VERSION "HNNBNNNYNNNNNNNNNNNNNNNNNNNNNNNNNNNNNNNNNN/4/%%%/4/'%**4NNN///"

NS_ :

BS_:

BU_: Aero_LB AFS_MLB Airbag_B8 BCM1_B8 Gateway_B8 Getriebe_AL551_651_B8 Getriebe_AL551_Q5_Hybrid Getriebe_SL_LB Lift_MLB_LB LWR_MLB Magnetic_Ride_LB Motor_MLB_AU48_AU416_Diesel Motor_MLB_B8_Q5_Otto Motor_MLB_Q5_Hybrid Niveau_LB Airbag_D4 BMS_Hybrid Daempfer_MLB EPB_MLB ESP Gateway Getriebe_AL551_951_D4_C7 Getriebe_AL551_Hybrid_D4_C7 Getriebe_DL382_MLB Getriebe_DL501_MLB Getriebe_VL381_MLB LEH_Hybrid LWS_D4 Motor2_MLB_D4_C7 Motor_MLB_AU64_AU57_Diesel Motor_MLB_BY_Otto Motor_MLB_C7_PHEV Motor_MLB_D4_C7_Hybrid Motor_MLB_D4_C7_Otto QSP SAK SAK2 SCR_MLB SCU

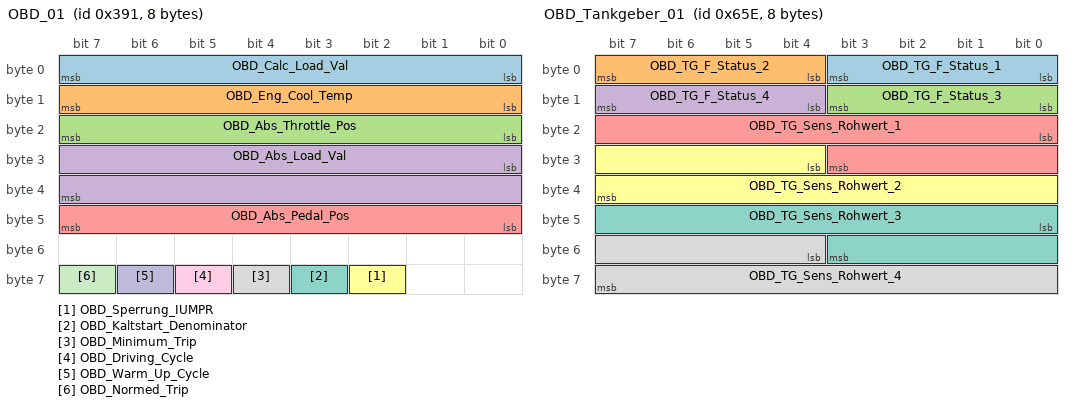
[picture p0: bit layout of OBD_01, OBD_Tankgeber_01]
BO_ 913 OBD_01: 8 Motor_MLB_AU64_AU57_Diesel
 SG_ OBD_Calc_Load_Val : 0|8@1+ (0.392156862745098,0) [0|100] "Unit_PerCent"  BMS_Hybrid,Gateway,Getriebe_AL551_951_D4_C7,Getriebe_AL551_Hybrid_D4_C7,Getriebe_DL382_MLB,Getriebe_DL501_MLB,Getriebe_VL381_MLB,LEH_Hybrid
 SG_ OBD_Eng_Cool_Temp : 8|8@1+ (1,-40) [-40|215] "Unit_DegreCelsi"  BMS_Hybrid,Gateway,Getriebe_AL551_951_D4_C7,Getriebe_AL551_Hybrid_D4_C7,Getriebe_DL382_MLB,Getriebe_DL501_MLB,Getriebe_VL381_MLB,LEH_Hybrid
 SG_ OBD_Abs_Throttle_Pos : 16|8@1+ (0.392156862745098,0) [0|100] "Unit_PerCent"  BMS_Hybrid,Gateway,Getriebe_AL551_951_D4_C7,Getriebe_AL551_Hybrid_D4_C7,Getriebe_DL382_MLB,Getriebe_DL501_MLB,Getriebe_VL381_MLB,LEH_Hybrid
 SG_ OBD_Abs_Load_Val : 24|16@1+ (0.392156862745098,0) [0|25700] "Unit_PerCent"  BMS_Hybrid,Gateway,Getriebe_AL551_951_D4_C7,Getriebe_AL551_Hybrid_D4_C7,Getriebe_DL382_MLB,Getriebe_DL501_MLB,Getriebe_VL381_MLB,LEH_Hybrid
 SG_ OBD_Abs_Pedal_Pos : 40|8@1+ (0.392156862745098,0) [0|100] "Unit_PerCent"  BMS_Hybrid,Gateway,Getriebe_AL551_951_D4_C7,Getriebe_AL551_Hybrid_D4_C7,Getriebe_DL382_MLB,Getriebe_DL501_MLB,Getriebe_VL381_MLB,LEH_Hybrid
 SG_ OBD_Sperrung_IUMPR : 58|1@1+ (1,0) [0|1] ""  BMS_Hybrid,Gateway,Getriebe_AL551_951_D4_C7,Getriebe_AL551_Hybrid_D4_C7,Getriebe_DL382_MLB,Getriebe_DL501_MLB,Getriebe_VL381_MLB,LEH_Hybrid
 SG_ OBD_Kaltstart_Denominator : 59|1@1+ (1,0) [0|1] ""  BMS_Hybrid,Gateway,LEH_Hybrid
 SG_ OBD_Minimum_Trip : 60|1@1+ (1,0) [0|1] ""  BMS_Hybrid,Gateway,Getriebe_AL551_951_D4_C7,Getriebe_AL551_Hybrid_D4_C7,Getriebe_DL382_MLB,Getriebe_DL501_MLB,Getriebe_VL381_MLB,LEH_Hybrid
 SG_ OBD_Driving_Cycle : 61|1@1+ (1,0) [0|1] ""  BMS_Hybrid,Gateway,Getriebe_AL551_951_D4_C7,Getriebe_AL551_Hybrid_D4_C7,Getriebe_DL382_MLB,Getriebe_DL501_MLB,Getriebe_VL381_MLB,LEH_Hybrid
 SG_ OBD_Warm_Up_Cycle : 62|1@1+ (1,0) [0|1] ""  BMS_Hybrid,Gateway,Getriebe_AL551_951_D4_C7,Getriebe_AL551_Hybrid_D4_C7,Getriebe_DL382_MLB,Getriebe_DL501_MLB,Getriebe_VL381_MLB,LEH_Hybrid
 SG_ OBD_Normed_Trip : 63|1@1+ (1,0) [0|1] ""  Gateway,Getriebe_AL551_951_D4_C7,Getriebe_AL551_Hybrid_D4_C7,Getriebe_DL382_MLB,Getriebe_DL501_MLB,Getriebe_VL381_MLB,LEH_Hybrid

BO_ 1630 OBD_Tankgeber_01: 8 Gateway
 SG_ OBD_TG_F_Status_1 : 0|4@1+ (1,0) [0|15] ""  Motor_MLB_AU64_AU57_Diesel,Motor_MLB_BY_Otto,Motor_MLB_C7_PHEV,Motor_MLB_D4_C7_Hybrid,Motor_MLB_D4_C7_Otto
 SG_ OBD_TG_F_Status_2 : 4|4@1+ (1,0) [0|15] ""  Motor_MLB_AU64_AU57_Diesel,Motor_MLB_BY_Otto,Motor_MLB_C7_PHEV,Motor_MLB_D4_C7_Hybrid,Motor_MLB_D4_C7_Otto
 SG_ OBD_TG_F_Status_3 : 8|4@1+ (1,0) [0|15] ""  Motor_MLB_AU64_AU57_Diesel,Motor_MLB_BY_Otto,Motor_MLB_C7_PHEV,Motor_MLB_D4_C7_Hybrid,Motor_MLB_D4_C7_Otto
 SG_ OBD_TG_F_Status_4 : 12|4@1+ (1,0) [0|15] ""  Motor_MLB_AU64_AU57_Diesel,Motor_MLB_BY_Otto,Motor_MLB_C7_PHEV,Motor_MLB_D4_C7_Hybrid,Motor_MLB_D4_C7_Otto
 SG_ OBD_TG_Sens_Rohwert_1 : 16|12@1+ (0.5,0) [0|2047.5] "Unit_Ohm"  Motor_MLB_AU64_AU57_Diesel,Motor_MLB_BY_Otto,Motor_MLB_C7_PHEV,Motor_MLB_D4_C7_Hybrid,Motor_MLB_D4_C7_Otto
 SG_ OBD_TG_Sens_Rohwert_2 : 28|12@1+ (0.5,0) [0|2047.5] "Unit_Ohm"  Motor_MLB_AU64_AU57_Diesel,Motor_MLB_BY_Otto,Motor_MLB_C7_PHEV,Motor_MLB_D4_C7_Hybrid,Motor_MLB_D4_C7_Otto
 SG_ OBD_TG_Sens_Rohwert_3 : 40|12@1+ (0.5,0) [0|2047.5] "Unit_Ohm"  Motor_MLB_AU64_AU57_Diesel,Motor_MLB_BY_Otto,Motor_MLB_C7_PHEV,Motor_MLB_D4_C7_Hybrid,Motor_MLB_D4_C7_Otto
 SG_ OBD_TG_Sens_Rohwert_4 : 52|12@1+ (0.5,0) [0|2047.5] "Unit_Ohm"  Motor_MLB_AU64_AU57_Diesel,Motor_MLB_BY_Otto,Motor_MLB_C7_PHEV,Motor_MLB_D4_C7_Hybrid,Motor_MLB_D4_C7_Otto

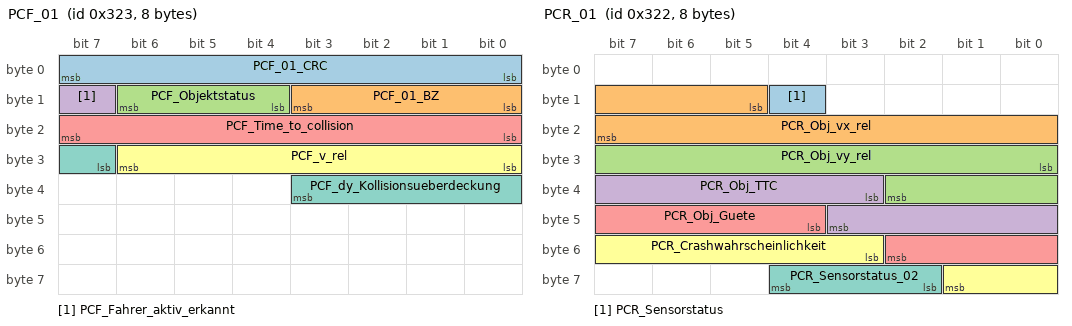
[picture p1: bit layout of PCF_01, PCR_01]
BO_ 803 PCF_01: 8 Gateway
 SG_ PCF_01_CRC : 0|8@1+ (1,0) [0|255] ""  Airbag_D4
 SG_ PCF_01_BZ : 8|4@1+ (1,0) [0|15] ""  Airbag_D4
 SG_ PCF_Objektstatus : 12|3@1+ (1,0) [0|7] ""  Airbag_D4
 SG_ PCF_Fahrer_aktiv_erkannt : 15|1@1+ (1,0) [0|1] "" Vector__XXX
 SG_ PCF_Time_to_collision : 16|8@1+ (0.01,0) [0|2.5] "Unit_Secon"  Airbag_D4
 SG_ PCF_v_rel : 24|7@1+ (0.5,0) [0.5|63.5] "Unit_MeterPerSecon"  Airbag_D4
 SG_ PCF_dy_Kollisionsueberdeckung : 31|5@1+ (0.1,0) [0.1|2.9] "Unit_Meter" Vector__XXX

BO_ 802 PCR_01: 8 Gateway
 SG_ PCR_Sensorstatus : 12|1@1+ (1,0) [0|1] ""  Airbag_D4
 SG_ PCR_Obj_vx_rel : 13|11@1+ (0.1,-102.3) [-102.3|102.3] "Unit_MeterPerSecon"  Airbag_D4
 SG_ PCR_Obj_vy_rel : 24|11@1+ (0.1,-102.3) [-102.3|102.3] "Unit_MeterPerSecon"  Airbag_D4
 SG_ PCR_Obj_TTC : 35|9@1+ (0.01,0) [0|5.1] "Unit_Secon"  Airbag_D4
 SG_ PCR_Obj_Guete : 44|7@1+ (1,0) [0|100] "Unit_PerCent"  Airbag_D4
 SG_ PCR_Crashwahrscheinlichkeit : 51|7@1+ (1,0) [0|100] "Unit_PerCent"  Airbag_D4
 SG_ PCR_Sensorstatus_02 : 58|3@1+ (1,0) [0|7] "" Vector__XXX

BO_ 929 PSD_01: 8 Gateway
 SG_ PSD_Pos_Segment_ID : 0|6@1+ (1,0) [2|63] ""  Getriebe_AL551_951_D4_C7,Getriebe_AL551_Hybrid_D4_C7,Getriebe_DL382_MLB,Getriebe_DL501_MLB,Getriebe_VL381_MLB,Motor_MLB_C7_PHEV,Motor_MLB_D4_C7_Hybrid,Motor_MLB_D4_C7_Otto
 SG_ PSD_Pos_Segmentlaenge : 6|7@1+ (2,0) [0|254] "Unit_Meter"  Getriebe_AL551_951_D4_C7,Getriebe_AL551_Hybrid_D4_C7,Getriebe_DL382_MLB,Getriebe_DL501_MLB,Getriebe_VL381_MLB,Motor_MLB_C7_PHEV,Motor_MLB_D4_C7_Hybrid,Motor_MLB_D4_C7_Otto
 SG_ PSD_Pos_Inhibitzeit : 13|5@1+ (10,0) [0|310] "Unit_MilliSecon"  Getriebe_AL551_951_D4_C7,Getriebe_AL551_Hybrid_D4_C7,Getriebe_DL382_MLB,Getriebe_DL501_MLB,Getriebe_VL381_MLB,Motor_MLB_C7_PHEV,Motor_MLB_D4_C7_Hybrid,Motor_MLB_D4_C7_Otto
 SG_ PSD_Pos_Standort : 18|1@1+ (1,0) [0|1] ""  Getriebe_AL551_951_D4_C7,Getriebe_AL551_Hybrid_D4_C7,Getriebe_DL382_MLB,Getriebe_DL501_MLB,Getriebe_VL381_MLB,Motor_MLB_C7_PHEV,Motor_MLB_D4_C7_Hybrid,Motor_MLB_D4_C7_Otto
 SG_ PSD_Pos_Laengsfehler : 19|3@1+ (1,0) [0|7] ""  Getriebe_AL551_951_D4_C7,Getriebe_AL551_Hybrid_D4_C7,Getriebe_DL382_MLB,Getriebe_DL501_MLB,Getriebe_VL381_MLB,Motor_MLB_C7_PHEV,Motor_MLB_D4_C7_Hybrid,Motor_MLB_D4_C7_Otto
 SG_ PSD_Segment_ID : 22|6@1+ (1,0) [2|63] ""  Getriebe_AL551_951_D4_C7,Getriebe_AL551_Hybrid_D4_C7,Getriebe_DL382_MLB,Getriebe_DL501_MLB,Getriebe_VL381_MLB,Motor_MLB_C7_PHEV,Motor_MLB_D4_C7_Hybrid,Motor_MLB_D4_C7_Otto
 SG_ PSD_Vorgaenger_Segment_ID : 28|6@1+ (1,0) [2|63] ""  Getriebe_AL551_951_D4_C7,Getriebe_AL551_Hybrid_D4_C7,Getriebe_DL382_MLB,Getriebe_DL501_MLB,Getriebe_VL381_MLB,Motor_MLB_C7_PHEV,Motor_MLB_D4_C7_Hybrid,Motor_MLB_D4_C7_Otto
 SG_ PSD_Strassenklasse : 34|2@1+ (1,0) [0|3] ""  Getriebe_AL551_951_D4_C7,Getriebe_AL551_Hybrid_D4_C7,Getriebe_DL382_MLB,Getriebe_DL501_MLB,Getriebe_VL381_MLB,Motor_MLB_C7_PHEV,Motor_MLB_D4_C7_Hybrid,Motor_MLB_D4_C7_Otto
 SG_ PSD_Segmentlaenge : 36|7@1+ (2,0) [0|254] "Unit_Meter"  Getriebe_AL551_951_D4_C7,Getriebe_AL551_Hybrid_D4_C7,Getriebe_DL382_MLB,Getriebe_DL501_MLB,Getriebe_VL381_MLB,Motor_MLB_C7_PHEV,Motor_MLB_D4_C7_Hybrid,Motor_MLB_D4_C7_Otto
 SG_ PSD_Rampe : 43|2@1+ (1,0) [0|3] ""  Getriebe_AL551_951_D4_C7,Getriebe_AL551_Hybrid_D4_C7,Getriebe_DL382_MLB,Getriebe_DL501_MLB,Getriebe_VL381_MLB,Motor_MLB_C7_PHEV,Motor_MLB_D4_C7_Hybrid,Motor_MLB_D4_C7_Otto
 SG_ PSD_Endkruemmung : 45|8@1+ (1,0) [0|254] "Unit_None"  Getriebe_AL551_951_D4_C7,Getriebe_AL551_Hybrid_D4_C7,Getriebe_DL382_MLB,Getriebe_DL501_MLB,Getriebe_VL381_MLB,Motor_MLB_C7_PHEV,Motor_MLB_D4_C7_Hybrid,Motor_MLB_D4_C7_Otto
 SG_ PSD_Endkruemmung_Vorz : 53|1@1+ (1,0) [0|1] ""  Getriebe_AL551_951_D4_C7,Getriebe_AL551_Hybrid_D4_C7,Getriebe_DL382_MLB,Getriebe_DL501_MLB,Getriebe_VL381_MLB,Motor_MLB_C7_PHEV,Motor_MLB_D4_C7_Hybrid,Motor_MLB_D4_C7_Otto
 SG_ PSD_Endsteigung : 54|5@1+ (0.5,0) [0|14.5] "Unit_PerCent"  Getriebe_AL551_951_D4_C7,Getriebe_AL551_Hybrid_D4_C7,Getriebe_DL382_MLB,Getriebe_DL501_MLB,Getriebe_VL381_MLB,Motor_MLB_C7_PHEV,Motor_MLB_D4_C7_Hybrid,Motor_MLB_D4_C7_Otto
 SG_ PSD_Endsteigung_Vorz : 59|1@1+ (1,0) [0|1] ""  Getriebe_AL551_951_D4_C7,Getriebe_AL551_Hybrid_D4_C7,Getriebe_DL382_MLB,Getriebe_DL501_MLB,Getriebe_VL381_MLB,Motor_MLB_C7_PHEV,Motor_MLB_D4_C7_Hybrid,Motor_MLB_D4_C7_Otto
 SG_ PSD_ADAS_Qualitaet : 60|1@1+ (1,0) [0|1] ""  Getriebe_AL551_951_D4_C7,Getriebe_AL551_Hybrid_D4_C7,Getriebe_DL382_MLB,Getriebe_DL501_MLB,Getriebe_VL381_MLB,Motor_MLB_C7_PHEV,Motor_MLB_D4_C7_Hybrid,Motor_MLB_D4_C7_Otto
 SG_ PSD_Fahrspuren : 61|2@1+ (1,0) [0|3] ""  Getriebe_AL551_951_D4_C7,Getriebe_AL551_Hybrid_D4_C7,Getriebe_DL382_MLB,Getriebe_DL501_MLB,Getriebe_VL381_MLB,Motor_MLB_C7_PHEV,Motor_MLB_D4_C7_Hybrid,Motor_MLB_D4_C7_Otto
 SG_ PSD_wahrscheinlichster_Pfad : 63|1@1+ (1,0) [0|1] ""  Getriebe_AL551_951_D4_C7,Getriebe_AL551_Hybrid_D4_C7,Getriebe_DL382_MLB,Getriebe_DL501_MLB,Getriebe_VL381_MLB,Motor_MLB_C7_PHEV,Motor_MLB_D4_C7_Hybrid,Motor_MLB_D4_C7_Otto

BO_ 930 PSD_02: 8 Gateway
 SG_ PSD_Multiplex M : 0|2@1+ (1,0) [0|3] ""  Getriebe_AL551_951_D4_C7,Getriebe_AL551_Hybrid_D4_C7,Getriebe_DL382_MLB,Getriebe_DL501_MLB,Getriebe_VL381_MLB,Motor_MLB_C7_PHEV,Motor_MLB_D4_C7_Hybrid,Motor_MLB_D4_C7_Otto
 SG_ PSD_Sys_Segment_ID m0 : 2|6@1+ (1,0) [2|63] ""  Getriebe_AL551_951_D4_C7,Getriebe_AL551_Hybrid_D4_C7,Getriebe_DL382_MLB,Getriebe_DL501_MLB,Getriebe_VL381_MLB,Motor_MLB_C7_PHEV,Motor_MLB_D4_C7_Hybrid,Motor_MLB_D4_C7_Otto
 SG_ PSD_Abz_Segment_ID m1 : 2|6@1+ (1,0) [2|63] ""  Getriebe_AL551_951_D4_C7,Getriebe_AL551_Hybrid_D4_C7,Getriebe_DL382_MLB,Getriebe_DL501_MLB,Getriebe_VL381_MLB,Motor_MLB_C7_PHEV,Motor_MLB_D4_C7_Hybrid,Motor_MLB_D4_C7_Otto
 SG_ PSD_Ges_Segment_ID m2 : 2|6@1+ (1,0) [2|63] ""  Getriebe_AL551_951_D4_C7,Getriebe_AL551_Hybrid_D4_C7,Getriebe_DL382_MLB,Getriebe_DL501_MLB,Getriebe_VL381_MLB,Motor_MLB_C7_PHEV,Motor_MLB_D4_C7_Hybrid,Motor_MLB_D4_C7_Otto
 SG_ PSD_Ort_Laenge_VZ m3 : 2|1@1+ (1,0) [0|1] ""  Getriebe_AL551_951_D4_C7,Getriebe_AL551_Hybrid_D4_C7,Getriebe_DL382_MLB,Getriebe_DL501_MLB,Getriebe_VL381_MLB,Motor_MLB_C7_PHEV,Motor_MLB_D4_C7_Hybrid,Motor_MLB_D4_C7_Otto
 SG_ PSD_Ort_Laenge m3 : 3|25@1+ (1E-005,0) [0|180] "Unit_DegreOfArc"  Getriebe_AL551_951_D4_C7,Getriebe_AL551_Hybrid_D4_C7,Getriebe_DL382_MLB,Getriebe_DL501_MLB,Getriebe_VL381_MLB,Motor_MLB_C7_PHEV,Motor_MLB_D4_C7_Hybrid,Motor_MLB_D4_C7_Otto
 SG_ PSD_Sys_Laendercode m0 : 8|8@1+ (1,0) [0|255] ""  Getriebe_AL551_951_D4_C7,Getriebe_AL551_Hybrid_D4_C7,Getriebe_DL382_MLB,Getriebe_DL501_MLB,Getriebe_VL381_MLB,Motor_MLB_C7_PHEV,Motor_MLB_D4_C7_Hybrid,Motor_MLB_D4_C7_Otto
 SG_ PSD_Abz_Segmentlaenge m1 : 8|7@1+ (2,0) [0|254] "Unit_Meter"  Getriebe_AL551_951_D4_C7,Getriebe_AL551_Hybrid_D4_C7,Getriebe_DL382_MLB,Getriebe_DL501_MLB,Getriebe_VL381_MLB,Motor_MLB_C7_PHEV,Motor_MLB_D4_C7_Hybrid,Motor_MLB_D4_C7_Otto
 SG_ PSD_Ges_Geschwindigkeit m2 : 8|5@1+ (1,0) [0|31] ""  Getriebe_AL551_951_D4_C7,Getriebe_AL551_Hybrid_D4_C7,Getriebe_DL382_MLB,Getriebe_DL501_MLB,Getriebe_VL381_MLB,Motor_MLB_C7_PHEV,Motor_MLB_D4_C7_Hybrid,Motor_MLB_D4_C7_Otto
 SG_ PSD_Ges_Geschwindigkeit_Typ m2 : 13|1@1+ (1,0) [0|1] ""  Getriebe_AL551_951_D4_C7,Getriebe_AL551_Hybrid_D4_C7,Getriebe_DL382_MLB,Getriebe_DL501_MLB,Getriebe_VL381_MLB,Motor_MLB_C7_PHEV,Motor_MLB_D4_C7_Hybrid,Motor_MLB_D4_C7_Otto
 SG_ PSD_Ges_Geschwindigkeit_Gespann m2 : 14|2@1+ (1,0) [0|3] ""  Getriebe_AL551_951_D4_C7,Getriebe_AL551_Hybrid_D4_C7,Getriebe_DL382_MLB,Getriebe_DL501_MLB,Getriebe_VL381_MLB,Motor_MLB_C7_PHEV,Motor_MLB_D4_C7_Hybrid,Motor_MLB_D4_C7_Otto
 SG_ PSD_Abz_Vorgaenger_Segment_ID m1 : 15|6@1+ (1,0) [2|63] ""  Getriebe_AL551_951_D4_C7,Getriebe_AL551_Hybrid_D4_C7,Getriebe_DL382_MLB,Getriebe_DL501_MLB,Getriebe_VL381_MLB,Motor_MLB_C7_PHEV,Motor_MLB_D4_C7_Hybrid,Motor_MLB_D4_C7_Otto
 SG_ PSD_Sys_Geschwindigkeit_Einheit m0 : 16|1@1+ (1,0) [0|1] ""  Getriebe_AL551_951_D4_C7,Getriebe_AL551_Hybrid_D4_C7,Getriebe_DL382_MLB,Getriebe_DL501_MLB,Getriebe_VL381_MLB,Motor_MLB_C7_PHEV,Motor_MLB_D4_C7_Hybrid,Motor_MLB_D4_C7_Otto
 SG_ PSD_Ges_Geschwindigkeit_Witter m2 : 16|2@1+ (1,0) [0|3] ""  Getriebe_AL551_951_D4_C7,Getriebe_AL551_Hybrid_D4_C7,Getriebe_DL382_MLB,Getriebe_DL501_MLB,Getriebe_VL381_MLB,Motor_MLB_C7_PHEV,Motor_MLB_D4_C7_Hybrid,Motor_MLB_D4_C7_Otto
 SG_ PSD_Sys_Verkehrsrichtung m0 : 17|1@1+ (1,0) [0|1] ""  Getriebe_AL551_951_D4_C7,Getriebe_AL551_Hybrid_D4_C7,Getriebe_DL382_MLB,Getriebe_DL501_MLB,Getriebe_VL381_MLB,Motor_MLB_C7_PHEV,Motor_MLB_D4_C7_Hybrid,Motor_MLB_D4_C7_Otto
 SG_ PSD_Sys_Release_Monat m0 : 18|4@1+ (1,0) [1|12] "Unit_Month"  Getriebe_AL551_951_D4_C7,Getriebe_AL551_Hybrid_D4_C7,Getriebe_DL382_MLB,Getriebe_DL501_MLB,Getriebe_VL381_MLB,Motor_MLB_C7_PHEV,Motor_MLB_D4_C7_Hybrid,Motor_MLB_D4_C7_Otto
 SG_ PSD_Ges_Geschwindigkeit_Tag_Anf m2 : 18|3@1+ (1,0) [0|7] ""  Getriebe_AL551_951_D4_C7,Getriebe_AL551_Hybrid_D4_C7,Getriebe_DL382_MLB,Getriebe_DL501_MLB,Getriebe_VL381_MLB,Motor_MLB_C7_PHEV,Motor_MLB_D4_C7_Hybrid,Motor_MLB_D4_C7_Otto
 SG_ PSD_Abz_Geschwindigkeit m1 : 21|5@1+ (1,0) [0|31] ""  Getriebe_AL551_951_D4_C7,Getriebe_AL551_Hybrid_D4_C7,Getriebe_DL382_MLB,Getriebe_DL501_MLB,Getriebe_VL381_MLB,Motor_MLB_C7_PHEV,Motor_MLB_D4_C7_Hybrid,Motor_MLB_D4_C7_Otto
 SG_ PSD_Ges_Geschwindigkeit_Tag_Ende m2 : 21|3@1+ (1,0) [0|7] ""  Getriebe_AL551_951_D4_C7,Getriebe_AL551_Hybrid_D4_C7,Getriebe_DL382_MLB,Getriebe_DL501_MLB,Getriebe_VL381_MLB,Motor_MLB_C7_PHEV,Motor_MLB_D4_C7_Hybrid,Motor_MLB_D4_C7_Otto
 SG_ PSD_Sys_Release_Jahr m0 : 22|5@1+ (1,2000) [2000|2031] "Unit_Year"  Getriebe_AL551_951_D4_C7,Getriebe_AL551_Hybrid_D4_C7,Getriebe_DL382_MLB,Getriebe_DL501_MLB,Getriebe_VL381_MLB,Motor_MLB_C7_PHEV,Motor_MLB_D4_C7_Hybrid,Motor_MLB_D4_C7_Otto
 SG_ PSD_Ges_Geschwindigkeit_Std_Anf m2 : 24|5@1+ (1,0) [0|24] "Unit_Hours"  Getriebe_AL551_951_D4_C7,Getriebe_AL551_Hybrid_D4_C7,Getriebe_DL382_MLB,Getriebe_DL501_MLB,Getriebe_VL381_MLB,Motor_MLB_C7_PHEV,Motor_MLB_D4_C7_Hybrid,Motor_MLB_D4_C7_Otto
 SG_ PSD_Abz_Geschwindigkeit_Typ m1 : 26|1@1+ (1,0) [0|1] ""  Getriebe_AL551_951_D4_C7,Getriebe_AL551_Hybrid_D4_C7,Getriebe_DL382_MLB,Getriebe_DL501_MLB,Getriebe_VL381_MLB,Motor_MLB_C7_PHEV,Motor_MLB_D4_C7_Hybrid,Motor_MLB_D4_C7_Otto
 SG_ PSD_Sys_Tunnel m0 : 27|1@1+ (1,0) [0|1] ""  Getriebe_AL551_951_D4_C7,Getriebe_AL551_Hybrid_D4_C7,Getriebe_DL382_MLB,Getriebe_DL501_MLB,Getriebe_VL381_MLB,Motor_MLB_C7_PHEV,Motor_MLB_D4_C7_Hybrid,Motor_MLB_D4_C7_Otto
 SG_ PSD_Abz_Strassenklasse m1 : 27|2@1+ (1,0) [0|3] ""  Getriebe_AL551_951_D4_C7,Getriebe_AL551_Hybrid_D4_C7,Getriebe_DL382_MLB,Getriebe_DL501_MLB,Getriebe_VL381_MLB,Motor_MLB_C7_PHEV,Motor_MLB_D4_C7_Hybrid,Motor_MLB_D4_C7_Otto
 SG_ PSD_Sys_Bruecke m0 : 28|1@1+ (1,0) [0|1] ""  Getriebe_AL551_951_D4_C7,Getriebe_AL551_Hybrid_D4_C7,Getriebe_DL382_MLB,Getriebe_DL501_MLB,Getriebe_VL381_MLB,Motor_MLB_C7_PHEV,Motor_MLB_D4_C7_Hybrid,Motor_MLB_D4_C7_Otto
 SG_ PSD_Ort_Breite_VZ m3 : 28|1@1+ (1,0) [0|1] ""  Getriebe_AL551_951_D4_C7,Getriebe_AL551_Hybrid_D4_C7,Getriebe_DL382_MLB,Getriebe_DL501_MLB,Getriebe_VL381_MLB,Motor_MLB_C7_PHEV,Motor_MLB_D4_C7_Hybrid,Motor_MLB_D4_C7_Otto
 SG_ PSD_Sys_Fahrsp_Gegenr m0 : 29|2@1+ (1,0) [0|3] ""  Getriebe_AL551_951_D4_C7,Getriebe_AL551_Hybrid_D4_C7,Getriebe_DL382_MLB,Getriebe_DL501_MLB,Getriebe_VL381_MLB,Motor_MLB_C7_PHEV,Motor_MLB_D4_C7_Hybrid,Motor_MLB_D4_C7_Otto
 SG_ PSD_Abz_ADAS_Qualitaet m1 : 29|1@1+ (1,0) [0|1] ""  Getriebe_AL551_951_D4_C7,Getriebe_AL551_Hybrid_D4_C7,Getriebe_DL382_MLB,Getriebe_DL501_MLB,Getriebe_VL381_MLB,Motor_MLB_C7_PHEV,Motor_MLB_D4_C7_Hybrid,Motor_MLB_D4_C7_Otto
 SG_ PSD_Ges_Geschwindigkeit_Std_Ende m2 : 29|5@1+ (1,0) [0|24] "Unit_Hours"  Getriebe_AL551_951_D4_C7,Getriebe_AL551_Hybrid_D4_C7,Getriebe_DL382_MLB,Getriebe_DL501_MLB,Getriebe_VL381_MLB,Motor_MLB_C7_PHEV,Motor_MLB_D4_C7_Hybrid,Motor_MLB_D4_C7_Otto
 SG_ PSD_Ort_Breite m3 : 29|24@1+ (1E-005,0) [0|90] "Unit_DegreOfArc"  Getriebe_AL551_951_D4_C7,Getriebe_AL551_Hybrid_D4_C7,Getriebe_DL382_MLB,Getriebe_DL501_MLB,Getriebe_VL381_MLB,Motor_MLB_C7_PHEV,Motor_MLB_D4_C7_Hybrid,Motor_MLB_D4_C7_Otto
 SG_ PSD_Abz_Abzweigerichtung m1 : 30|1@1+ (1,0) [0|1] ""  Getriebe_AL551_951_D4_C7,Getriebe_AL551_Hybrid_D4_C7,Getriebe_DL382_MLB,Getriebe_DL501_MLB,Getriebe_VL381_MLB,Motor_MLB_C7_PHEV,Motor_MLB_D4_C7_Hybrid,Motor_MLB_D4_C7_Otto
 SG_ PSD_Sys_TMC_Baustelle m0 : 31|1@1+ (1,0) [0|1] ""  Getriebe_AL551_951_D4_C7,Getriebe_AL551_Hybrid_D4_C7,Getriebe_DL382_MLB,Getriebe_DL501_MLB,Getriebe_VL381_MLB,Motor_MLB_C7_PHEV,Motor_MLB_D4_C7_Hybrid,Motor_MLB_D4_C7_Otto
 SG_ PSD_Abz_Abzweigewinkel m1 : 31|4@1+ (1,0) [0|15] ""  Getriebe_AL551_951_D4_C7,Getriebe_AL551_Hybrid_D4_C7,Getriebe_DL382_MLB,Getriebe_DL501_MLB,Getriebe_VL381_MLB,Motor_MLB_C7_PHEV,Motor_MLB_D4_C7_Hybrid,Motor_MLB_D4_C7_Otto
 SG_ PSD_Sys_TMC_Stau m0 : 32|1@1+ (1,0) [0|1] ""  Getriebe_AL551_951_D4_C7,Getriebe_AL551_Hybrid_D4_C7,Getriebe_DL382_MLB,Getriebe_DL501_MLB,Getriebe_VL381_MLB,Motor_MLB_C7_PHEV,Motor_MLB_D4_C7_Hybrid,Motor_MLB_D4_C7_Otto
 SG_ PSD_Sys_Bauliche_Trennung m0 : 33|2@1+ (1,0) [0|3] "" Vector__XXX
 SG_ PSD_Ges_alter_Geschw m2 : 34|5@1+ (1,0) [0|31] ""  Getriebe_AL551_951_D4_C7,Getriebe_AL551_Hybrid_D4_C7,Getriebe_DL382_MLB,Getriebe_DL501_MLB,Getriebe_VL381_MLB,Motor_MLB_C7_PHEV,Motor_MLB_D4_C7_Hybrid,Motor_MLB_D4_C7_Otto
 SG_ PSD_Sys_Geometrieguete m0 : 35|2@1+ (1,0) [0|3] ""  Getriebe_AL551_951_D4_C7,Getriebe_AL551_Hybrid_D4_C7,Getriebe_DL382_MLB,Getriebe_DL501_MLB,Getriebe_VL381_MLB,Motor_MLB_C7_PHEV,Motor_MLB_D4_C7_Hybrid,Motor_MLB_D4_C7_Otto
 SG_ PSD_Abz_Rampe m1 : 35|2@1+ (1,0) [0|3] ""  Getriebe_AL551_951_D4_C7,Getriebe_AL551_Hybrid_D4_C7,Getriebe_DL382_MLB,Getriebe_DL501_MLB,Getriebe_VL381_MLB,Motor_MLB_C7_PHEV,Motor_MLB_D4_C7_Hybrid,Motor_MLB_D4_C7_Otto
 SG_ PSD_Sys_Maut m0 : 37|1@1+ (1,0) [0|1] "" Vector__XXX
 SG_ PSD_Abz_Anfangskruemmung m1 : 37|8@1+ (1,0) [0|254] "Unit_None"  Getriebe_AL551_951_D4_C7,Getriebe_AL551_Hybrid_D4_C7,Getriebe_DL382_MLB,Getriebe_DL501_MLB,Getriebe_VL381_MLB,Motor_MLB_C7_PHEV,Motor_MLB_D4_C7_Hybrid,Motor_MLB_D4_C7_Otto
 SG_ PSD_Sys_Strassensituation m0 : 38|2@1+ (1,0) [0|3] "" Vector__XXX
 SG_ PSD_Ges_alter_Geschw_Gespann m2 : 39|2@1+ (1,0) [0|3] ""  Getriebe_AL551_951_D4_C7,Getriebe_AL551_Hybrid_D4_C7,Getriebe_DL382_MLB,Getriebe_DL501_MLB,Getriebe_VL381_MLB,Motor_MLB_C7_PHEV,Motor_MLB_D4_C7_Hybrid,Motor_MLB_D4_C7_Otto
 SG_ PSD_Sys_StrKlassen_erweitert m0 : 40|3@1+ (1,0) [0|7] "" Vector__XXX
 SG_ PSD_Ges_alter_Geschw_Witter m2 : 41|2@1+ (1,0) [0|3] ""  Getriebe_AL551_951_D4_C7,Getriebe_AL551_Hybrid_D4_C7,Getriebe_DL382_MLB,Getriebe_DL501_MLB,Getriebe_VL381_MLB,Motor_MLB_C7_PHEV,Motor_MLB_D4_C7_Hybrid,Motor_MLB_D4_C7_Otto
 SG_ PSD_Sys_Ortsschild m0 : 43|1@1+ (1,0) [0|1] ""  Getriebe_AL551_951_D4_C7,Getriebe_AL551_Hybrid_D4_C7,Getriebe_DL382_MLB,Getriebe_DL501_MLB,Getriebe_VL381_MLB,Motor_MLB_C7_PHEV,Motor_MLB_D4_C7_Hybrid,Motor_MLB_D4_C7_Otto
 SG_ PSD_Ges_alter_Geschw_Tag_Anf m2 : 43|3@1+ (1,0) [0|7] ""  Getriebe_AL551_951_D4_C7,Getriebe_AL551_Hybrid_D4_C7,Getriebe_DL382_MLB,Getriebe_DL501_MLB,Getriebe_VL381_MLB,Motor_MLB_C7_PHEV,Motor_MLB_D4_C7_Hybrid,Motor_MLB_D4_C7_Otto
 SG_ PSD_Abz_Anfangskruemmung_Vorz m1 : 45|1@1+ (1,0) [0|1] ""  Getriebe_AL551_951_D4_C7,Getriebe_AL551_Hybrid_D4_C7,Getriebe_DL382_MLB,Getriebe_DL501_MLB,Getriebe_VL381_MLB,Motor_MLB_C7_PHEV,Motor_MLB_D4_C7_Hybrid,Motor_MLB_D4_C7_Otto
 SG_ PSD_Sys_Anfangskruemmung m0 : 46|8@1+ (1,0) [0|254] "Unit_None"  Getriebe_AL551_951_D4_C7,Getriebe_AL551_Hybrid_D4_C7,Getriebe_DL382_MLB,Getriebe_DL501_MLB,Getriebe_VL381_MLB,Motor_MLB_C7_PHEV,Motor_MLB_D4_C7_Hybrid,Motor_MLB_D4_C7_Otto
 SG_ PSD_Abz_Endkruemmung m1 : 46|8@1+ (1,0) [0|254] "Unit_None"  Getriebe_AL551_951_D4_C7,Getriebe_AL551_Hybrid_D4_C7,Getriebe_DL382_MLB,Getriebe_DL501_MLB,Getriebe_VL381_MLB,Motor_MLB_C7_PHEV,Motor_MLB_D4_C7_Hybrid,Motor_MLB_D4_C7_Otto
 SG_ PSD_Ges_alter_Geschw_Tag_Ende m2 : 46|3@1+ (1,0) [0|7] ""  Getriebe_AL551_951_D4_C7,Getriebe_AL551_Hybrid_D4_C7,Getriebe_DL382_MLB,Getriebe_DL501_MLB,Getriebe_VL381_MLB,Motor_MLB_C7_PHEV,Motor_MLB_D4_C7_Hybrid,Motor_MLB_D4_C7_Otto
 SG_ PSD_Ges_alter_Geschw_Std_Anf m2 : 49|5@1+ (1,0) [0|24] "Unit_Hours"  Getriebe_AL551_951_D4_C7,Getriebe_AL551_Hybrid_D4_C7,Getriebe_DL382_MLB,Getriebe_DL501_MLB,Getriebe_VL381_MLB,Motor_MLB_C7_PHEV,Motor_MLB_D4_C7_Hybrid,Motor_MLB_D4_C7_Otto
 SG_ PSD_Ort_Hoehe m3 : 53|11@1+ (5,-1000) [-1000|8000] "Unit_Meter"  Getriebe_AL551_951_D4_C7,Getriebe_AL551_Hybrid_D4_C7,Getriebe_DL382_MLB,Getriebe_DL501_MLB,Getriebe_VL381_MLB,Motor_MLB_C7_PHEV,Motor_MLB_D4_C7_Hybrid,Motor_MLB_D4_C7_Otto
 SG_ PSD_Sys_Anfangskruemmung_Vorz m0 : 54|1@1+ (1,0) [0|1] ""  Getriebe_AL551_951_D4_C7,Getriebe_AL551_Hybrid_D4_C7,Getriebe_DL382_MLB,Getriebe_DL501_MLB,Getriebe_VL381_MLB,Motor_MLB_C7_PHEV,Motor_MLB_D4_C7_Hybrid,Motor_MLB_D4_C7_Otto
 SG_ PSD_Abz_Endkruemmung_Vorz m1 : 54|1@1+ (1,0) [0|1] ""  Getriebe_AL551_951_D4_C7,Getriebe_AL551_Hybrid_D4_C7,Getriebe_DL382_MLB,Getriebe_DL501_MLB,Getriebe_VL381_MLB,Motor_MLB_C7_PHEV,Motor_MLB_D4_C7_Hybrid,Motor_MLB_D4_C7_Otto
 SG_ PSD_Ges_alter_Geschw_Std_Ende m2 : 54|5@1+ (1,0) [0|24] "Unit_Hours"  Getriebe_AL551_951_D4_C7,Getriebe_AL551_Hybrid_D4_C7,Getriebe_DL382_MLB,Getriebe_DL501_MLB,Getriebe_VL381_MLB,Motor_MLB_C7_PHEV,Motor_MLB_D4_C7_Hybrid,Motor_MLB_D4_C7_Otto
 SG_ PSD_Sys_Anfangssteigung m0 : 55|5@1+ (0.5,0) [0|14.5] "Unit_PerCent"  Getriebe_AL551_951_D4_C7,Getriebe_AL551_Hybrid_D4_C7,Getriebe_DL382_MLB,Getriebe_DL501_MLB,Getriebe_VL381_MLB,Motor_MLB_C7_PHEV,Motor_MLB_D4_C7_Hybrid,Motor_MLB_D4_C7_Otto
 SG_ PSD_Abz_Endsteigung m1 : 55|5@1+ (0.5,0) [0|14.5] "Unit_PerCent"  Getriebe_AL551_951_D4_C7,Getriebe_AL551_Hybrid_D4_C7,Getriebe_DL382_MLB,Getriebe_DL501_MLB,Getriebe_VL381_MLB,Motor_MLB_C7_PHEV,Motor_MLB_D4_C7_Hybrid,Motor_MLB_D4_C7_Otto
 SG_ PSD_Ges_Ueberholverbot m2 : 59|2@1+ (1,0) [0|3] ""  Getriebe_AL551_951_D4_C7,Getriebe_AL551_Hybrid_D4_C7,Getriebe_DL382_MLB,Getriebe_DL501_MLB,Getriebe_VL381_MLB,Motor_MLB_C7_PHEV,Motor_MLB_D4_C7_Hybrid,Motor_MLB_D4_C7_Otto
 SG_ PSD_Sys_Anfangssteigung_Vorz m0 : 60|1@1+ (1,0) [0|1] ""  Getriebe_AL551_951_D4_C7,Getriebe_AL551_Hybrid_D4_C7,Getriebe_DL382_MLB,Getriebe_DL501_MLB,Getriebe_VL381_MLB,Motor_MLB_C7_PHEV,Motor_MLB_D4_C7_Hybrid,Motor_MLB_D4_C7_Otto
 SG_ PSD_Abz_Endsteigung_Vorz m1 : 60|1@1+ (1,0) [0|1] ""  Getriebe_AL551_951_D4_C7,Getriebe_AL551_Hybrid_D4_C7,Getriebe_DL382_MLB,Getriebe_DL501_MLB,Getriebe_VL381_MLB,Motor_MLB_C7_PHEV,Motor_MLB_D4_C7_Hybrid,Motor_MLB_D4_C7_Otto
 SG_ PSD_Sys_Ortschaft m0 : 61|1@1+ (1,0) [0|1] ""  Getriebe_AL551_951_D4_C7,Getriebe_AL551_Hybrid_D4_C7,Getriebe_DL382_MLB,Getriebe_DL501_MLB,Getriebe_VL381_MLB,Motor_MLB_C7_PHEV,Motor_MLB_D4_C7_Hybrid,Motor_MLB_D4_C7_Otto
 SG_ PSD_Abz_Fahrspuren m1 : 61|2@1+ (1,0) [0|3] ""  Getriebe_AL551_951_D4_C7,Getriebe_AL551_Hybrid_D4_C7,Getriebe_DL382_MLB,Getriebe_DL501_MLB,Getriebe_VL381_MLB,Motor_MLB_C7_PHEV,Motor_MLB_D4_C7_Hybrid,Motor_MLB_D4_C7_Otto
 SG_ PSD_Ges_Wechselverkehrszeichen m2 : 61|3@1+ (1,0) [0|7] ""  Getriebe_AL551_951_D4_C7,Getriebe_AL551_Hybrid_D4_C7,Getriebe_DL382_MLB,Getriebe_DL501_MLB,Getriebe_VL381_MLB,Motor_MLB_C7_PHEV,Motor_MLB_D4_C7_Hybrid,Motor_MLB_D4_C7_Otto
 SG_ PSD_Sys_Digitalisierung m0 : 62|1@1+ (1,0) [0|1] ""  Getriebe_AL551_951_D4_C7,Getriebe_AL551_Hybrid_D4_C7,Getriebe_DL382_MLB,Getriebe_DL501_MLB,Getriebe_VL381_MLB,Motor_MLB_C7_PHEV,Motor_MLB_D4_C7_Hybrid,Motor_MLB_D4_C7_Otto
 SG_ PSD_Sys_Zielfuehrung m0 : 63|1@1+ (1,0) [0|1] ""  Getriebe_AL551_951_D4_C7,Getriebe_AL551_Hybrid_D4_C7,Getriebe_DL382_MLB,Getriebe_DL501_MLB,Getriebe_VL381_MLB,Motor_MLB_C7_PHEV,Motor_MLB_D4_C7_Hybrid,Motor_MLB_D4_C7_Otto
 SG_ PSD_Abz_wahrscheinlichster_Pfad m1 : 63|1@1+ (1,0) [0|1] ""  Getriebe_AL551_951_D4_C7,Getriebe_AL551_Hybrid_D4_C7,Getriebe_DL382_MLB,Getriebe_DL501_MLB,Getriebe_VL381_MLB,Motor_MLB_C7_PHEV,Motor_MLB_D4_C7_Hybrid,Motor_MLB_D4_C7_Otto

BO_ 2033 Request_Airbag_Deployment: 8 Gateway
 SG_ Request_Airbag_Deployment : 0|64@1+ (1,0) [0|1.84467440737096E+019] ""  Airbag_D4

BO_ 2041 Response_Airbag_Deployment: 8 Airbag_D4
 SG_ Response_Airbag_Deployment : 0|64@1+ (1,0) [0|1.84467440737096E+019] ""  Gateway

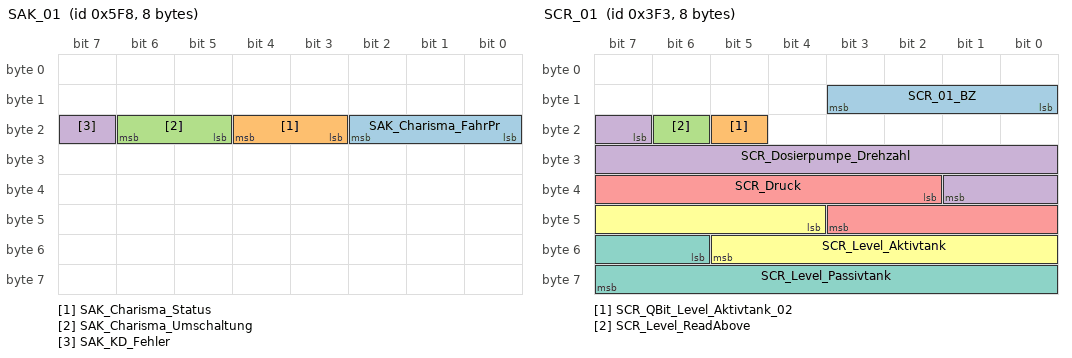
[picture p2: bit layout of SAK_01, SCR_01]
BO_ 1528 SAK_01: 8 SAK
 SG_ SAK_Charisma_FahrPr : 16|3@1+ (1,0) [0|7] ""  Gateway
 SG_ SAK_Charisma_Status : 19|2@1+ (1,0) [0|3] ""  Gateway
 SG_ SAK_Charisma_Umschaltung : 21|2@1+ (1,0) [0|3] ""  Gateway
 SG_ SAK_KD_Fehler : 23|1@1+ (1,0) [0|1] ""  Gateway

BO_ 1011 SCR_01: 8 SCR_MLB
 SG_ SCR_01_BZ : 8|4@1+ (1,0) [0|15] ""  Motor_MLB_AU64_AU57_Diesel
 SG_ SCR_QBit_Level_Aktivtank_02 : 21|1@1+ (1,0) [0|1] "" Vector__XXX
 SG_ SCR_Level_ReadAbove : 22|1@1+ (1,0) [0|1] "" Vector__XXX
 SG_ SCR_Dosierpumpe_Drehzahl : 23|11@1+ (4,-4080) [-4080|4100] "Unit_MinutInver"  Motor_MLB_AU64_AU57_Diesel
 SG_ SCR_Druck : 34|10@1+ (5,0) [0|5000] "Unit_MilliVolt"  Motor_MLB_AU64_AU57_Diesel
 SG_ SCR_Level_Aktivtank : 44|10@1+ (5,0) [0|5000] "Unit_MilliVolt"  Motor_MLB_AU64_AU57_Diesel
 SG_ SCR_Level_Passivtank : 54|10@1+ (5,0) [0|5000] "Unit_MilliVolt"  Motor_MLB_AU64_AU57_Diesel

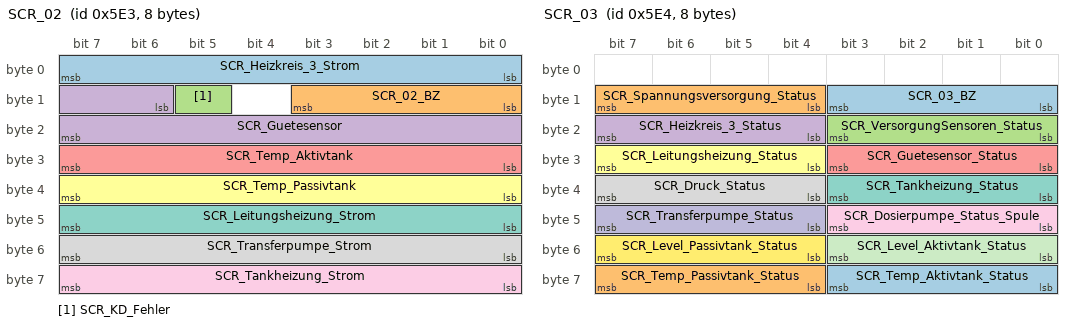
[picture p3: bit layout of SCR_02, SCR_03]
BO_ 1507 SCR_02: 8 SCR_MLB
 SG_ SCR_Heizkreis_3_Strom : 0|8@1+ (0.1,0) [0|14] "Unit_Amper"  Motor_MLB_AU64_AU57_Diesel
 SG_ SCR_02_BZ : 8|4@1+ (1,0) [0|15] ""  Motor_MLB_AU64_AU57_Diesel
 SG_ SCR_KD_Fehler : 13|1@1+ (1,0) [0|1] ""  Gateway
 SG_ SCR_Guetesensor : 14|10@1+ (5,0) [0|5000] "Unit_MilliVolt"  Motor_MLB_AU64_AU57_Diesel
 SG_ SCR_Temp_Aktivtank : 24|8@1+ (20,0) [0|5000] "Unit_MilliVolt"  Motor_MLB_AU64_AU57_Diesel
 SG_ SCR_Temp_Passivtank : 32|8@1+ (20,0) [0|5000] "Unit_MilliVolt"  Motor_MLB_AU64_AU57_Diesel
 SG_ SCR_Leitungsheizung_Strom : 40|8@1+ (0.1,0) [0|14] "Unit_Amper"  Motor_MLB_AU64_AU57_Diesel
 SG_ SCR_Transferpumpe_Strom : 48|8@1+ (0.1,0) [0|14] "Unit_Amper"  Motor_MLB_AU64_AU57_Diesel
 SG_ SCR_Tankheizung_Strom : 56|8@1+ (0.1,0) [0|14] "Unit_Amper"  Motor_MLB_AU64_AU57_Diesel

BO_ 1508 SCR_03: 8 SCR_MLB
 SG_ SCR_03_BZ : 8|4@1+ (1,0) [0|15] ""  Motor_MLB_AU64_AU57_Diesel
 SG_ SCR_Spannungsversorgung_Status : 12|4@1+ (1,0) [0|15] ""  Motor_MLB_AU64_AU57_Diesel
 SG_ SCR_VersorgungSensoren_Status : 16|4@1+ (1,0) [0|15] ""  Motor_MLB_AU64_AU57_Diesel
 SG_ SCR_Heizkreis_3_Status : 20|4@1+ (1,0) [0|15] ""  Motor_MLB_AU64_AU57_Diesel
 SG_ SCR_Guetesensor_Status : 24|4@1+ (1,0) [0|15] ""  Motor_MLB_AU64_AU57_Diesel
 SG_ SCR_Leitungsheizung_Status : 28|4@1+ (1,0) [0|15] ""  Motor_MLB_AU64_AU57_Diesel
 SG_ SCR_Tankheizung_Status : 32|4@1+ (1,0) [0|15] ""  Motor_MLB_AU64_AU57_Diesel
 SG_ SCR_Druck_Status : 36|4@1+ (1,0) [0|15] ""  Motor_MLB_AU64_AU57_Diesel
 SG_ SCR_Dosierpumpe_Status_Spule : 40|4@1+ (1,0) [0|15] ""  Motor_MLB_AU64_AU57_Diesel
 SG_ SCR_Transferpumpe_Status : 44|4@1+ (1,0) [0|15] ""  Motor_MLB_AU64_AU57_Diesel
 SG_ SCR_Level_Aktivtank_Status : 48|4@1+ (1,0) [0|15] ""  Motor_MLB_AU64_AU57_Diesel
 SG_ SCR_Level_Passivtank_Status : 52|4@1+ (1,0) [0|15] ""  Motor_MLB_AU64_AU57_Diesel
 SG_ SCR_Temp_Aktivtank_Status : 56|4@1+ (1,0) [0|15] ""  Motor_MLB_AU64_AU57_Diesel
 SG_ SCR_Temp_Passivtank_Status : 60|4@1+ (1,0) [0|15] ""  Motor_MLB_AU64_AU57_Diesel

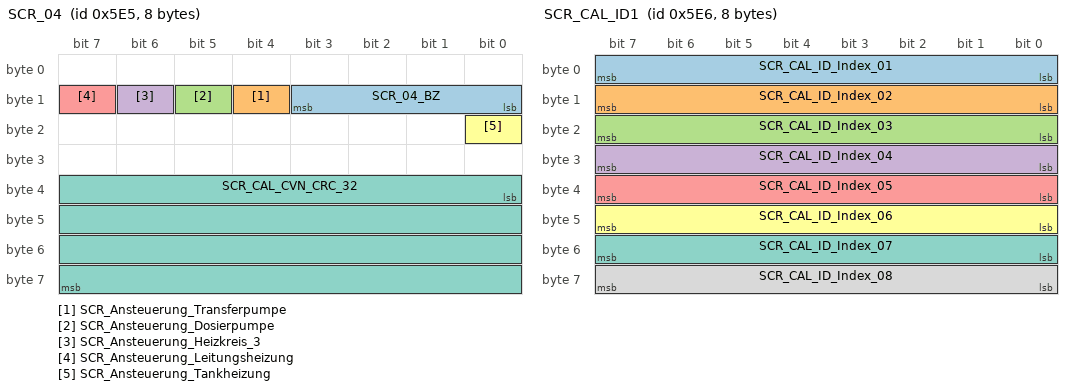
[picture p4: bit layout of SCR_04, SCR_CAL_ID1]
BO_ 1509 SCR_04: 8 SCR_MLB
 SG_ SCR_04_BZ : 8|4@1+ (1,0) [0|15] ""  Motor_MLB_AU64_AU57_Diesel
 SG_ SCR_Ansteuerung_Transferpumpe : 12|1@1+ (1,0) [0|1] ""  Motor_MLB_AU64_AU57_Diesel
 SG_ SCR_Ansteuerung_Dosierpumpe : 13|1@1+ (1,0) [0|1] ""  Motor_MLB_AU64_AU57_Diesel
 SG_ SCR_Ansteuerung_Heizkreis_3 : 14|1@1+ (1,0) [0|1] ""  Motor_MLB_AU64_AU57_Diesel
 SG_ SCR_Ansteuerung_Leitungsheizung : 15|1@1+ (1,0) [0|1] ""  Motor_MLB_AU64_AU57_Diesel
 SG_ SCR_Ansteuerung_Tankheizung : 16|1@1+ (1,0) [0|1] ""  Motor_MLB_AU64_AU57_Diesel
 SG_ SCR_CAL_CVN_CRC_32 : 32|32@1+ (1,0) [0|4294967295] ""  Motor_MLB_AU64_AU57_Diesel

BO_ 1526 SCR_05: 8 SCR_MLB
 SG_ SCR_05_BZ : 8|4@1+ (1,0) [0|15] ""  Motor_MLB_AU64_AU57_Diesel
 SG_ SCR_Level_Aktivtank_OOR4Quality : 12|1@1+ (1,0) [0|1] "" Vector__XXX
 SG_ SCR_Level_Aktivtank_OOR_minus : 13|1@1+ (1,0) [0|1] "" Vector__XXX
 SG_ SCR_Sent_1_Signalstatus : 14|2@1+ (1,0) [0|3] "" Vector__XXX
 SG_ SCR_Sent_1_elektrischer_Status : 16|4@1+ (1,0) [0|15] "" Vector__XXX
 SG_ SCR_Sent_Levelsensor : 20|3@1+ (1,0) [0|7] "" Vector__XXX
 SG_ SCR_Sent_Qualitaetssensor : 23|3@1+ (1,0) [0|7] "" Vector__XXX
 SG_ SCR_Sent_Temperatursensor : 26|3@1+ (1,0) [0|7] "" Vector__XXX
 SG_ SCR_DEF_Qualitaet_Medium : 29|1@1+ (1,0) [0|1] "" Vector__XXX
 SG_ SCR_QBit_Qualitaet : 30|1@1+ (1,0) [0|1] "" Vector__XXX
 SG_ SCR_Qualitaet : 40|8@1+ (0.5,-20) [-20|100] "Unit_PerCent" Vector__XXX
 SG_ SCR_Steuergeraet_Heizung_Status : 48|2@1+ (1,0) [0|3] ""  Motor_MLB_AU64_AU57_Diesel
 SG_ SCR_Steuergeraet_Pumpe_Status : 50|2@1+ (1,0) [0|3] ""  Motor_MLB_AU64_AU57_Diesel
 SG_ SCR_Steuergeraet_Relais_Status : 52|2@1+ (1,0) [0|3] ""  Motor_MLB_AU64_AU57_Diesel
 SG_ SCR_Steuergeraet_Bus_Status : 56|2@1+ (1,0) [0|3] ""  Motor_MLB_AU64_AU57_Diesel
 SG_ SCR_Steuergeraet_Datensatz_St002 : 60|2@1+ (1,0) [0|3] ""  Motor_MLB_AU64_AU57_Diesel
 SG_ SCR_Steuergeraet_Defekt_Status : 62|2@1+ (1,0) [0|3] ""  Motor_MLB_AU64_AU57_Diesel

BO_ 1510 SCR_CAL_ID1: 8 SCR_MLB
 SG_ SCR_CAL_ID_Index_01 : 0|8@1+ (1,0) [0|255] ""  Motor_MLB_AU64_AU57_Diesel
 SG_ SCR_CAL_ID_Index_02 : 8|8@1+ (1,0) [0|255] ""  Motor_MLB_AU64_AU57_Diesel
 SG_ SCR_CAL_ID_Index_03 : 16|8@1+ (1,0) [0|255] ""  Motor_MLB_AU64_AU57_Diesel
 SG_ SCR_CAL_ID_Index_04 : 24|8@1+ (1,0) [0|255] ""  Motor_MLB_AU64_AU57_Diesel
 SG_ SCR_CAL_ID_Index_05 : 32|8@1+ (1,0) [0|255] ""  Motor_MLB_AU64_AU57_Diesel
 SG_ SCR_CAL_ID_Index_06 : 40|8@1+ (1,0) [0|255] ""  Motor_MLB_AU64_AU57_Diesel
 SG_ SCR_CAL_ID_Index_07 : 48|8@1+ (1,0) [0|255] ""  Motor_MLB_AU64_AU57_Diesel
 SG_ SCR_CAL_ID_Index_08 : 56|8@1+ (1,0) [0|255] ""  Motor_MLB_AU64_AU57_Diesel

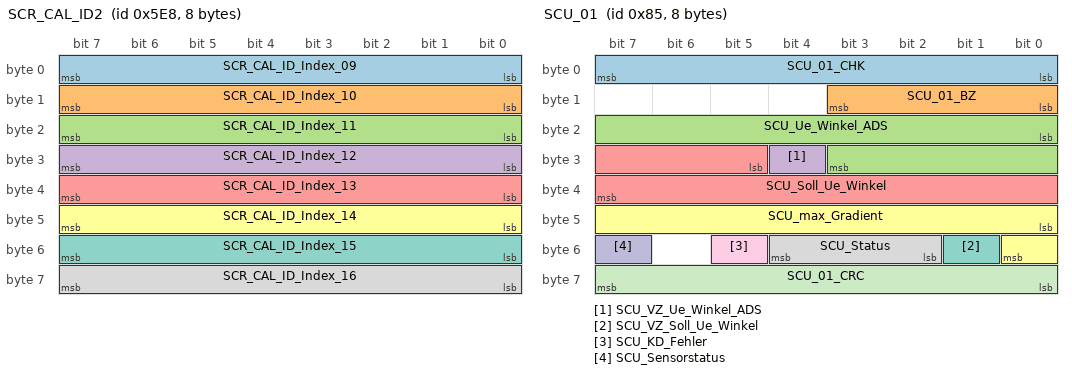
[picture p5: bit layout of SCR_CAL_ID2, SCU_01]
BO_ 1512 SCR_CAL_ID2: 8 SCR_MLB
 SG_ SCR_CAL_ID_Index_09 : 0|8@1+ (1,0) [0|255] ""  Motor_MLB_AU64_AU57_Diesel
 SG_ SCR_CAL_ID_Index_10 : 8|8@1+ (1,0) [0|255] ""  Motor_MLB_AU64_AU57_Diesel
 SG_ SCR_CAL_ID_Index_11 : 16|8@1+ (1,0) [0|255] ""  Motor_MLB_AU64_AU57_Diesel
 SG_ SCR_CAL_ID_Index_12 : 24|8@1+ (1,0) [0|255] ""  Motor_MLB_AU64_AU57_Diesel
 SG_ SCR_CAL_ID_Index_13 : 32|8@1+ (1,0) [0|255] ""  Motor_MLB_AU64_AU57_Diesel
 SG_ SCR_CAL_ID_Index_14 : 40|8@1+ (1,0) [0|255] ""  Motor_MLB_AU64_AU57_Diesel
 SG_ SCR_CAL_ID_Index_15 : 48|8@1+ (1,0) [0|255] ""  Motor_MLB_AU64_AU57_Diesel
 SG_ SCR_CAL_ID_Index_16 : 56|8@1+ (1,0) [0|255] ""  Motor_MLB_AU64_AU57_Diesel

BO_ 133 SCU_01: 8 SCU
 SG_ SCU_01_CHK : 0|8@1+ (1,0) [0|255] ""  Airbag_D4,ESP,Gateway,Motor_MLB_AU64_AU57_Diesel,Motor_MLB_BY_Otto,Motor_MLB_C7_PHEV,Motor_MLB_D4_C7_Hybrid,Motor_MLB_D4_C7_Otto,QSP
 SG_ SCU_01_BZ : 8|4@1+ (1,0) [0|15] ""  Airbag_D4,ESP,Gateway,Motor_MLB_AU64_AU57_Diesel,Motor_MLB_BY_Otto,Motor_MLB_C7_PHEV,Motor_MLB_D4_C7_Hybrid,Motor_MLB_D4_C7_Otto,QSP
 SG_ SCU_Ue_Winkel_ADS : 16|12@1+ (0.1,0) [0|409.3] "Unit_DegreOfArc"  Airbag_D4,ESP,Gateway,Motor_MLB_AU64_AU57_Diesel,Motor_MLB_BY_Otto,Motor_MLB_C7_PHEV,Motor_MLB_D4_C7_Hybrid,Motor_MLB_D4_C7_Otto,QSP
 SG_ SCU_VZ_Ue_Winkel_ADS : 28|1@1+ (1,0) [0|1] ""  Airbag_D4,ESP,Gateway,Motor_MLB_AU64_AU57_Diesel,Motor_MLB_BY_Otto,Motor_MLB_C7_PHEV,Motor_MLB_D4_C7_Hybrid,Motor_MLB_D4_C7_Otto,QSP
 SG_ SCU_Soll_Ue_Winkel : 29|11@1+ (0.1,0) [0|204.5] "Unit_DegreOfArc"  ESP,Gateway,QSP
 SG_ SCU_max_Gradient : 40|9@1+ (1,0) [0|510] ""  ESP,Gateway
 SG_ SCU_VZ_Soll_Ue_Winkel : 49|1@1+ (1,0) [0|1] ""  ESP,Gateway,QSP
 SG_ SCU_Status : 50|3@1+ (1,0) [0|7] ""  ESP,Gateway
 SG_ SCU_KD_Fehler : 53|1@1+ (1,0) [0|1] ""  ESP,Gateway
 SG_ SCU_Sensorstatus : 55|1@1+ (1,0) [0|1] ""  Gateway
 SG_ SCU_01_CRC : 56|8@1+ (1,0) [0|255] ""  ESP,Gateway,QSP

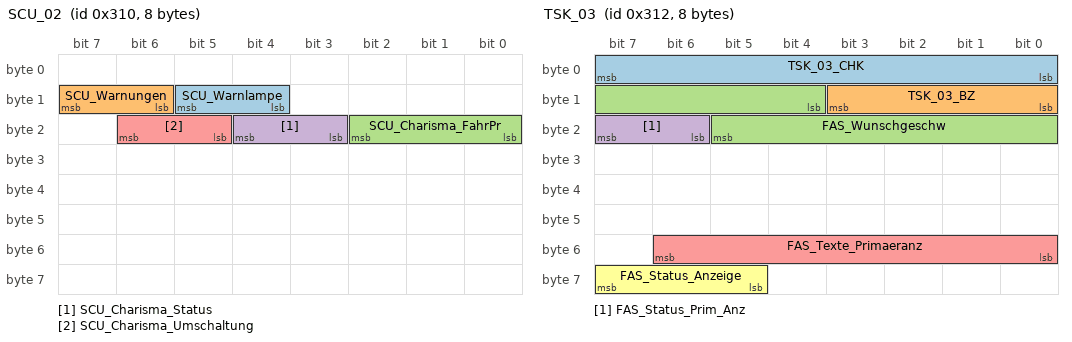
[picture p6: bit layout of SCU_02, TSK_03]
BO_ 784 SCU_02: 8 SCU
 SG_ SCU_Warnlampe : 12|2@1+ (1,0) [0|3] ""  Gateway
 SG_ SCU_Warnungen : 14|2@1+ (1,0) [0|3] ""  Gateway
 SG_ SCU_Charisma_FahrPr : 16|3@1+ (1,0) [0|7] ""  Gateway
 SG_ SCU_Charisma_Status : 19|2@1+ (1,0) [0|3] ""  Gateway
 SG_ SCU_Charisma_Umschaltung : 21|2@1+ (1,0) [0|3] ""  Gateway

BO_ 2549875324 SKey_EMotor_01_Req: 8 Gateway
 SG_ SK2_Key_Req_Data : 0|64@1+ (1,0) [0|1.84467440737096E+019] ""  LEH_Hybrid

BO_ 2550006396 SKey_EMotor_01_Resp: 8 LEH_Hybrid
 SG_ SK2_Key_Resp_Data : 0|64@1+ (1,0) [0|1.84467440737096E+019] ""  Gateway

BO_ 2549875319 SKey_Getriebe_01_Req: 8 Gateway
 SG_ SK2_Key_Req_Data : 0|64@1+ (1,0) [0|1.84467440737096E+019] ""  Getriebe_AL551_951_D4_C7,Getriebe_AL551_Hybrid_D4_C7,Getriebe_DL382_MLB,Getriebe_DL501_MLB,Getriebe_VL381_MLB

BO_ 2550006391 SKey_Getriebe_01_Resp: 8 Getriebe_AL551_951_D4_C7
 SG_ SK2_Key_Resp_Data : 0|64@1+ (1,0) [0|1.84467440737096E+019] ""  Gateway

BO_ 2549875323 SKey_Hybrid_01_Req: 8 Gateway
 SG_ SK2_Key_Req_Data : 0|64@1+ (1,0) [0|1.84467440737096E+019] ""  BMS_Hybrid

BO_ 2550006395 SKey_Hybrid_01_Resp: 8 BMS_Hybrid
 SG_ SK2_Key_Resp_Data : 0|64@1+ (1,0) [0|1.84467440737096E+019] ""  Gateway

BO_ 2549875318 SKey_MO_01_Req: 8 Gateway
 SG_ SK2_Key_Req_Data : 0|64@1+ (1,0) [0|1.84467440737096E+019] ""  Motor_MLB_AU64_AU57_Diesel,Motor_MLB_C7_PHEV,Motor_MLB_D4_C7_Hybrid,Motor_MLB_D4_C7_Otto

BO_ 2550006390 SKey_MO_01_Resp: 8 Motor_MLB_AU64_AU57_Diesel
 SG_ SK2_Key_Resp_Data : 0|64@1+ (1,0) [0|1.84467440737096E+019] ""  Gateway

BO_ 2549875320 SKey_MOS_01_Req: 8 Gateway
 SG_ SK2_Key_Req_Data : 0|64@1+ (1,0) [0|1.84467440737096E+019] ""  Motor2_MLB_D4_C7

BO_ 2550006392 SKey_MOS_01_Resp: 8 Motor2_MLB_D4_C7
 SG_ SK2_Key_Resp_Data : 0|64@1+ (1,0) [0|1.84467440737096E+019] ""  Gateway

BO_ 1313 STH_01: 8 Gateway
 SG_ STH_Funk_ein : 0|1@1+ (1,0) [0|1] "" Vector__XXX
 SG_ STH_Funk_aus : 1|1@1+ (1,0) [0|1] "" Vector__XXX
 SG_ STH_Zusatzheizung : 2|1@1+ (1,0) [0|1] "" Vector__XXX
 SG_ STH_LED : 3|1@1+ (1,0) [0|1] ""  Motor_MLB_AU64_AU57_Diesel,Motor_MLB_BY_Otto,Motor_MLB_C7_PHEV,Motor_MLB_D4_C7_Hybrid,Motor_MLB_D4_C7_Otto
 SG_ STH_Pumpe_ein : 4|1@1+ (1,0) [0|1] "" Vector__XXX
 SG_ STH_Geblaese : 5|1@1+ (1,0) [0|1] "" Vector__XXX
 SG_ STH_EKP_Anst : 6|1@1+ (1,0) [0|1] ""  Motor_MLB_AU64_AU57_Diesel,Motor_MLB_BY_Otto,Motor_MLB_C7_PHEV,Motor_MLB_D4_C7_Hybrid,Motor_MLB_D4_C7_Otto
 SG_ STH_Start_folgt : 7|1@1+ (1,0) [0|1] "" Vector__XXX
 SG_ STH_Ventiloeffnungszeit : 8|6@1+ (1,0) [0|63] "Unit_Minut" Vector__XXX
 SG_ STH_Ventil_Status : 14|1@1+ (1,0) [0|1] "" Vector__XXX
 SG_ STH_Fehler_ElWaPu : 15|1@1+ (1,0) [0|1] ""  Motor_MLB_AU64_AU57_Diesel,Motor_MLB_BY_Otto,Motor_MLB_C7_PHEV,Motor_MLB_D4_C7_Hybrid,Motor_MLB_D4_C7_Otto
 SG_ STH_Waermeeintrag : 16|6@1+ (1,0) [0|63] "" Vector__XXX
 SG_ STH_Pumpen_Anf_extern : 22|1@1+ (1,0) [0|1] "" Vector__XXX
 SG_ STH_KVS : 24|13@1+ (1,0) [0|8191] "Unit_MilliLiter" Vector__XXX
 SG_ STH_Fehlerstatus : 37|3@1+ (1,0) [0|7] "" Vector__XXX
 SG_ STH_Heizleistung : 40|8@1+ (1,0) [0|255] "" Vector__XXX
 SG_ STH_Wassertemp : 48|8@1+ (0.75,-40) [-40|142.25] "Unit_DegreCelsi" Vector__XXX
 SG_ STH_Texte : 56|3@1+ (1,0) [0|7] "" Vector__XXX
 SG_ STH_Motorvorwaermung : 59|1@1+ (1,0) [0|1] ""  Motor_MLB_AU64_AU57_Diesel,Motor_MLB_BY_Otto,Motor_MLB_C7_PHEV,Motor_MLB_D4_C7_Hybrid,Motor_MLB_D4_C7_Otto
 SG_ STH_Servicemode : 60|1@1+ (1,0) [0|1] "" Vector__XXX
 SG_ STH_war_aktiv : 61|1@1+ (1,0) [0|1] ""  Motor_MLB_AU64_AU57_Diesel,Motor_MLB_BY_Otto,Motor_MLB_C7_PHEV,Motor_MLB_D4_C7_Hybrid,Motor_MLB_D4_C7_Otto
 SG_ STH_KVS_Ueberlauf : 62|1@1+ (1,0) [0|1] "" Vector__XXX
 SG_ STH_KD_Fehler : 63|1@1+ (1,0) [0|1] "" Vector__XXX

BO_ 1172 STS_01: 8 Gateway
 SG_ STS_01_CHK : 0|8@1+ (1,0) [0|255] ""  Motor_MLB_AU64_AU57_Diesel,Motor_MLB_BY_Otto,Motor_MLB_C7_PHEV,Motor_MLB_D4_C7_Hybrid,Motor_MLB_D4_C7_Otto
 SG_ STS_01_BZ : 8|4@1+ (1,0) [0|15] ""  Motor_MLB_AU64_AU57_Diesel,Motor_MLB_BY_Otto,Motor_MLB_C7_PHEV,Motor_MLB_D4_C7_Hybrid,Motor_MLB_D4_C7_Otto
 SG_ STS_Car_not_under_theft : 12|1@1+ (1,0) [0|1] "" Vector__XXX
 SG_ STS_Car_under_theft : 13|1@1+ (1,0) [0|1] "" Vector__XXX
 SG_ STS_Anlassersperre : 15|1@1+ (1,0) [0|1] "" Vector__XXX
 SG_ STS_Typencodierung : 16|5@1+ (1,0) [0|31] "" Vector__XXX
 SG_ STS_KD_Fehler : 22|1@1+ (1,0) [0|1] "" Vector__XXX
 SG_ STS_LIN_aktiv : 23|1@1+ (1,0) [0|1] "" Vector__XXX
 SG_ STS_Standlicht : 24|1@1+ (1,0) [0|1] "" Vector__XXX
 SG_ STS_Fahrlicht : 25|1@1+ (1,0) [0|1] "" Vector__XXX
 SG_ STS_Alarm_still : 26|1@1+ (1,0) [0|1] "" Vector__XXX
 SG_ STS_Texte : 27|4@1+ (1,0) [0|15] "" Vector__XXX
 SG_ STS_Laderelais : 38|1@1+ (1,0) [0|1] "" Vector__XXX
 SG_ STS_Summer : 48|1@1+ (1,0) [0|1] "" Vector__XXX
 SG_ STS_Alarm_Blinker : 50|1@1+ (1,0) [0|1] "" Vector__XXX
 SG_ STS_Notstart : 51|1@1+ (1,0) [0|1] "" Vector__XXX
 SG_ STS_Signalhorn : 55|1@1+ (1,0) [0|1] "" Vector__XXX
 SG_ STS_Leerlaufschaltung : 56|1@1+ (1,0) [0|1] ""  Motor_MLB_AU64_AU57_Diesel,Motor_MLB_BY_Otto,Motor_MLB_C7_PHEV,Motor_MLB_D4_C7_Hybrid,Motor_MLB_D4_C7_Otto

BO_ 1413 Systeminfo_01: 8 Gateway
 SG_ SI_Int_CAN_gespiegelt : 0|1@1+ (1,0) [0|1] "" Vector__XXX
 SG_ SI_CAN_Komfort_Sleep : 1|1@1+ (1,0) [0|1] "" Vector__XXX
 SG_ SI_CAN_Dashboard_Sleep : 2|1@1+ (1,0) [0|1] "" Vector__XXX
 SG_ SI_CAN_Antrieb_Sleep : 3|1@1+ (1,0) [0|1] "" Vector__XXX
 SG_ SI_Infotainment_Sleep : 4|1@1+ (1,0) [0|1] "" Vector__XXX
 SG_ SI_CAN_Extended_Sleep : 5|1@1+ (1,0) [0|1] "" Vector__XXX
 SG_ SI_Fahrwerk_Sleep : 6|1@1+ (1,0) [0|1] "" Vector__XXX
 SG_ SI_Diagnose_Aktiv : 7|1@1+ (1,0) [0|1] "" Vector__XXX
 SG_ SI_QRS_Mode : 8|1@1+ (1,0) [0|1] ""  Getriebe_AL551_951_D4_C7,Getriebe_AL551_Hybrid_D4_C7
 SG_ SI_T_Mode : 9|1@1+ (1,0) [0|1] ""  EPB_MLB,Getriebe_AL551_951_D4_C7,Getriebe_AL551_Hybrid_D4_C7,Motor_MLB_AU64_AU57_Diesel,Motor_MLB_BY_Otto,Motor_MLB_C7_PHEV,Motor_MLB_D4_C7_Hybrid,Motor_MLB_D4_C7_Otto
 SG_ SI_NWDF : 10|1@1+ (1,0) [0|1] ""  SAK,SAK2
 SG_ SI_NWDF_gueltig : 11|1@1+ (1,0) [0|1] ""  SAK,SAK2
 SG_ SI_Sammelfehler : 12|1@1+ (1,0) [0|1] "" Vector__XXX
 SG_ GW_KD_Fehler : 13|1@1+ (1,0) [0|1] "" Vector__XXX
 SG_ SI_T_Schutz : 14|1@1+ (1,0) [0|1] "" Vector__XXX
 SG_ SI_MOST_Status : 15|1@1+ (1,0) [0|1] "" Vector__XXX
 SG_ SI_Sammel_SG_Fehler : 56|6@1+ (1,0) [0|60] "" Vector__XXX
 SG_ SI_CAN_Hybrid_Sleep : 62|1@1+ (1,0) [0|1] "" Vector__XXX
 SG_ SI_MO_WU : 63|1@1+ (1,0) [0|1] "" Vector__XXX

BO_ 1196 TPD_Daempfer_01: 8 Gateway
 SG_ TPD_Daempfer_Data_1 : 0|64@1+ (1,0) [0|1.84467440737096E+019] ""  Daempfer_MLB

BO_ 1214 TPD_SCU_01: 8 Gateway
 SG_ TPD_SCU_Data_1 : 0|64@1+ (1,0) [0|1.84467440737096E+019] ""  SCU

BO_ 768 TPD_Tester_01: 8 Daempfer_MLB
 SG_ TPD_Tester_Data_1 : 0|64@1+ (1,0) [0|1.84467440737096E+019] ""  Gateway

BO_ 769 TPD_Tester_02: 8 Daempfer_MLB
 SG_ TPD_Tester_Data_2 : 0|64@1+ (1,0) [0|1.84467440737096E+019] ""  Gateway

BO_ 770 TPD_Tester_03: 8 Daempfer_MLB
 SG_ TPD_Tester_Data_3 : 0|64@1+ (1,0) [0|1.84467440737096E+019] ""  Gateway

BO_ 771 TPD_Tester_04: 8 Daempfer_MLB
 SG_ TPD_Tester_Data_4 : 0|64@1+ (1,0) [0|1.84467440737096E+019] ""  Gateway

BO_ 772 TPD_Tester_05: 8 Daempfer_MLB
 SG_ TPD_Tester_Data_5 : 0|64@1+ (1,0) [0|1.84467440737096E+019] ""  Gateway

BO_ 773 TPD_Tester_06: 8 Daempfer_MLB
 SG_ TPD_Tester_Data_6 : 0|64@1+ (1,0) [0|1.84467440737096E+019] ""  Gateway

BO_ 774 TPD_Tester_07: 8 Daempfer_MLB
 SG_ TPD_Tester_Data_7 : 0|64@1+ (1,0) [0|1.84467440737096E+019] ""  Gateway

BO_ 775 TPD_Tester_08: 8 Daempfer_MLB
 SG_ TPD_Tester_Data_8 : 0|64@1+ (1,0) [0|1.84467440737096E+019] ""  Gateway

BO_ 524 TPS_Daempfer: 7 Daempfer_MLB
 SG_ TPS_Daempfer_Data : 0|56@1+ (1,0) [0|7.20575940379279E+016] ""  Gateway

BO_ 542 TPS_SCU: 7 SCU
 SG_ TPS_SCU_Data : 0|56@1+ (1,0) [0|7.20575940379279E+016] ""  Gateway

BO_ 512 TPS_Tester: 7 Gateway
 SG_ TPS_Tester_Data : 0|56@1+ (1,0) [0|7.20575940379279E+016] ""  Daempfer_MLB,SCU

BO_ 786 TSK_03: 8 Motor_MLB_AU64_AU57_Diesel
 SG_ TSK_03_CHK : 0|8@1+ (1,0) [0|255] ""  Gateway
 SG_ TSK_03_BZ : 8|4@1+ (1,0) [0|15] ""  Gateway
 SG_ FAS_Wunschgeschw : 12|10@1+ (0.32,0) [0|326.72] "Unit_KiloMeterPerHour"  Gateway
 SG_ FAS_Status_Prim_Anz : 22|2@1+ (1,0) [0|3] ""  Gateway
 SG_ FAS_Texte_Primaeranz : 48|7@1+ (1,0) [0|127] ""  Gateway
 SG_ FAS_Status_Anzeige : 61|3@1+ (1,0) [0|7] ""  Gateway

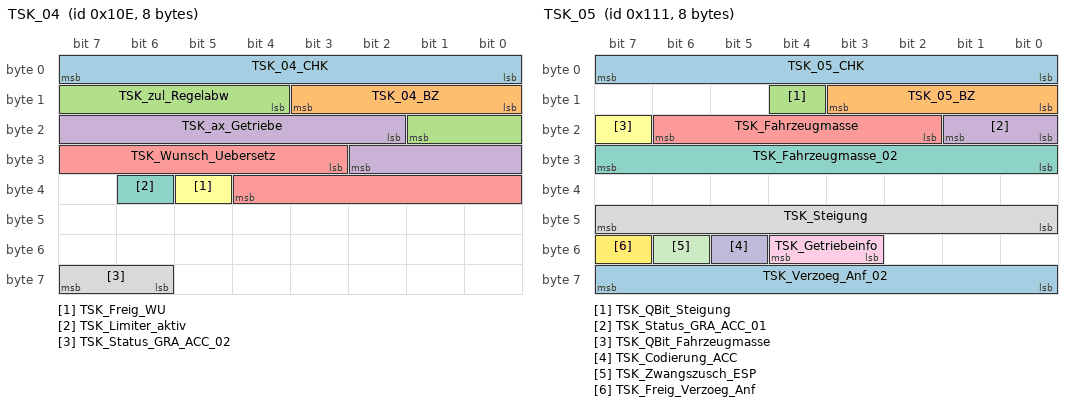
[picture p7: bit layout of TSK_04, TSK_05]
BO_ 270 TSK_04: 8 Motor_MLB_AU64_AU57_Diesel
 SG_ TSK_04_CHK : 0|8@1+ (1,0) [0|255] ""  Getriebe_AL551_951_D4_C7,Getriebe_AL551_Hybrid_D4_C7
 SG_ TSK_04_BZ : 8|4@1+ (1,0) [0|15] ""  Getriebe_AL551_951_D4_C7,Getriebe_AL551_Hybrid_D4_C7
 SG_ TSK_zul_Regelabw : 12|6@1+ (0.024,0) [0|1.512] "Unit_MeterPerSeconSquar"  Getriebe_AL551_951_D4_C7,Getriebe_AL551_Hybrid_D4_C7,Getriebe_DL382_MLB,Getriebe_DL501_MLB,Getriebe_VL381_MLB
 SG_ TSK_ax_Getriebe : 18|9@1+ (0.024,-2.016) [-2.016|10.224] "Unit_MeterPerSeconSquar"  Getriebe_AL551_951_D4_C7,Getriebe_AL551_Hybrid_D4_C7,Getriebe_DL382_MLB,Getriebe_DL501_MLB,Getriebe_VL381_MLB
 SG_ TSK_Wunsch_Uebersetz : 27|10@1+ (0.0245,0) [0.0245|25.0635] ""  Getriebe_AL551_951_D4_C7,Getriebe_AL551_Hybrid_D4_C7,Getriebe_DL382_MLB,Getriebe_DL501_MLB,Getriebe_VL381_MLB
 SG_ TSK_Freig_WU : 37|1@1+ (1,0) [0|1] ""  Getriebe_AL551_951_D4_C7,Getriebe_AL551_Hybrid_D4_C7,Getriebe_DL382_MLB,Getriebe_DL501_MLB,Getriebe_VL381_MLB
 SG_ TSK_Limiter_aktiv : 38|1@1+ (1,0) [0|1] ""  Getriebe_AL551_951_D4_C7,Getriebe_AL551_Hybrid_D4_C7,Getriebe_DL382_MLB,Getriebe_DL501_MLB,Getriebe_VL381_MLB
 SG_ TSK_Status_GRA_ACC_02 : 62|2@1+ (1,0) [0|3] ""  Getriebe_AL551_951_D4_C7,Getriebe_AL551_Hybrid_D4_C7,Getriebe_DL382_MLB,Getriebe_DL501_MLB,Getriebe_VL381_MLB

BO_ 273 TSK_05: 8 Motor_MLB_AU64_AU57_Diesel
 SG_ TSK_05_CHK : 0|8@1+ (1,0) [0|255] ""  EPB_MLB,Gateway,Getriebe_AL551_951_D4_C7,Getriebe_AL551_Hybrid_D4_C7
 SG_ TSK_05_BZ : 8|4@1+ (1,0) [0|15] ""  EPB_MLB,Gateway,Getriebe_AL551_951_D4_C7,Getriebe_AL551_Hybrid_D4_C7
 SG_ TSK_QBit_Steigung : 12|1@1+ (1,0) [0|1] ""  Gateway,Getriebe_AL551_951_D4_C7,Getriebe_AL551_Hybrid_D4_C7,Getriebe_DL382_MLB,Getriebe_DL501_MLB,Getriebe_VL381_MLB
 SG_ TSK_Status_GRA_ACC_01 : 16|2@1+ (1,0) [0|3] ""  Gateway
 SG_ TSK_Fahrzeugmasse : 18|5@1+ (200,500) [500|6500] "Unit_KiloGram"  Gateway
 SG_ TSK_QBit_Fahrzeugmasse : 23|1@1+ (1,0) [0|1] ""  Gateway,Getriebe_AL551_951_D4_C7,Getriebe_AL551_Hybrid_D4_C7,Getriebe_DL382_MLB,Getriebe_DL501_MLB,Getriebe_VL381_MLB
 SG_ TSK_Fahrzeugmasse_02 : 24|8@1+ (32,0) [0|8128] "Unit_KiloGram"  Gateway,Getriebe_AL551_951_D4_C7,Getriebe_AL551_Hybrid_D4_C7,Getriebe_DL382_MLB,Getriebe_DL501_MLB,Getriebe_VL381_MLB
 SG_ TSK_Steigung : 40|8@1+ (0.8,-101.6) [-101.6|101.6] "Unit_PerCent"  Gateway,Getriebe_AL551_951_D4_C7,Getriebe_AL551_Hybrid_D4_C7,Getriebe_DL382_MLB,Getriebe_DL501_MLB,Getriebe_VL381_MLB
 SG_ TSK_Getriebeinfo : 51|2@1+ (1,0) [0|3] ""  Gateway
 SG_ TSK_Codierung_ACC : 53|1@1+ (1,0) [0|1] ""  EPB_MLB,Gateway,Getriebe_AL551_951_D4_C7,Getriebe_AL551_Hybrid_D4_C7,Getriebe_DL382_MLB,Getriebe_DL501_MLB,Getriebe_VL381_MLB
 SG_ TSK_Zwangszusch_ESP : 54|1@1+ (1,0) [0|1] ""  Gateway
 SG_ TSK_Freig_Verzoeg_Anf : 55|1@1+ (1,0) [0|1] ""  Gateway,Getriebe_AL551_951_D4_C7,Getriebe_AL551_Hybrid_D4_C7,Getriebe_DL382_MLB,Getriebe_DL501_MLB,Getriebe_VL381_MLB
 SG_ TSK_Verzoeg_Anf_02 : 56|8@1+ (0.024,-3.984) [-3.984|2.136] "Unit_MeterPerSeconSquar"  Gateway

BO_ 1716 VIN_01: 8 Gateway
 SG_ VIN_01_MUX M : 0|2@1+ (1,0) [0|3] ""  Airbag_D4,EPB_MLB,LWS_D4,SAK,SAK2,SCR_MLB,SCU
 SG_ KS_Geheimnis_1 m0 : 8|8@1+ (1,0) [0|255] ""  Airbag_D4
 SG_ VIN_4 m1 : 8|8@1+ (1,0) [0|255] ""  Airbag_D4,EPB_MLB
 SG_ VIN_11 m2 : 8|8@1+ (1,0) [0|255] ""  Airbag_D4,EPB_MLB
 SG_ KS_Geheimnis_2 m0 : 16|8@1+ (1,0) [0|255] ""  Airbag_D4
 SG_ VIN_5 m1 : 16|8@1+ (1,0) [0|255] ""  Airbag_D4,EPB_MLB
 SG_ VIN_12 m2 : 16|8@1+ (1,0) [0|255] ""  Airbag_D4,EPB_MLB
 SG_ KS_Geheimnis_3 m0 : 24|8@1+ (1,0) [0|255] ""  Airbag_D4
 SG_ VIN_6 m1 : 24|8@1+ (1,0) [0|255] ""  Airbag_D4,EPB_MLB
 SG_ VIN_13 m2 : 24|8@1+ (1,0) [0|255] ""  Airbag_D4,EPB_MLB
 SG_ KS_Geheimnis_4 m0 : 32|8@1+ (1,0) [0|255] ""  Airbag_D4
 SG_ VIN_7 m1 : 32|8@1+ (1,0) [0|255] ""  Airbag_D4,EPB_MLB,SAK,SAK2,SCR_MLB
 SG_ VIN_14 m2 : 32|8@1+ (1,0) [0|255] ""  Airbag_D4,EPB_MLB,LWS_D4,SCU
 SG_ VIN_1 m0 : 40|8@1+ (1,0) [0|255] ""  Airbag_D4,EPB_MLB
 SG_ VIN_8 m1 : 40|8@1+ (1,0) [0|255] ""  Airbag_D4,EPB_MLB,SAK,SAK2,SCR_MLB
 SG_ VIN_15 m2 : 40|8@1+ (1,0) [0|255] ""  Airbag_D4,EPB_MLB,LWS_D4,SCU
 SG_ VIN_2 m0 : 48|8@1+ (1,0) [0|255] ""  Airbag_D4,EPB_MLB
 SG_ VIN_9 m1 : 48|8@1+ (1,0) [0|255] ""  Airbag_D4,EPB_MLB
 SG_ VIN_16 m2 : 48|8@1+ (1,0) [0|255] ""  Airbag_D4,EPB_MLB,LWS_D4,SCU
 SG_ VIN_3 m0 : 56|8@1+ (1,0) [0|255] ""  Airbag_D4,EPB_MLB
 SG_ VIN_10 m1 : 56|8@1+ (1,0) [0|255] ""  Airbag_D4,EPB_MLB
 SG_ VIN_17 m2 : 56|8@1+ (1,0) [0|255] ""  Airbag_D4,EPB_MLB,LWS_D4,SCR_MLB,SCU

BO_ 1414 Waehlhebel_02: 8 Getriebe_AL551_951_D4_C7
 SG_ WH_KD_Fehler : 63|1@1+ (1,0) [0|1] ""  Gateway

BO_ 915 WBA_02: 8 Getriebe_AL551_951_D4_C7
 SG_ WBA_02_CHK : 0|8@1+ (1,0) [0|255] ""  Gateway
 SG_ WBA_02_BZ : 8|4@1+ (1,0) [0|15] ""  Gateway
 SG_ WBA_Senderkennung M : 12|1@1+ (1,0) [0|1] ""  Gateway
 SG_ WBA_Lampe_Shift_Lock m0 : 13|1@1+ (1,0) [0|1] ""  Gateway
 SG_ WBA_Schaltempf_verfbar m1 : 13|1@1+ (1,0) [0|1] ""  Gateway
 SG_ WBA_Effizienzmodus : 14|1@1+ (1,0) [0|1] ""  Gateway
 SG_ WBA_Kurzzeittipp m0 : 15|1@1+ (1,0) [0|1] ""  Gateway
 SG_ WBA_Blinken m0 : 16|1@1+ (1,0) [0|1] ""  Gateway
 SG_ WBA_Getriebevariante m0 : 17|4@1+ (1,0) [0|15] ""  Gateway
 SG_ WBA_GE_Warnung : 21|3@1+ (1,0) [0|7] ""  Gateway
 SG_ WBA_Fahrstufe m0 : 24|4@1+ (1,0) [0|15] ""  Gateway
 SG_ WBA_Istgang m1 : 24|4@1+ (1,0) [0|15] ""  Gateway
 SG_ WBA_eing_Gang m0 : 28|4@1+ (1,0) [0|15] ""  Gateway
 SG_ WBA_Sollgang m1 : 28|4@1+ (1,0) [0|15] ""  Gateway
 SG_ WBA_GE_Texte m0 : 32|3@1+ (1,0) [0|7] ""  Gateway
 SG_ WBA_Schaltschema_Aktiv m0 : 35|1@1+ (1,0) [0|1] ""  Gateway
 SG_ WH_Warnung m0 : 36|3@1+ (1,0) [0|7] ""  Gateway
 SG_ WBA_GE_Zusatzwarnungen m0 : 39|3@1+ (1,0) [0|7] ""  Gateway
 SG_ WBA_Segeln_aktiv m0 : 42|1@1+ (1,0) [0|1] ""  Gateway
 SG_ GE_Tipschaltempf_verfuegbar m0 : 43|1@1+ (1,0) [0|1] ""  Gateway
 SG_ GE_Sollgang m0 : 44|4@1+ (1,0) [0|15] ""  Gateway

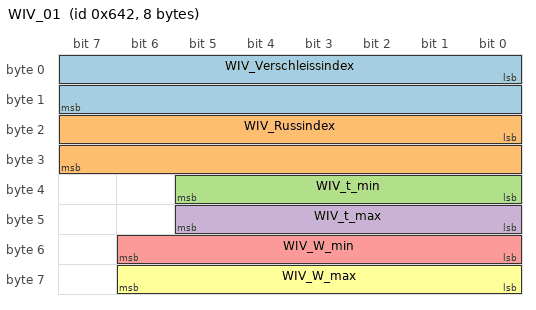
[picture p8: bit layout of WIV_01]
BO_ 1602 WIV_01: 8 Motor_MLB_AU64_AU57_Diesel
 SG_ WIV_Verschleissindex : 0|16@1+ (2E-008,0) [0|0.00131068] ""  Gateway
 SG_ WIV_Russindex : 16|16@1+ (2E-008,0) [0|0.00131068] ""  Gateway
 SG_ WIV_t_min : 32|6@1+ (1,0) [0|63] "Unit_Month"  Gateway
 SG_ WIV_t_max : 40|6@1+ (1,0) [0|63] "Unit_Month"  Gateway
 SG_ WIV_W_min : 48|7@1+ (1000,0) [0|127000] "Unit_KiloMeter"  Gateway
 SG_ WIV_W_max : 56|7@1+ (1000,0) [0|127000] "Unit_KiloMeter"  Gateway

BO_ 2616990720 XCP_ESP_CRO_01: 8 Gateway
 SG_ XCP_ESP_CRO_01_Data : 0|64@1+ (1,0) [0|1.84467440737096E+019] ""  ESP

BO_ 2616990724 XCP_ESP_DTO_01: 8 ESP
 SG_ XCP_ESP_DTO_01_Data : 0|64@1+ (1,0) [0|1.84467440737096E+019] ""  Gateway

BO_TX_BU_ 913 : Motor_MLB_AU64_AU57_Diesel,Motor_MLB_BY_Otto,Motor_MLB_C7_PHEV,Motor_MLB_D4_C7_Hybrid,Motor_MLB_D4_C7_Otto;
BO_TX_BU_ 2550006391 : Getriebe_AL551_951_D4_C7,Getriebe_AL551_Hybrid_D4_C7,Getriebe_DL382_MLB,Getriebe_DL501_MLB,Getriebe_VL381_MLB;
BO_TX_BU_ 2550006390 : Motor_MLB_AU64_AU57_Diesel,Motor_MLB_C7_PHEV,Motor_MLB_D4_C7_Hybrid,Motor_MLB_D4_C7_Otto;
BO_TX_BU_ 768 : Daempfer_MLB,SCU;
BO_TX_BU_ 769 : Daempfer_MLB,SCU;
BO_TX_BU_ 770 : Daempfer_MLB,SCU;
BO_TX_BU_ 771 : Daempfer_MLB,SCU;
BO_TX_BU_ 772 : Daempfer_MLB,SCU;
BO_TX_BU_ 773 : Daempfer_MLB,SCU;
BO_TX_BU_ 774 : Daempfer_MLB,SCU;
BO_TX_BU_ 775 : Daempfer_MLB,SCU;
BO_TX_BU_ 786 : Motor_MLB_AU64_AU57_Diesel,Motor_MLB_BY_Otto,Motor_MLB_C7_PHEV,Motor_MLB_D4_C7_Hybrid,Motor_MLB_D4_C7_Otto;
BO_TX_BU_ 270 : Motor_MLB_AU64_AU57_Diesel,Motor_MLB_BY_Otto,Motor_MLB_C7_PHEV,Motor_MLB_D4_C7_Hybrid,Motor_MLB_D4_C7_Otto;
BO_TX_BU_ 273 : Motor_MLB_AU64_AU57_Diesel,Motor_MLB_BY_Otto,Motor_MLB_C7_PHEV,Motor_MLB_D4_C7_Hybrid,Motor_MLB_D4_C7_Otto;
BO_TX_BU_ 1414 : Getriebe_AL551_951_D4_C7,Getriebe_AL551_Hybrid_D4_C7;
BO_TX_BU_ 915 : Getriebe_AL551_951_D4_C7,Getriebe_AL551_Hybrid_D4_C7,Getriebe_DL382_MLB,Getriebe_DL501_MLB,Getriebe_VL381_MLB,Motor_MLB_AU64_AU57_Diesel,Motor_MLB_BY_Otto,Motor_MLB_C7_PHEV,Motor_MLB_D4_C7_Hybrid,Motor_MLB_D4_C7_Otto;
BO_TX_BU_ 1602 : Motor_MLB_AU64_AU57_Diesel,Motor_MLB_BY_Otto,Motor_MLB_C7_PHEV,Motor_MLB_D4_C7_Hybrid,Motor_MLB_D4_C7_Otto;
CM_ SG_ 913 OBD_Calc_Load_Val "Calculated Load Value

Übertragung von Meßgrößen an das Getriebesteuergerät für Freeze Frame Abspeicherung bei Getriebefehlern

PID $04 Calculated Load Value; 0 .. 100% mit 100/255 % per bit
";
CM_ SG_ 913 OBD_Eng_Cool_Temp "Engine Coolant Temperature

Übertragung von Meßgrößen an das Getriebesteuergerät für Freeze Frame Abspeicherung bei Getriebefehlern

PID $05 Engine Coolant Temperature; -40 .. +215°C mit 1°C/bit und 40°C Offset";
CM_ SG_ 913 OBD_Abs_Throttle_Pos "Absolute Throttle Position

Übertragung von Meßgrößen an das Getriebesteuergerät für Freeze Frame Abspeicherung bei Getriebefehlern

PID $11 Absolute Throttle Position; 0 .. 100% mit 100/255 %/bit";
CM_ SG_ 913 OBD_Abs_Load_Val "Absolute Load Value

Übertragung von Meßgrößen an das Getriebesteuergerät für Freeze Frame Abspeicherung bei Getriebefehlern

PID $43 Absolute Load Value; 0 .. 25700%  mit 100/255 %/bit";
CM_ SG_ 913 OBD_Abs_Pedal_Pos "Absolute Pedal Position

Übertragung von Meßgrößen an das Getriebesteuergerät für Freeze Frame Abspeicherung bei Getriebefehlern

PID $49 Accelerator Pedal Position D; 0 .. 100% mit 100/255 %/bit";
CM_ SG_ 913 OBD_Sperrung_IUMPR "Wenn der General Denominator auf Grund eines Fehlers in den Eingangsgrößen gesperrt wird, wird diese Information über Bussystem als OBD-Statusinformation OBD_Sperrung_IUMPR für andere OBD-Steuergeräte bereitgestellt. 

Das MSG (MIL-Master) setzt dieses ";
CM_ SG_ 913 OBD_Kaltstart_Denominator "Bestimmte Diagnosen werden nur unter Kaltstartbedingungen durchgeführt, der entsprechende Denominator bei IUMPR-pflichtigen Systemen wird anhand dieses vom MSG gebildeten Signals inkrementiert. (Entspricht EVAP-Denominator)";
CM_ SG_ 913 OBD_Minimum_Trip "Grundlage OBD-Gesetz CCR 1968.2 (d)(4.3) Denominator Specifications
Bildung des General Denominator 'Normed Trip':
 600 sec. (kumulativ) Zeit nach Motorstart
 300 sec. (kumulativ) mit Fahrzeuggeschwindigkeit > 25 mph (40 km/h)
 30 sec. (kontinuierlich";
CM_ SG_ 913 OBD_Warm_Up_Cycle "Mit dem Warm-Up-Cycle wird der zentrale Verlernzähler vom Gateway inkrementiert";
CM_ SG_ 913 OBD_Normed_Trip "Gesetzlich definierte 'Normed Condition' erfüllt, 'General Denominator' darf erhöht werden";
CM_ BO_ 1630 "Tankgeberwerte für OBD-relevante Plausibilisierung im Motor-SG";
CM_ SG_ 1630 OBD_TG_F_Status_1 "Fehlerstatus Tankfüllstandsgeber (OBD relevanter Sensor für Tankleckdiagnose)";
CM_ SG_ 1630 OBD_TG_F_Status_2 "Fehlerstatus Tankfüllstandsgeber (OBD relevanter Sensor für Tankleckdiagnose)

0x00 = kein Fehler / Init / nicht verbaut
0x01 = KS-
0x02 = KS+ (B8: nicht bedient)
0x03 = OC (Leitungsunterbrechung) (B8: nicht bedient)
0x04 = OOR+ (out of range high) ";
CM_ SG_ 1630 OBD_TG_F_Status_3 "Fehlerstatus Tankfüllstandsgeber (OBD relevanter Sensor für Tankleckdiagnose)

0x00 = kein Fehler / Init / nicht verbaut
0x01 = KS-
0x02 = KS+ (B8: nicht bedient)
0x03 = OC (Leitungsunterbrechung) (B8: nicht bedient)
0x04 = OOR+ (out of range high) ";
CM_ SG_ 1630 OBD_TG_F_Status_4 "Fehlerstatus Tankfüllstandsgeber (OBD relevanter Sensor für Tankleckdiagnose)

0x00 = kein Fehler / Init / nicht verbaut
0x01 = KS-
0x02 = KS+ (B8: nicht bedient)
0x03 = OC (Leitungsunterbrechung) (B8: nicht bedient)
0x04 = OOR+ (out of range high) ";
CM_ SG_ 1630 OBD_TG_Sens_Rohwert_1 "Rohwert des Tankgebers, nur gefiltert (gleitender Mittelwert), Ausgabe im 500ms-Raster";
CM_ SG_ 1630 OBD_TG_Sens_Rohwert_2 "Rohwert des Tankgebers, nur gefiltert (gleitender Mittelwert), Ausgabe im 500ms-Raster";
CM_ SG_ 1630 OBD_TG_Sens_Rohwert_3 "Rohwert des Tankgebers, nur gefiltert (gleitender Mittelwert), Ausgabe im 500ms-Raster";
CM_ SG_ 1630 OBD_TG_Sens_Rohwert_4 "Rohwert des Tankgebers, nur gefiltert (gleitender Mittelwert), Ausgabe im 500ms-Raster";
CM_ BO_ 803 "PreCrashFront";
CM_ SG_ 803 PCF_01_CRC "Für MLB:
'Berechnung siehe Lastenheft 'Kommunikationsabsicherung für Flexray und CAN''

Ab MQB und MLBevo:
'Berechnung siehe Lastenheft 'End-to-End Kommunikationsabsicherung'

Endwerte siehe Begleitdokument 'S-PDU Kennungsfolge'";
CM_ SG_ 803 PCF_01_BZ "Botschaftszähler pro PDU

";
CM_ SG_ 803 PCF_Objektstatus "Statuszustände des Objektes";
CM_ SG_ 803 PCF_Fahrer_aktiv_erkannt "Ergebnis der Fahrerbeobachtung im AWV Algorithmus";
CM_ SG_ 803 PCF_Time_to_collision "Prädizierter Aufprallzeipunkt des relevanten Objektes";
CM_ SG_ 803 PCF_v_rel "Prädizierte Aufprallgeschwindigkeit";
CM_ SG_ 803 PCF_dy_Kollisionsueberdeckung "Prognostizierte Kollisionsüberdeckung in y";
CM_ SG_ 802 PCR_Sensorstatus "Status des Heckumfeldsensors";
CM_ SG_ 802 PCR_Obj_vx_rel "Relative Geschwindigkeit in x-Richtung des wahrscheinlichsten Objektes ";
CM_ SG_ 802 PCR_Obj_vy_rel "Relative Geschwindigkeit in y-Richtung des wahrscheinlichsten Objektes ";
CM_ SG_ 802 PCR_Obj_TTC "TimeToCollision des wahrscheinlichsten Objektes";
CM_ SG_ 802 PCR_Obj_Guete "Detektionsgüte des wahrscheinlichsten Objektes";
CM_ SG_ 802 PCR_Sensorstatus_02 "Status des Heckumfeldsensors";
CM_ BO_ 929 "Auf diese Botschaft darf bis auf Weiteres keine Botschaftsüberwachung durchgeführt werden (unsicherer Quellbus).";
CM_ SG_ 929 PSD_Pos_Segment_ID "Identifier des Streckensegments, auf dem sich das Fahrzeug aktuell befindet
";
CM_ SG_ 929 PSD_Pos_Segmentlaenge "Verbleibende Länge des Streckensegments, auf dem sich das Fahrzeug aktuell befindet
";
CM_ SG_ 929 PSD_Pos_Inhibitzeit "Zeitspanne zwischen Generierung der PSD Daten im Navigationssystem und Versand der Daten auf den Most
";
CM_ SG_ 929 PSD_Segment_ID "Identifier des prädiktiven Streckensegments
";
CM_ SG_ 929 PSD_Vorgaenger_Segment_ID "An dem Streckensegment mit diesem Identifier schließt sich das neue Segment mit der ID 'PSD_01_Segment_ID' an.
";
CM_ SG_ 929 PSD_Strassenklasse "Die Klassifizierung der Straße";
CM_ SG_ 929 PSD_Segmentlaenge "Gesamtlänge des prädiktiven Streckensegments";
CM_ SG_ 929 PSD_Endkruemmung "'Endkrümmung der Klotoide des übermittelten Streckensegments. Die Anfangskrümmung des folgenden Streckensegments entspricht der Endkrümmung dieses Segments. Krümmung = 1/(1+0.155 * x²) [1/m]

";
CM_ SG_ 929 PSD_Endsteigung "Endsteigung des Streckensegments. ";
CM_ SG_ 929 PSD_ADAS_Qualitaet "ADAS Qualtität des Streckensegments.";
CM_ SG_ 929 PSD_Fahrspuren "Fahrspuren in Fahrtrichtung
";
CM_ SG_ 929 PSD_wahrscheinlichster_Pfad "Identifiziert den vom Navigationssystem berechneten wahrscheinlichsten Pfad des Fahrzeuges. ";
CM_ BO_ 930 "Auf diese Botschaft darf bis auf Weiteres keine Botschaftsüberwachung durchgeführt werden (unsicherer Quellbus).";
CM_ SG_ 930 PSD_Multiplex "Identifieziert den Multiplex der Botschaft.";
CM_ SG_ 930 PSD_Sys_Segment_ID "Identifier des prädiktiven Streckensegments ab dem die Systeminformationen gültig sind.
";
CM_ SG_ 930 PSD_Abz_Segment_ID "Identifier des prädiktiven abzweigenden Streckensegments.
";
CM_ SG_ 930 PSD_Ges_Segment_ID "Identifier des prädiktiven Streckensegments ab dem die Geschwindigkeitsbegrenzungen und mögliche Einschränkungen gelten.
";
CM_ SG_ 930 PSD_Ort_Laenge_VZ "Vorzeichen Laengengrad";
CM_ SG_ 930 PSD_Ort_Laenge "Laengengrad in WGS84 aus Koppelnavigation";
CM_ SG_ 930 PSD_Sys_Laendercode "Ländercode
";
CM_ SG_ 930 PSD_Abz_Segmentlaenge "Länge des aktuell übermittelten Streckensegments der Abzweigung.

";
CM_ SG_ 930 PSD_Ges_Geschwindigkeit_Typ "Typ der Geschwindigkeitsbegrenzung";
CM_ SG_ 930 PSD_Ges_Geschwindigkeit_Gespann "Gilt diese Einschränkung der Geschwindigkeit für alle Fahrzeuge oder ausschließlich für PKW mit Gespann oder für LKW, Buss, etc.";
CM_ SG_ 930 PSD_Abz_Vorgaenger_Segment_ID "Identifier des prädiktiven Streckensegments an dessen Ende die Abzweigung angeheftet ist.
";
CM_ SG_ 930 PSD_Sys_Geschwindigkeit_Einheit "Unterscheidung zwischen km/h und miles/h";
CM_ SG_ 930 PSD_Ges_Geschwindigkeit_Witter "Witterungsabhängigkeit der Geschwindigkeitsbegrenzung";
CM_ SG_ 930 PSD_Sys_Verkehrsrichtung "Unterscheidung zwischen Linksverkehr und Rechtsverkehr";
CM_ SG_ 930 PSD_Sys_Release_Monat "Release Datum der Daten DVD: Monat 01¿12";
CM_ SG_ 930 PSD_Ges_Geschwindigkeit_Tag_Anf "Wochentag, an dem die tägliche Geschwindigkeitsbegrenzung beginnt";
CM_ SG_ 930 PSD_Ges_Geschwindigkeit_Tag_Ende "Wochentag, an dem die tägliche Geschwindigkeitsbegrenzung endet";
CM_ SG_ 930 PSD_Sys_Release_Jahr "Release Datum der Daten DVD Jahr 2000 - 2031
";
CM_ SG_ 930 PSD_Ges_Geschwindigkeit_Std_Anf "Stunde, zu der die stündliche Geschwindigkeitsbegrenzung beginnt
0h.. 24h";
CM_ SG_ 930 PSD_Abz_Geschwindigkeit_Typ "Typ der Geschwindigkeitsbegrenzung";
CM_ SG_ 930 PSD_Sys_Tunnel "Tunnel";
CM_ SG_ 930 PSD_Abz_Strassenklasse "Die Klassifizierung des abzweigenden Streckensegments.";
CM_ SG_ 930 PSD_Sys_Bruecke "Bruecke";
CM_ SG_ 930 PSD_Sys_Fahrsp_Gegenr "Fahrspuren in Gegenrichtung";
CM_ SG_ 930 PSD_Abz_ADAS_Qualitaet "ADAS Qualtität des abzweigenden Streckensegments.";
CM_ SG_ 930 PSD_Ges_Geschwindigkeit_Std_Ende "Stunde, an der die stündliche Geschwindigkeitsbegrenzung endet
0h.. 24h";
CM_ SG_ 930 PSD_Ort_Breite "Breitengrad in WGS84 aus Koppelnavigation";
CM_ SG_ 930 PSD_Abz_Abzweigerichtung "Richtung, in die die Abzweigung von der Hauptroute abzweigt.";
CM_ SG_ 930 PSD_Sys_TMC_Baustelle "TMC Signal fuer Baustellenbereich";
CM_ SG_ 930 PSD_Abz_Abzweigewinkel "Winkel, unter dem die Abzweigung von der Hauptroute abzweigt.";
CM_ SG_ 930 PSD_Sys_TMC_Stau "TMC Signal fuer Stauinformation";
CM_ SG_ 930 PSD_Sys_Bauliche_Trennung "Trennung der Spuren in Fahrtrichtung zu den Spuren in Gegenrichtung.";
CM_ SG_ 930 PSD_Sys_Geometrieguete "Maß für die Güte der Klothoidengeometrie.";
CM_ SG_ 930 PSD_Sys_Maut "Erkennen von Mautstellen.";
CM_ SG_ 930 PSD_Abz_Anfangskruemmung "Anfangskrümmung des abzweigenden Streckensegments.
Krümmung = 1/(1+0,155*x²)  [1/m]";
CM_ SG_ 930 PSD_Sys_Strassensituation "Besondere Straßensituationen, wie z.B. Kreisverkehr, Parkbuchten, etc.";
CM_ SG_ 930 PSD_Ges_alter_Geschw_Gespann "Gilt diese alternative Einschränkung der Geschwindigkeit für alle Fahrzeuge oder ausschließlich für PKW mit Gespann oder LKW, Busse, etc. 
0x0 = alle Fahrzeuge
0x1 = PKW mit Gespann
0x2 = LKW, Busse, etc.";
CM_ SG_ 930 PSD_Sys_StrKlassen_erweitert "Differenzierte Strassenklassen Aufteilung";
CM_ SG_ 930 PSD_Ges_alter_Geschw_Witter "Witterungsabhängigkeit der alternativen Geschwindigkeitsbegrenzung.";
CM_ SG_ 930 PSD_Sys_Ortsschild "Ortsschild als Begrenzung von Ortschaften.";
CM_ SG_ 930 PSD_Ges_alter_Geschw_Tag_Anf "Wochentag, an dem die tägliche alternative Geschwindigkeitsbegrenzung beginnt";
CM_ SG_ 930 PSD_Sys_Anfangskruemmung "Anfangskrümmung des entsprechenden Streckensegments.
Krümmung = 1/(1+0,155*x²)  [1/m]

";
CM_ SG_ 930 PSD_Abz_Endkruemmung "Endkrümmung des abzweigenden Streckensegments.
Krümmung = 1/(1+0,155*x²)  [1/m]";
CM_ SG_ 930 PSD_Ges_alter_Geschw_Tag_Ende "Wochentag, an dem die tägliche alternative Geschwindigkeitsbegrenzung endet.";
CM_ SG_ 930 PSD_Ges_alter_Geschw_Std_Anf "Stunde, zu der die stündliche alternative Geschwindigkeitsbegrenzung beginnt
0h.. 24h.";
CM_ SG_ 930 PSD_Ort_Hoehe "Hoehe ueber NN an der";
CM_ SG_ 930 PSD_Ges_alter_Geschw_Std_Ende "Stunde an der die stündliche alternative Geschwindigkeitsbegrenzung endet
0h.. 24h";
CM_ SG_ 930 PSD_Sys_Anfangssteigung "Anfangssteigung des Streckensegments. ";
CM_ SG_ 930 PSD_Abz_Endsteigung "Endsteigung des Streckensegments. ";
CM_ SG_ 930 PSD_Sys_Ortschaft "Die Grenze wird nicht durch das Ortsschild, sondern durch den Beginn der Bebauung markiert.";
CM_ SG_ 930 PSD_Abz_Fahrspuren "Fahrspuren der abzweigenden Strecke in Fahrtrichtung.";
CM_ SG_ 930 PSD_Ges_Wechselverkehrszeichen "Am Beginn des Segments ist ein Wechselverkehrszeichen angebracht.";
CM_ SG_ 930 PSD_Sys_Digitalisierung "Qualität des Kartenmaterials.
In digitalisierten Karten sind sämtliche Straßen erfasst. 
In teildigitalisierten Karten können einzelne Straßen nicht erfasst sein. Dies kann zu Fehlinterpretationen beim MapMatching innerhalb des Navigationssystems führen";
CM_ SG_ 930 PSD_Sys_Zielfuehrung "Zielfuehrung im Navigationssystem. Damit lässt sich der wahrscheinlichste Pfad des Fahrzeuges zuverlässig angeben.";
CM_ SG_ 930 PSD_Abz_wahrscheinlichster_Pfad "Identifiziert den vom Navigationssystem berechneten wahrscheinlichsten Pfad des Fahrzeuges für die abzweigende Strecke.";
CM_ BO_ 1528 "MLB";
CM_ SG_ 1528 SAK_Charisma_FahrPr "Rückmeldung des aktuellen Charisma-Status des Soundaktors";
CM_ SG_ 1528 SAK_Charisma_Status "Rückmeldung an den Charisma-Master

Wert 0x3 ist nur für Fahrzeuge ab MQB relevant";
CM_ SG_ 1528 SAK_Charisma_Umschaltung "Erkennung  Umschaltaufforderung des Charisma-Teilnehmers";
CM_ SG_ 1528 SAK_KD_Fehler "Bei gesetztem Bit ist mindestens ein Kundendienstfehler eingetragen";
CM_ SG_ 1011 SCR_01_BZ "Zähler der von der Applikation inkrementiert wird";
CM_ SG_ 1011 SCR_QBit_Level_Aktivtank_02 "gibt an ob das Signal gültig ist.";
CM_ SG_ 1011 SCR_Level_ReadAbove "Zeigt an in welchem Messmodus der Levelsensor ist.
Dieses Signal ist für die Füllstandberechnung notwendig und für die OBD-Diagnose mit notwendig.
Ist der Sensor im Readabove Ein Modus, ist die Toleranz des gemessenen Signals größer.";
CM_ SG_ 1011 SCR_Dosierpumpe_Drehzahl "Drehzahl der Dosierpumpe

negative 1/min für Rückwärtsbetrieb
0 für Stop
positive 1/min für Vorwärtsbetrieb";
CM_ SG_ 1011 SCR_Druck "Druck der wässrigen Harnstofflösung";
CM_ SG_ 1011 SCR_Level_Aktivtank "Füllstand des Aktivtanks";
CM_ SG_ 1011 SCR_Level_Passivtank "Füllstand des Passivtanks";
CM_ SG_ 1507 SCR_Heizkreis_3_Strom "gemessener Strom vom Heizkreis 3 (ist optional verbaut)";
CM_ SG_ 1507 SCR_02_BZ "Zähler der von der Applikation inkrementiert wird";
CM_ SG_ 1507 SCR_Guetesensor "Güte der Flüssigkeit";
CM_ SG_ 1507 SCR_Temp_Aktivtank "Temperatur des Medium im Aktivtank";
CM_ SG_ 1507 SCR_Temp_Passivtank "Temperatur des Medium im Aktivtank";
CM_ SG_ 1507 SCR_Leitungsheizung_Strom "gemessener Strom für die Leitungsheizung";
CM_ SG_ 1507 SCR_Transferpumpe_Strom "gemessener Strom für dieTransferpumpe";
CM_ SG_ 1507 SCR_Tankheizung_Strom "gemessener Strom für die Tankheizung Aktivtank";
CM_ SG_ 1508 SCR_03_BZ "Zähler der von der Applikation inkrementiert wird";
CM_ SG_ 1508 SCR_Spannungsversorgung_Status "Statusinformation für OBD-Auswertung";
CM_ SG_ 1508 SCR_VersorgungSensoren_Status "Statusinformation für OBD-Auswertung";
CM_ SG_ 1508 SCR_Heizkreis_3_Status "Statusinformation für OBD-Auswertung";
CM_ SG_ 1508 SCR_Guetesensor_Status "Statusinformation für OBD-Auswertung
KS+ / OC entspricht KS+ nach 5V";
CM_ SG_ 1508 SCR_Leitungsheizung_Status "Statusinformation für OBD-Auswertung";
CM_ SG_ 1508 SCR_Tankheizung_Status "Statusinformation für OBD-Auswertung";
CM_ SG_ 1508 SCR_Druck_Status "Statusinformation für OBD-Auswertung
KS+ / OC entspricht KS+ nach 5V";
CM_ SG_ 1508 SCR_Dosierpumpe_Status_Spule "Statusinformation für OBD-Auswertung";
CM_ SG_ 1508 SCR_Transferpumpe_Status "Statusinformation für OBD-Auswertung";
CM_ SG_ 1508 SCR_Level_Aktivtank_Status "Statusinformation für OBD-Auswertung
KS+ / OC entspricht KS+ nach 5V
RC+ (alle Schalter offen) UND RC- (Wert unplausibel)";
CM_ SG_ 1508 SCR_Level_Passivtank_Status "Statusinformation für OBD-Auswertung
KS+ / OC entspricht KS+ nach 5V
RC+ (alle Schalter offen) UND RC- (Wert unplausibel)";
CM_ SG_ 1508 SCR_Temp_Aktivtank_Status "Statusinformation für OBD-Auswertung
KS+ / OC entspricht KS+ nach 5V";
CM_ SG_ 1508 SCR_Temp_Passivtank_Status "Statusinformation für OBD-Auswertung
KS+ / OC entspricht KS+ nach 5V";
CM_ SG_ 1509 SCR_04_BZ "Zähler der von der Applikation inkrementiert wird";
CM_ SG_ 1509 SCR_Ansteuerung_Transferpumpe "Messwert im Motor-SG zur Treiber-Ansteuerung der Transferpumpe Endstufe. ";
CM_ SG_ 1509 SCR_Ansteuerung_Dosierpumpe "Messwert im Motor-SG zur Treiber-Ansteuerung der Dosierpumpen Endstufe.";
CM_ SG_ 1509 SCR_Ansteuerung_Heizkreis_3 "Messwert im Motor-SG zur Treiber-Ansteuerung der Heizkreis 3 Endstufe. ";
CM_ SG_ 1509 SCR_Ansteuerung_Leitungsheizung "Messwert im Motor-SG zur Treiber-Ansteuerung der Leitungsheizungs Endstufe. ";
CM_ SG_ 1509 SCR_Ansteuerung_Tankheizung "Messwert im Motor-SG zur Treiber-Ansteuerung der Tankheizungs Endstufe. ";
CM_ SG_ 1509 SCR_CAL_CVN_CRC_32 "Gesetzliche Anforderung nach OBD-Gesetz CCR1968.2 (g) (4.7) für 'diagnostic or emission critical powertrain control module'";
CM_ SG_ 1526 SCR_05_BZ "Zähler der von der Applikation inkrementiert wird";
CM_ SG_ 1526 SCR_Level_Aktivtank_OOR4Quality "Der Füllstand im SCR-Tank ist zu niedrig um eine Qualtiätsmessung durchzuführen.";
CM_ SG_ 1526 SCR_Level_Aktivtank_OOR_minus "Minimaler Level vom SCR-Tank erreicht.
Tankstand so niedrig, dass das Signal nicht mehr verlässlich erfasst werden kann.";
CM_ SG_ 1526 SCR_Sent_1_Signalstatus "Signalfehler vom Sent_1 Signal";
CM_ SG_ 1526 SCR_Sent_1_elektrischer_Status "Fehlerstatus der elektrischen Diagnosen";
CM_ SG_ 1526 SCR_Sent_Levelsensor "Funktionaler Fehlerstatus des Levelsensors";
CM_ SG_ 1526 SCR_Sent_Qualitaetssensor "Funktionalen Fehler des Qualitätssensors";
CM_ SG_ 1526 SCR_Sent_Temperatursensor "Funktionaler Fehlerstatus vom internen Temperatursensor in dem Sentsensor";
CM_ SG_ 1526 SCR_DEF_Qualitaet_Medium "Gibt an, dass die Konzentration des Medium nicht ermittelt werden kann.";
CM_ SG_ 1526 SCR_QBit_Qualitaet "gibt an ob das Signal gültig ist";
CM_ SG_ 1526 SCR_Qualitaet "Qualität des Medium im SCR-TAnk";
CM_ SG_ 1526 SCR_Steuergeraet_Heizung_Status "StatusInformation für OBD-Auswertung";
CM_ SG_ 1526 SCR_Steuergeraet_Pumpe_Status "StatusInformation der Dosierpumpe für OBD-Auswertung";
CM_ SG_ 1526 SCR_Steuergeraet_Relais_Status "StatusInformation für OBD-Auswertung";
CM_ SG_ 1526 SCR_Steuergeraet_Bus_Status "StatusInformation für OBD-Auswertung";
CM_ SG_ 1526 SCR_Steuergeraet_Datensatz_St002 "StatusInformation für OBD-Auswertung";
CM_ SG_ 1526 SCR_Steuergeraet_Defekt_Status "StatusInformation für OBD-Auswertung";
CM_ BO_ 1510 "Teilenummer & Checksumme für OBD-Lampe";
CM_ SG_ 1510 SCR_CAL_ID_Index_01 "ASCII-Zeichen erster Buchstabe des SG-Namens";
CM_ SG_ 1510 SCR_CAL_ID_Index_02 "ASCII-Zeichen zweiter Buchstabe des SG-Namens";
CM_ SG_ 1510 SCR_CAL_ID_Index_03 "ASCII-Zeichen dritter Buchstabe des SG-Namens";
CM_ SG_ 1510 SCR_CAL_ID_Index_04 "ASCII-Zeichen erster Buchstabe der letzten 3 Stellen der Software-Teilenummer";
CM_ SG_ 1510 SCR_CAL_ID_Index_05 "ASCII-Zeichen zweiter Buchstabe der letzten 3 Stellen der Software-Teilenummer";
CM_ SG_ 1510 SCR_CAL_ID_Index_06 "ASCII-Zeichen dritter Buchstabe der letzten 3 Stellen der Software-Teilenummer";
CM_ SG_ 1510 SCR_CAL_ID_Index_07 "ASCII-Zeichen Buchstabe für Hardware-Index";
CM_ SG_ 1510 SCR_CAL_ID_Index_08 "ASCII-Zeichen erster Buchstabe der vierstelligen Softwareversion";
CM_ SG_ 1512 SCR_CAL_ID_Index_09 "ASCII-Zeichen zweiter Buchstabe der vierstelligen Softwareversion";
CM_ SG_ 1512 SCR_CAL_ID_Index_10 "ASCII-Zeichen dritter Buchstabe der vierstelligen Softwareversion";
CM_ SG_ 1512 SCR_CAL_ID_Index_11 "ASCII-Zeichen vierter Buchstabe der vierstelligen Softwareversion";
CM_ SG_ 1512 SCR_CAL_ID_Index_12 "ASCII-Zeichen erster Buchstabe der zweistelligen Abgelegten Fahrzeugklasse aus dem Datensatz";
CM_ SG_ 1512 SCR_CAL_ID_Index_13 "ASCII-Zeichen zweiter Buchstabe der zweistelligen Abgelegten Fahrzeugklasse aus dem Datensatz";
CM_ SG_ 1512 SCR_CAL_ID_Index_14 "ASCII-Zeichen Reserve zur Erweiterung der OBD-relevanten Variante";
CM_ SG_ 1512 SCR_CAL_ID_Index_15 "ASCII-Zeichen erster Buchstabe der zweistelligen Datensatzversion";
CM_ SG_ 1512 SCR_CAL_ID_Index_16 "ASCII-Zeichen zweiter Buchstabe der zweistelligen Datensatzversion";
CM_ SG_ 133 SCU_01_CHK "Berechnung siehe Lastenheft 'Kommunikationsabsicherung für FlexRay und CAN'
Endwerte siehe 'Kommunikationsabsicherung für FlexRay und CAN / Anhang C: Tabelle S-PDU Kennungen'";
CM_ SG_ 133 SCU_Ue_Winkel_ADS "Gesamt-Überlagerungs-/ Motorwinkel bezogen auf Ritzelebene";
CM_ SG_ 133 SCU_VZ_Ue_Winkel_ADS "Vorzeichen des Gesamt-Überlagerungswinkels ";
CM_ SG_ 133 SCU_Soll_Ue_Winkel "Teil-Sollwinkel der SCU-Funktionen (variable Lenkübersetzung) bezogen auf das Ritzel";
CM_ SG_ 133 SCU_max_Gradient "Von der Fahrgeschwindigkeit abhängige maximaler Zustellgradient der ESP-Stabilisierungsfunktionen bezogen auf Ritzelebene.
";
CM_ SG_ 133 SCU_VZ_Soll_Ue_Winkel "Vorzeichen des SCU-Teil-Sollwinkels";
CM_ SG_ 133 SCU_Status "Status der SCU

0x5 - 0xF = tbd.
";
CM_ SG_ 133 SCU_Sensorstatus "Signal liefert Sensorstatus bei Winkeloffsetänderung";
CM_ SG_ 133 SCU_01_CRC "Für MLB:
'Berechnung siehe Lastenheft 'Kommunikationsabsicherung für FlexRay und CAN''

Ab MQB und MLBevo:
'Berechnung siehe Lastenheft 'End-to-End Kommunikationsabsicherung''

Endwerte siehe Begleitdokument 'S-PDU Kennungsfolgen'";
CM_ SG_ 784 SCU_Warnlampe "Warnungen der SCU";
CM_ SG_ 784 SCU_Warnungen "Warnungen der SCU";
CM_ SG_ 784 SCU_Charisma_FahrPr "Aktuelles Fahrprogramm des Charismateilnehmers SCU

Achtung neue Modusnamen (wie im MMI):

0x1 = Komfort = Comfort
0x2 = Dynamik = Auto
0x3 = Sport = Dynamic";
CM_ SG_ 784 SCU_Charisma_Status "Systemstatus des Charismateilnehmers SCU

Wert 0x3 ist nur für Fahrzeuge ab MQB relevant
";
CM_ SG_ 784 SCU_Charisma_Umschaltung "Erkennung Umschaltaufforderung des Charismateilnehmers SCU";
CM_ SG_ 2549875324 SK2_Key_Req_Data "Request der Service-Key2 Funktion";
CM_ SG_ 2550006396 SK2_Key_Resp_Data "Response der Service-Key2 Funktion";
CM_ SG_ 2549875319 SK2_Key_Req_Data "Request der Service-Key2 Funktion";
CM_ SG_ 2550006391 SK2_Key_Resp_Data "Response der Service-Key2 Funktion";
CM_ SG_ 2549875323 SK2_Key_Req_Data "Request der Service-Key2 Funktion";
CM_ SG_ 2550006395 SK2_Key_Resp_Data "Response der Service-Key2 Funktion";
CM_ SG_ 2549875318 SK2_Key_Req_Data "Request der Service-Key2 Funktion";
CM_ SG_ 2550006390 SK2_Key_Resp_Data "Response der Service-Key2 Funktion";
CM_ SG_ 2549875320 SK2_Key_Req_Data "Request der Service-Key2 Funktion";
CM_ SG_ 2550006392 SK2_Key_Resp_Data "Response der Service-Key2 Funktion";
CM_ SG_ 1313 STH_LED "Funktionslampe";
CM_ SG_ 1313 STH_EKP_Anst "STH sendet die Anforderung zur Ansteuerung der EKP an den Motor, um Kraftstoffbehälter der STH zu befüllen.";
CM_ SG_ 1313 STH_Start_folgt "Thema Start/Stop: Im Stop-Modus muß das KBT einen Wiederstart anfordern, da ein STH-Start notwendig ist.";
CM_ SG_ 1313 STH_Ventiloeffnungszeit "Die Standheizung sendet an den Motor die Information darüber wie lange das Magnetventil die Wasserkreisläufe von 'klein' aus 'gross' geschaltet hat. ";
CM_ SG_ 1313 STH_Ventil_Status "Statusrückmeldung Ansteuerung 3/2 Wege-Ventil";
CM_ SG_ 1313 STH_Fehler_ElWaPu "Fehler der el. Zusatzwasserpumpe der zur Deaktivierung der Wasserpumpe führt ";
CM_ SG_ 1313 STH_Waermeeintrag "Signal enthält die Brenndauer in 1min-Schritten, über welche die Standheizung gelaufen ist";
CM_ SG_ 1313 STH_Pumpen_Anf_extern "Anforderung der motorseitigen elektr. (externen) Wasserpumpe zur Kreislaufunterstützung im Standheizbetrieb";
CM_ SG_ 1313 STH_KVS "Kraftstoffverbrauch";
CM_ SG_ 1313 STH_Fehlerstatus "Übermittlung der unterschiedlichen Fehlerzustände der Standheizung";
CM_ SG_ 1313 STH_Heizleistung "Heizleistung in %";
CM_ SG_ 1313 STH_Texte "Anforderung der untersch. Anzeigetexte im Mitteldisplay d. Kombi.

0: Keine Anzeige
1: Kein Standheizungs/-llüftungsbetrieb wegen Batteriemanagementeinschränkung
2: Kein Standheizungs-/lüftungsbetrieb wegen Kraftstoffmangels
3: Kein Standheizungs-/lü";
CM_ SG_ 1313 STH_Motorvorwaermung "Info an der Motor, dass der Aufheizvorgang mit Motorvorwärmung erfolgt ist";
CM_ SG_ 1313 STH_war_aktiv "Bit beeinhaltet die Info, dass die Standheizung während der letzten halbe Stunde aktiv war.";
CM_ SG_ 1172 STS_01_CHK "Berechnung siehe Lastenheft 'Kommunikationsabsicherung für FlexRay und CAN'
Endwerte siehe 'Kommunikationsabsicherung für FlexRay und CAN / Anhang C: Tabelle S-PDU Kennungen'";
CM_ SG_ 1172 STS_01_BZ "4bit Botschaftszähler, wird in jeder Sendebotschaft inkrementiert
";
CM_ SG_ 1172 STS_Anlassersperre "Wiederstartverhinderung (Anlassersperre)";
CM_ SG_ 1172 STS_Typencodierung "Typcodierung Schnittstelle für Tracking Systeme
";
CM_ SG_ 1172 STS_KD_Fehler "Status Kundendienstfehlerspeichereinträge
";
CM_ SG_ 1172 STS_LIN_aktiv "Tracking System über LIN";
CM_ SG_ 1172 STS_Standlicht "statisch oder auch mit Blink_modi für Taxialarm";
CM_ SG_ 1172 STS_Fahrlicht "statisch oder auch mit Blink_modi für interm. Fahrlicht";
CM_ SG_ 1172 STS_Alarm_still "VTS hat einen Alarm erkannt. Alarm ist aber noch nicht bestätigt.";
CM_ SG_ 1172 STS_Texte "Nummer des Textes die im Kombi angezeigt werden soll";
CM_ SG_ 1172 STS_Laderelais "Signal für die Auswertung zur Anzeige der Batterie-Schwach-Anzeige im Kombi ";
CM_ SG_ 1172 STS_Summer "Warnsummer für Funkhauptschalter und Fahrschulpedal";
CM_ SG_ 1172 STS_Alarm_Blinker "Taxialarmblinken, wie DWA ohne Fanfare";
CM_ SG_ 1172 STS_Notstart "Signal zeigt an, dass ein Notstart erfolgte.";
CM_ SG_ 1172 STS_Signalhorn "Versehrte, Fahrschule oder Taxi (bei Alarm)";
CM_ SG_ 1172 STS_Leerlaufschaltung "Versetzt das Fahrzeug in einen Zustand in dem es nicht mehr auf EGas-Anforderungen reagiert";
CM_ BO_ 1413 "MLB";
CM_ SG_ 1413 SI_Int_CAN_gespiegelt "Nutzdaten eines internen CAN-Netzwerks (z. B. Antrieb) werden  auf den Diagnose-CAN gespiegelt (Mirror-Mode aktiviert)";
CM_ SG_ 1413 SI_CAN_Komfort_Sleep "CAN-Komfort-Netzwerk (KCAN) schläft (Status des NM)
";
CM_ SG_ 1413 SI_CAN_Dashboard_Sleep "CAN-Dashboard-Netzwerk (DCAN) schläft (Status des NM)
";
CM_ SG_ 1413 SI_CAN_Antrieb_Sleep "CAN-Antrieb-Netzwerk (ACAN) schläft (Status des NM)
";
CM_ SG_ 1413 SI_Infotainment_Sleep "Infotainment-Netzwerk (CAN/MOST) schläft (Status des NM)
";
CM_ SG_ 1413 SI_CAN_Extended_Sleep "CAN-Extended-Netzwerk (ECAN) schläft (Status des NM)
";
CM_ SG_ 1413 SI_Fahrwerk_Sleep "Fahrwerk-Netzwerk (CAN/FR) schläft (Status des NM)
";
CM_ SG_ 1413 SI_Diagnose_Aktiv "Gibt an ob Diagnose-Botschaften empfangen werden und somit eine Diagnose aktiv ist";
CM_ SG_ 1413 SI_T_Mode "0x0: Transportmodus nicht aktiv
0x1: Transportmodus aktiv";
CM_ SG_ 1413 SI_NWDF "Netzwerk-Diagnose Freigebe zur zentralen Aktivierung der Netzwerkdiagnose";
CM_ SG_ 1413 SI_NWDF_gueltig "Gültigkeitsbit zu SI_NWDF gemäß Lastenheft: Zentrale Aktivierung Netzwerkdiagnose";
CM_ SG_ 1413 SI_Sammelfehler "Sammelfehlermeldung zur Anzeige im Kombi - siehe Spez. Sammelfehlermeldung
Hinweis: Einzelne Steuergeräte können zur Anpassung an den Produktionsprozess im Gateway auskodiert werden!";
CM_ SG_ 1413 GW_KD_Fehler "Kundendienstfehlerbit Gateway zur Anzeige eines im Gateway abgelegten Fehlerspeichereintrages.";
CM_ SG_ 1413 SI_T_Schutz "Transportschutz-Signal, das bei Transportmodus und Motorlauf aktiv bleibt
0x0: Transportschutz nicht aktiv
0x1: Transportschutz aktiv";
CM_ SG_ 1413 SI_MOST_Status "Das Signal gibt den Zustand des MOST wieder.";
CM_ SG_ 1413 SI_Sammel_SG_Fehler "Anzahl der gesetzten KD-Fehler direkt angeschlossener Steuergeräte der DK3 und DK4 gemäß 80127.
Hinweis: Ein Subbusmaster stellt nur die gesammelte Information der an ihn angeschlossenen Steuergeräte der DK3 und DK4 zur Verfügung.

Für ServiceKey Auswe";
CM_ SG_ 1413 SI_CAN_Hybrid_Sleep "Hybrid-Netzwerk (CAN) schläft (Status des NM)
";
CM_ SG_ 1413 SI_MO_WU "Bit ans BCM2 zum Wecken des MSG MED9 im AUDI B8";
CM_ SG_ 786 TSK_03_CHK "Berechnung siehe Lastenheft 'Kommunikationsabsicherung für FlexRay und CAN'
Endwerte siehe 'Kommunikationsabsicherung für FlexRay und CAN / Anhang C: Tabelle S-PDU Kennungen'";
CM_ SG_ 786 FAS_Wunschgeschw "Zur Anzeige der Wunschgeschwindigkeit im Kombiinstrument";
CM_ SG_ 786 FAS_Status_Prim_Anz "Ansteuerung einer primären Statusanzeige für ACC/GRA in verschiedenen Farben";
CM_ SG_ 786 FAS_Texte_Primaeranz "Weitere Textdefinitionen im DBC-File!";
CM_ SG_ 786 FAS_Status_Anzeige "Analog zum Status nur zur Defintion von Anzeige im Kombi. Hinweis: Wird für die spez. VW-Anzeige (überlappende Anzeigebereiche) verwendet. Vom AUDI-ACC im Rahmen der Modulstrategie zu bedienen.
";
CM_ SG_ 270 TSK_04_CHK "Berechnung siehe Lastenheft 'Kommunikationsabsicherung für FlexRay und CAN'
Endwerte siehe 'Kommunikationsabsicherung für FlexRay und CAN / Anhang C: Tabelle S-PDU Kennungen'";
CM_ SG_ 270 TSK_zul_Regelabw "Anforderung der zulässigen Regelabweichung vom Triebstrangkoordinator. Zulässiger Betrag der Abweichung zwischen angeforderter 'TSK_Sollbeschleunigung_Getriebe' und umzusetzender Sollbeschleunigung  im Getriebe. Im TSK wird, abhängig vom Arbeitspunkt die ";
CM_ SG_ 270 TSK_ax_Getriebe "Beschleunigungsanforderung des Beschleunigungsreglers (u. a. für ACC, GRA, Speed Limiter). Das Signal wird vom Getriebe benutzt, um die von GRA/ACC geforderte Sollbeschleunigung in dem verbrauchsgünstigsten Gang einzustellen.";
CM_ SG_ 270 TSK_Wunsch_Uebersetz "Bei ACC/GRA Betrieb bergab teilt der TSK dem Getriebe mit, dass eine Drehzahlerhöhung erwünscht ist, um mehr Schleppmoment und damit verbunden die nötige Verzögerung zu erzeugen, um die Geschwindigkeit konstant zu halten. 

Nutzung im VL: das Getriebe v";
CM_ SG_ 270 TSK_Freig_WU "Freigabe des TSK_Übersetzungswunsches bei ACC/GRA Betrieb bergab für die Verstellung nach kurz bzw. Rückschaltung im Getriebe.";
CM_ SG_ 270 TSK_Limiter_aktiv "Information, ob der Höchstgeschwindigkeitsbegrenzer aktiv ist. Beim gesetzten Bit kann das Getriebe hochschalten, unabhängig vom Fahrpedal";
CM_ SG_ 270 TSK_Status_GRA_ACC_02 "Signal redundant zu 'TSK_Status_GRA_ACC_01' in TSK_02, um für das Getriebe die einzulesenden Botschaften zu definieren.  

Die Zustände 0x1 und 0x2 werden vom Motor auch bei ACC gesetzt, wegen Umsetzung des Triebsstrangkoordinators im Motor. ";
CM_ SG_ 273 TSK_05_CHK "Berechnung siehe Lastenheft 'Kommunikationsabsicherung für FlexRay und CAN'
Endwerte siehe 'Kommunikationsabsicherung für FlexRay und CAN / Anhang C: Tabelle S-PDU Kennungen'";
CM_ SG_ 273 TSK_Status_GRA_ACC_01 "Die Zustände 0x1 und 0x2 werden vom Motor auch bei ACC gesetzt, wegen Umsetzung des Triebsstrangkoordinators im Motor. ";
CM_ SG_ 273 TSK_Fahrzeugmasse "Fahrzeugmasse in kg. Das Signal dient der Anpassung der Sollbeschleunigung vom ACC

Init (entspricht phys. 500kg)
";
CM_ SG_ 273 TSK_Fahrzeugmasse_02 "Neue Definition ab D4
Fahrzeugmasse in kg. Das Signal dient der Anpassung der Sollbeschleunigung vom ACC


";
CM_ SG_ 273 TSK_Steigung "Steigung in % Berg. Das Signal dient der Anpassung der Sollbeschleunigung vom ACC

Positive Werte > bergauf; 
Negative Werte < bergab

Fehler: Die Steigung aufgrund eines Fehlers (mit KD-Fehlereintrag) nicht mehr berechnet werden";
CM_ SG_ 273 TSK_Codierung_ACC "Information über den plausibilisierten Codierungszustand des Triebstrangskoordinators auf ACC.";
CM_ SG_ 273 TSK_Zwangszusch_ESP "Mit diesem Bit wird das ESP/ASR zwangsweise aktiviert. Bei gesetztem Bit ist ein ausgetastetes ESP (oder ASR) wieder aktiviert bzw. wird die Austastung verhindert.";
CM_ SG_ 273 TSK_Freig_Verzoeg_Anf "Freigabe der Verzögerungsanforderung der ACC oder ggf. GRA+ Funktion für ECD Regelung im ESP";
CM_ SG_ 273 TSK_Verzoeg_Anf_02 "D4: Verzögerungsanforderung der ACC oder ggf. GRA+ Funktion für ECD Regelung im ESP";
CM_ BO_ 1716 "200ms bei D4 und folgende";
CM_ SG_ 1716 VIN_01_MUX "Achtung:
Die Botschaft ist nicht linear gemultiplext!!!
Sondern 0,1,0,2,0, usw.";
CM_ SG_ 1716 VIN_4 "Initwert:
0x2D bei Fahrzeugen mit Wegfahrsperrengeneration >= 5 
0x58 bei Fahrzeugen mit Wegfahrsperrengeneration < 5 (z.B. WFS-4)";
CM_ SG_ 1716 VIN_11 "Initwert:
0x2D bei Fahrzeugen mit Wegfahrsperrengeneration >= 5 
0x58 bei Fahrzeugen mit Wegfahrsperrengeneration < 5 (z.B. WFS-4)";
CM_ SG_ 1716 VIN_5 "Initwert:
0x2D bei Fahrzeugen mit Wegfahrsperrengeneration >= 5 
0x58 bei Fahrzeugen mit Wegfahrsperrengeneration < 5 (z.B. WFS-4)";
CM_ SG_ 1716 VIN_12 "Initwert:
0x2D bei Fahrzeugen mit Wegfahrsperrengeneration >= 5 
0x58 bei Fahrzeugen mit Wegfahrsperrengeneration < 5 (z.B. WFS-4)";
CM_ SG_ 1716 VIN_6 "Initwert:
0x2D bei Fahrzeugen mit Wegfahrsperrengeneration >= 5 
0x58 bei Fahrzeugen mit Wegfahrsperrengeneration < 5 (z.B. WFS-4)";
CM_ SG_ 1716 VIN_13 "Initwert:
0x2D bei Fahrzeugen mit Wegfahrsperrengeneration >= 5 
0x58 bei Fahrzeugen mit Wegfahrsperrengeneration < 5 (z.B. WFS-4)";
CM_ SG_ 1716 VIN_7 "Initwert:
0x2D bei Fahrzeugen mit Wegfahrsperrengeneration >= 5 
0x58 bei Fahrzeugen mit Wegfahrsperrengeneration < 5 (z.B. WFS-4)";
CM_ SG_ 1716 VIN_14 "Initwert:
0x2D bei Fahrzeugen mit Wegfahrsperrengeneration >= 5 
0x58 bei Fahrzeugen mit Wegfahrsperrengeneration < 5 (z.B. WFS-4)";
CM_ SG_ 1716 VIN_1 "Initwert:
0x2D bei Fahrzeugen mit Wegfahrsperrengeneration >= 5 
0x58 bei Fahrzeugen mit Wegfahrsperrengeneration < 5 (z.B. WFS-4)";
CM_ SG_ 1716 VIN_8 "Initwert:
0x2D bei Fahrzeugen mit Wegfahrsperrengeneration >= 5 
0x58 bei Fahrzeugen mit Wegfahrsperrengeneration < 5 (z.B. WFS-4)";
CM_ SG_ 1716 VIN_15 "Initwert:
0x2D bei Fahrzeugen mit Wegfahrsperrengeneration >= 5 
0x58 bei Fahrzeugen mit Wegfahrsperrengeneration < 5 (z.B. WFS-4)";
CM_ SG_ 1716 VIN_2 "Initwert:
0x2D bei Fahrzeugen mit Wegfahrsperrengeneration >= 5 
0x58 bei Fahrzeugen mit Wegfahrsperrengeneration < 5 (z.B. WFS-4)";
CM_ SG_ 1716 VIN_9 "Initwert:
0x2D bei Fahrzeugen mit Wegfahrsperrengeneration >= 5 
0x58 bei Fahrzeugen mit Wegfahrsperrengeneration < 5 (z.B. WFS-4)";
CM_ SG_ 1716 VIN_16 "Initwert:
0x2D bei Fahrzeugen mit Wegfahrsperrengeneration >= 5 
0x58 bei Fahrzeugen mit Wegfahrsperrengeneration < 5 (z.B. WFS-4)";
CM_ SG_ 1716 VIN_3 "Initwert:
0x2D bei Fahrzeugen mit Wegfahrsperrengeneration >= 5 
0x58 bei Fahrzeugen mit Wegfahrsperrengeneration < 5 (z.B. WFS-4)";
CM_ SG_ 1716 VIN_10 "Initwert:
0x2D bei Fahrzeugen mit Wegfahrsperrengeneration >= 5 
0x58 bei Fahrzeugen mit Wegfahrsperrengeneration < 5 (z.B. WFS-4)";
CM_ SG_ 1716 VIN_17 "Initwert:
0x2D bei Fahrzeugen mit Wegfahrsperrengeneration >= 5 
0x58 bei Fahrzeugen mit Wegfahrsperrengeneration < 5 (z.B. WFS-4)";
CM_ SG_ 1414 WH_KD_Fehler "Wählhebel-SG Status Kundendienstfehlerspeichereinträge
";
CM_ SG_ 915 WBA_02_CHK "Berechnung siehe Lastenheft 'Kommunikationsabsicherung für FlexRay und CAN'
Endwerte siehe 'Kommunikationsabsicherung für FlexRay und CAN / Anhang C: Tabelle S-PDU Kennungen'";
CM_ SG_ 915 WBA_Senderkennung "Die Botschaft WBA_02 wird vom Automatgetriebe gesendet, bei Handschaltern alternativ vom Motor. Das Getriebe stellt damit die Wählbereichsanzeige dar, der Motor beim Handschalter die Hochschaltaufforderung für den Fahrer im Kombi. Zur Unterscheidung des S";
CM_ SG_ 915 WBA_Lampe_Shift_Lock "Im Kombi wird Anzeige im Mitteldisplay geschaltet: 'Zum Einlegen einer Fahrstufe bitte Bremse betätigen' - nur falls WBA_Senderkennung = 00 (GSG)

";
CM_ SG_ 915 WBA_Schaltempf_verfbar "Info, ob Schaltempfehlung im Fzg. verfügbar. Statischer Wert, ändert sich für ein Fzg nicht - nur falls WBA_Senderkennung = 01 (MSG)";
CM_ SG_ 915 WBA_Effizienzmodus "Bei Handschaltern wird  das Fahrprogramm Effizienz signalisiert. 
Bei Automatikgetrieben wird das Fahrprogramm 'D' durch 'E' ersetzt.";
CM_ SG_ 915 WBA_Kurzzeittipp "Signalisiert die Aktivierung des Kurzzeittipp-Mode";
CM_ SG_ 915 WBA_Blinken "Dieses Bit steuert die Fehlerlampe an oder wird zum Blinken der WBA-Anzeige genutzt - nur falls WBA_Senderkennung = 00 (GSG)
";
CM_ SG_ 915 WBA_Getriebevariante "Verwendete Getriebe-Variante im Fahrzeug, Kombi stellt entsprechende WBA dar (bspw. PRNDS). Nur falls WBA_Senderkennung = 00 (GSG).
";
CM_ SG_ 915 WBA_GE_Warnung "Prioritaetswarnungen Getriebe mit Shift by wire
Werte 6 und 7 werden seitens Audi nicht bedient";
CM_ SG_ 915 WBA_Fahrstufe "Bei Automatgetrieben wird in diesem Signal die aktuelle Fahrstufe (=Wählhebelposition) ausgegeben. Nur falls WBA_Senderkennung = 00 (GSG):

Im Automatik-Betrieb:
0x0 = Zwischenstellung, keine Position  (Normaldarstellung aller Fahrstufen)
0x1 = Getrie";
CM_ SG_ 915 WBA_Istgang "Wenn Motor die WBA-Botschaft sendet wird in diesem Signal der aktuelle Gang ausgegeben (= Istgang des Schaltgetriebes). Nur falls WBA_Senderkennung = 01 (MSG).

0x7 - 0xF = tbd.

Anzeige im Kombi:
Sollgang == Istgang         ==> Anzeige Istgang
Soll";
CM_ SG_ 915 WBA_eing_Gang "Das Automatgetriebe gibt den aktuell eingelegten Gang aus. Nur falls WBA_Senderkennung = 00 (GSG)

0xB - 0xF = tbd.";
CM_ SG_ 915 WBA_Sollgang "Motor sendet den Sollgang in den der Fahrer schalten soll. Wird im Kombi als Hochschaltempfehlung hervorgehoben. Nur falls WBA_Senderkennung = 01 (MSG)

0x7 - 0xF = tbd.

Anzeige im Kombi:
Sollgang == Istgang          ==> Anzeige Istgang
Sollgang !=";
CM_ SG_ 915 WBA_GE_Texte "Fahrerhinweise für das Kombi";
CM_ SG_ 915 WBA_Schaltschema_Aktiv "Anforderung Getriebe zur Anzeige des Schaltschemas im Kombi";
CM_ SG_ 915 WH_Warnung "Warntexte vom Waehlhebel";
CM_ SG_ 915 WBA_GE_Zusatzwarnungen "Prioritaetswarnungen Getriebe an Kombi
Audi MLB Wertebereich 0 bis 3
VW MQB Projekte verwenden nur den Wertebereich 0 bis 2
VW MQB Getriebefehler werden über das Signal  GE_Warnungen_02 gesendet.";
CM_ SG_ 915 WBA_Segeln_aktiv "Getriebe geht in den Segelbetrieb";
CM_ SG_ 915 GE_Tipschaltempf_verfuegbar "Signalisierung, ob eine Hochschaltempfehlung im Tipmodus verfügbar ist oder nicht.";
CM_ SG_ 915 GE_Sollgang "Signalisiert den Sollgang, in den getippt werden soll. Abhängig vom Signal 'WBA_eing_Gang_02' und dem Sollgang kann dann das Kombi die Hochschaltempfehlung in Tip darstellen.";
CM_ SG_ 1602 WIV_Verschleissindex "Bei Otto Verbrauch, bei Diesel Verschleiss";
CM_ SG_ 1602 WIV_Russindex "Nur für Diesel, Rußwert, bei Otto Wert = 0";
CM_ SG_ 1602 WIV_t_min "Minimales Wartungsintervall für WIV in Monaten";
CM_ SG_ 1602 WIV_t_max "Maximales Wartungsintervall für WIV in Monaten";
CM_ SG_ 1602 WIV_W_min "Minimales Wartungsintervall für WIV in km";
CM_ SG_ 1602 WIV_W_max "Maximales Wartungsintervall für WIV in km";
BA_DEF_ BO_  "DiagRequest" ENUM  "No","Yes";
BA_DEF_ BO_  "DiagResponse" ENUM  "No","Yes";
BA_DEF_ BO_  "DiagState" ENUM  "No","Yes";
BA_DEF_ BO_  "GenMsgChkConstant" HEX 0 4095;
BA_DEF_ BO_  "GenMsgCycleTime" INT 0 65535;
BA_DEF_ BO_  "GenMsgCycleTimeFast" INT 0 65535;
BA_DEF_ BO_  "GenMsgDelayTime" INT 0 100000;
BA_DEF_ BO_  "GenMsgILSupport" ENUM  "No","Yes";
BA_DEF_ BO_  "GenMsgNrOfRepetition" INT 0 100;
BA_DEF_ BO_  "GenMsgPDUConstants" STRING ;
BA_DEF_ BO_  "GenMsgSendType" ENUM  "Cyclic","not_used","not_used","not_used","not_used","not_used","not_used","IfActive","NoMsgSendType";
BA_DEF_ BO_  "GenMsgStartDelayTime" INT 0 100000;
BA_DEF_ BO_  "NmMessage" ENUM  "No","Yes";
BA_DEF_ BO_  "NmhMessage" ENUM  "No","Yes";
BA_DEF_ BO_  "MsgType" ENUM  "Application","NM ","NMH","TP2.0","ISO-TP ","BAP","EID";
BA_DEF_ BO_  "VAGTP20_API" HEX 0 255;
BA_DEF_ BO_  "VAGTP20_DynConnection" ENUM  "No","Yes";
BA_DEF_ BO_  "VAGTP20_DynSetup" ENUM  "No","Yes";
BA_DEF_ BO_  "VAGTP20_StatConnection" ENUM  "No","Yes";
BA_DEF_ SG_  "GenSigActiveRepetitions" INT -2147483648 2147483647;
BA_DEF_ SG_  "GenSigInactiveValue" INT -2147483648 2147483647;
BA_DEF_ SG_  "GenSigSendType" ENUM  "Cyclic","OnWrite","OnWriteWithRepetition","OnChange","OnChangeWithRepetition","IfActive","IfActiveWithRepetition","NoSigSendType","OnChangeAndIfActive","OnChangeAndIfActiveWithRepetition";
BA_DEF_ SG_  "GenSigStartValue" INT -2147483648 2147483647;
BA_DEF_ SG_  "NWM-WakeupAllowed" ENUM  "No","Yes";
BA_DEF_ SG_  "GenSigFuncType" ENUM  "NoFunction","MsgCounter","CRC-8","XOR","XOR-2","DatedBit","SW-Kl15","CHK","Constant","Protocol","CRC-8-SAE_J1850";
BA_DEF_ SG_  "GenSigSwitchedByIgnition" ENUM  "No","Yes";
BA_DEF_ SG_  "Fehlerwert" HEX 0 2147483647;
BA_DEF_ SG_  "GenSigMissingSourceValue" HEX 0 2147483647;
BA_DEF_REL_ BU_SG_REL_  "GenSigTimeoutTime" INT 0 65535;
BA_DEF_DEF_REL_ "GenSigTimeoutTime" 0;
BA_DEF_DEF_  "DiagRequest" "No";
BA_DEF_DEF_  "DiagResponse" "No";
BA_DEF_DEF_  "DiagState" "No";
BA_DEF_DEF_  "GenMsgChkConstant" 0;
BA_DEF_DEF_  "GenMsgCycleTime" 0;
BA_DEF_DEF_  "GenMsgCycleTimeFast" 0;
BA_DEF_DEF_  "GenMsgDelayTime" 0;
BA_DEF_DEF_  "GenMsgILSupport" "No";
BA_DEF_DEF_  "GenMsgNrOfRepetition" 0;
BA_DEF_DEF_  "GenMsgPDUConstants" "";
BA_DEF_DEF_  "GenMsgSendType" "NoMsgSendType";
BA_DEF_DEF_  "GenMsgStartDelayTime" 0;
BA_DEF_DEF_  "NmMessage" "No";
BA_DEF_DEF_  "NmhMessage" "No";
BA_DEF_DEF_  "MsgType" "Application";
BA_DEF_DEF_  "VAGTP20_API" 0;
BA_DEF_DEF_  "VAGTP20_DynConnection" "No";
BA_DEF_DEF_  "VAGTP20_DynSetup" "No";
BA_DEF_DEF_  "VAGTP20_StatConnection" "No";
BA_DEF_DEF_  "GenSigActiveRepetitions" 0;
BA_DEF_DEF_  "GenSigInactiveValue" 0;
BA_DEF_DEF_  "GenSigSendType" "NoSigSendType";
BA_DEF_DEF_  "GenSigStartValue" 0;
BA_DEF_DEF_  "NWM-WakeupAllowed" "No";
BA_DEF_DEF_  "GenSigFuncType" "NoFunction";
BA_DEF_DEF_  "GenSigSwitchedByIgnition" "Yes";
BA_DEF_DEF_  "Fehlerwert" 0;
BA_DEF_DEF_  "GenSigMissingSourceValue" 0;
BA_ "GenMsgSendType" BO_ 913 0;
BA_ "GenMsgILSupport" BO_ 913 1;
BA_ "GenMsgCycleTime" BO_ 913 100;
BA_ "GenMsgSendType" BO_ 1630 0;
BA_ "GenMsgILSupport" BO_ 1630 1;
BA_ "GenMsgCycleTime" BO_ 1630 500;
BA_ "GenMsgSendType" BO_ 803 0;
BA_ "GenMsgPDUConstants" BO_ 803 "0x20,0x20,0x20,0x20,0x20,0x20,0x20,0x20,0x20,0x20,0x20,0x20,0x20,0x20,0x20,0x20";
BA_ "GenMsgILSupport" BO_ 803 1;
BA_ "GenMsgCycleTime" BO_ 803 40;
BA_ "GenMsgChkConstant" BO_ 803 32;
BA_ "GenMsgSendType" BO_ 802 0;
BA_ "GenMsgILSupport" BO_ 802 1;
BA_ "GenMsgCycleTime" BO_ 802 40;
BA_ "GenMsgSendType" BO_ 929 0;
BA_ "GenMsgILSupport" BO_ 929 1;
BA_ "GenMsgCycleTime" BO_ 929 150;
BA_ "GenMsgSendType" BO_ 930 0;
BA_ "GenMsgILSupport" BO_ 930 1;
BA_ "GenMsgCycleTime" BO_ 930 150;
BA_ "GenMsgSendType" BO_ 1528 0;
BA_ "GenMsgILSupport" BO_ 1528 1;
BA_ "GenMsgCycleTime" BO_ 1528 1000;
BA_ "GenMsgSendType" BO_ 1011 0;
BA_ "GenMsgILSupport" BO_ 1011 1;
BA_ "GenMsgCycleTime" BO_ 1011 100;
BA_ "GenMsgSendType" BO_ 1507 0;
BA_ "GenMsgILSupport" BO_ 1507 1;
BA_ "GenMsgCycleTime" BO_ 1507 500;
BA_ "GenMsgSendType" BO_ 1508 0;
BA_ "GenMsgILSupport" BO_ 1508 1;
BA_ "GenMsgDelayTime" BO_ 1508 50;
BA_ "GenMsgCycleTime" BO_ 1508 500;
BA_ "GenMsgSendType" BO_ 1509 0;
BA_ "GenMsgILSupport" BO_ 1509 1;
BA_ "GenMsgCycleTime" BO_ 1509 1000;
BA_ "GenMsgSendType" BO_ 1526 0;
BA_ "GenMsgILSupport" BO_ 1526 1;
BA_ "GenMsgDelayTime" BO_ 1526 50;
BA_ "GenMsgCycleTime" BO_ 1526 500;
BA_ "GenMsgSendType" BO_ 1510 0;
BA_ "GenMsgILSupport" BO_ 1510 1;
BA_ "GenMsgCycleTime" BO_ 1510 1000;
BA_ "GenMsgSendType" BO_ 1512 0;
BA_ "GenMsgILSupport" BO_ 1512 1;
BA_ "GenMsgCycleTime" BO_ 1512 1000;
BA_ "GenMsgSendType" BO_ 133 0;
BA_ "GenMsgPDUConstants" BO_ 133 "0x85,0x85,0x85,0x85,0x85,0x85,0x85,0x85,0x85,0x85,0x85,0x85,0x85,0x85,0x85,0x85";
BA_ "GenMsgILSupport" BO_ 133 1;
BA_ "GenMsgCycleTime" BO_ 133 10;
BA_ "GenMsgChkConstant" BO_ 133 133;
BA_ "GenMsgSendType" BO_ 784 0;
BA_ "GenMsgILSupport" BO_ 784 1;
BA_ "GenMsgCycleTime" BO_ 784 50;
BA_ "MsgType" BO_ 2549875324 4;
BA_ "DiagRequest" BO_ 2549875324 1;
BA_ "MsgType" BO_ 2550006396 4;
BA_ "DiagResponse" BO_ 2550006396 1;
BA_ "MsgType" BO_ 2549875319 4;
BA_ "DiagRequest" BO_ 2549875319 1;
BA_ "MsgType" BO_ 2550006391 4;
BA_ "DiagResponse" BO_ 2550006391 1;
BA_ "MsgType" BO_ 2549875323 4;
BA_ "DiagRequest" BO_ 2549875323 1;
BA_ "MsgType" BO_ 2550006395 4;
BA_ "DiagResponse" BO_ 2550006395 1;
BA_ "MsgType" BO_ 2549875318 4;
BA_ "DiagRequest" BO_ 2549875318 1;
BA_ "MsgType" BO_ 2550006390 4;
BA_ "DiagResponse" BO_ 2550006390 1;
BA_ "MsgType" BO_ 2549875320 4;
BA_ "DiagRequest" BO_ 2549875320 1;
BA_ "MsgType" BO_ 2550006392 4;
BA_ "DiagResponse" BO_ 2550006392 1;
BA_ "GenMsgSendType" BO_ 1313 0;
BA_ "GenMsgILSupport" BO_ 1313 1;
BA_ "GenMsgCycleTime" BO_ 1313 200;
BA_ "GenMsgSendType" BO_ 1172 0;
BA_ "GenMsgPDUConstants" BO_ 1172 "0x90,0x90,0x90,0x90,0x90,0x90,0x90,0x90,0x90,0x90,0x90,0x90,0x90,0x90,0x90,0x90";
BA_ "GenMsgILSupport" BO_ 1172 1;
BA_ "GenMsgDelayTime" BO_ 1172 20;
BA_ "GenMsgCycleTime" BO_ 1172 200;
BA_ "GenMsgChkConstant" BO_ 1172 144;
BA_ "GenMsgSendType" BO_ 1413 0;
BA_ "GenMsgILSupport" BO_ 1413 1;
BA_ "GenMsgDelayTime" BO_ 1413 10;
BA_ "GenMsgCycleTime" BO_ 1413 1000;
BA_ "VAGTP20_DynConnection" BO_ 1196 1;
BA_ "MsgType" BO_ 1196 3;
BA_ "VAGTP20_DynConnection" BO_ 1214 1;
BA_ "MsgType" BO_ 1214 3;
BA_ "VAGTP20_DynConnection" BO_ 768 1;
BA_ "MsgType" BO_ 768 3;
BA_ "VAGTP20_DynConnection" BO_ 769 1;
BA_ "MsgType" BO_ 769 3;
BA_ "VAGTP20_DynConnection" BO_ 770 1;
BA_ "MsgType" BO_ 770 3;
BA_ "VAGTP20_DynConnection" BO_ 771 1;
BA_ "MsgType" BO_ 771 3;
BA_ "VAGTP20_DynConnection" BO_ 772 1;
BA_ "MsgType" BO_ 772 3;
BA_ "VAGTP20_DynConnection" BO_ 773 1;
BA_ "MsgType" BO_ 773 3;
BA_ "VAGTP20_DynConnection" BO_ 774 1;
BA_ "MsgType" BO_ 774 3;
BA_ "VAGTP20_DynConnection" BO_ 775 1;
BA_ "MsgType" BO_ 775 3;
BA_ "VAGTP20_DynSetup" BO_ 524 1;
BA_ "MsgType" BO_ 524 3;
BA_ "VAGTP20_DynSetup" BO_ 542 1;
BA_ "MsgType" BO_ 542 3;
BA_ "VAGTP20_DynSetup" BO_ 512 1;
BA_ "MsgType" BO_ 512 3;
BA_ "GenMsgSendType" BO_ 786 0;
BA_ "GenMsgPDUConstants" BO_ 786 "0x11,0x11,0x11,0x11,0x11,0x11,0x11,0x11,0x11,0x11,0x11,0x11,0x11,0x11,0x11,0x11";
BA_ "GenMsgILSupport" BO_ 786 1;
BA_ "GenMsgDelayTime" BO_ 786 10;
BA_ "GenMsgCycleTime" BO_ 786 50;
BA_ "GenMsgChkConstant" BO_ 786 17;
BA_ "GenMsgSendType" BO_ 270 0;
BA_ "GenMsgPDUConstants" BO_ 270 "0x0f,0x0f,0x0f,0x0f,0x0f,0x0f,0x0f,0x0f,0x0f,0x0f,0x0f,0x0f,0x0f,0x0f,0x0f,0x0f";
BA_ "GenMsgILSupport" BO_ 270 1;
BA_ "GenMsgCycleTime" BO_ 270 20;
BA_ "GenMsgChkConstant" BO_ 270 15;
BA_ "GenMsgSendType" BO_ 273 0;
BA_ "GenMsgPDUConstants" BO_ 273 "0x10,0x10,0x10,0x10,0x10,0x10,0x10,0x10,0x10,0x10,0x10,0x10,0x10,0x10,0x10,0x10";
BA_ "GenMsgILSupport" BO_ 273 1;
BA_ "GenMsgCycleTime" BO_ 273 20;
BA_ "GenMsgChkConstant" BO_ 273 16;
BA_ "GenMsgSendType" BO_ 1716 0;
BA_ "GenMsgILSupport" BO_ 1716 1;
BA_ "GenMsgCycleTime" BO_ 1716 200;
BA_ "GenMsgSendType" BO_ 1414 0;
BA_ "GenMsgILSupport" BO_ 1414 1;
BA_ "GenMsgDelayTime" BO_ 1414 50;
BA_ "GenMsgCycleTime" BO_ 1414 500;
BA_ "GenMsgSendType" BO_ 915 0;
BA_ "GenMsgPDUConstants" BO_ 915 "0x90,0x90,0x90,0x90,0x90,0x90,0x90,0x90,0x90,0x90,0x90,0x90,0x90,0x90,0x90,0x90";
BA_ "GenMsgILSupport" BO_ 915 1;
BA_ "GenMsgDelayTime" BO_ 915 10;
BA_ "GenMsgCycleTime" BO_ 915 80;
BA_ "GenMsgChkConstant" BO_ 915 144;
BA_ "GenMsgSendType" BO_ 1602 0;
BA_ "GenMsgILSupport" BO_ 1602 1;
BA_ "GenMsgCycleTime" BO_ 1602 2000;
BA_ "MsgType" BO_ 2616990720 6;
BA_ "MsgType" BO_ 2616990724 6;
BA_ "GenSigSwitchedByIgnition" SG_ 913 OBD_Calc_Load_Val 0;
BA_ "GenSigStartValue" SG_ 913 OBD_Calc_Load_Val 255;
BA_ "GenSigSendType" SG_ 913 OBD_Calc_Load_Val 0;
BA_ "GenSigSwitchedByIgnition" SG_ 913 OBD_Eng_Cool_Temp 0;
BA_ "GenSigStartValue" SG_ 913 OBD_Eng_Cool_Temp 255;
BA_ "GenSigSendType" SG_ 913 OBD_Eng_Cool_Temp 0;
BA_ "GenSigSwitchedByIgnition" SG_ 913 OBD_Abs_Throttle_Pos 0;
BA_ "GenSigStartValue" SG_ 913 OBD_Abs_Throttle_Pos 255;
BA_ "GenSigSendType" SG_ 913 OBD_Abs_Throttle_Pos 0;
BA_ "GenSigSwitchedByIgnition" SG_ 913 OBD_Abs_Load_Val 0;
BA_ "GenSigStartValue" SG_ 913 OBD_Abs_Load_Val 65535;
BA_ "GenSigSendType" SG_ 913 OBD_Abs_Load_Val 0;
BA_ "GenSigSwitchedByIgnition" SG_ 913 OBD_Abs_Pedal_Pos 0;
BA_ "GenSigStartValue" SG_ 913 OBD_Abs_Pedal_Pos 255;
BA_ "GenSigSendType" SG_ 913 OBD_Abs_Pedal_Pos 0;
BA_ "GenSigSwitchedByIgnition" SG_ 913 OBD_Sperrung_IUMPR 0;
BA_ "GenSigSendType" SG_ 913 OBD_Sperrung_IUMPR 0;
BA_ "GenSigSwitchedByIgnition" SG_ 913 OBD_Kaltstart_Denominator 0;
BA_ "GenSigSendType" SG_ 913 OBD_Kaltstart_Denominator 0;
BA_ "GenSigSwitchedByIgnition" SG_ 913 OBD_Minimum_Trip 0;
BA_ "GenSigSendType" SG_ 913 OBD_Minimum_Trip 0;
BA_ "GenSigSwitchedByIgnition" SG_ 913 OBD_Driving_Cycle 0;
BA_ "GenSigSendType" SG_ 913 OBD_Driving_Cycle 0;
BA_ "GenSigSwitchedByIgnition" SG_ 913 OBD_Warm_Up_Cycle 0;
BA_ "GenSigSendType" SG_ 913 OBD_Warm_Up_Cycle 0;
BA_ "GenSigSwitchedByIgnition" SG_ 913 OBD_Normed_Trip 0;
BA_ "GenSigSendType" SG_ 913 OBD_Normed_Trip 0;
BA_ "GenSigSwitchedByIgnition" SG_ 1630 OBD_TG_F_Status_1 0;
BA_ "GenSigSendType" SG_ 1630 OBD_TG_F_Status_1 0;
BA_ "GenSigSwitchedByIgnition" SG_ 1630 OBD_TG_F_Status_2 0;
BA_ "GenSigSendType" SG_ 1630 OBD_TG_F_Status_2 0;
BA_ "GenSigSwitchedByIgnition" SG_ 1630 OBD_TG_F_Status_3 0;
BA_ "GenSigSendType" SG_ 1630 OBD_TG_F_Status_3 0;
BA_ "GenSigSwitchedByIgnition" SG_ 1630 OBD_TG_F_Status_4 0;
BA_ "GenSigSendType" SG_ 1630 OBD_TG_F_Status_4 0;
BA_ "GenSigSwitchedByIgnition" SG_ 1630 OBD_TG_Sens_Rohwert_1 0;
BA_ "GenSigSendType" SG_ 1630 OBD_TG_Sens_Rohwert_1 0;
BA_ "GenSigSwitchedByIgnition" SG_ 1630 OBD_TG_Sens_Rohwert_2 0;
BA_ "GenSigSendType" SG_ 1630 OBD_TG_Sens_Rohwert_2 0;
BA_ "GenSigSwitchedByIgnition" SG_ 1630 OBD_TG_Sens_Rohwert_3 0;
BA_ "GenSigSendType" SG_ 1630 OBD_TG_Sens_Rohwert_3 0;
BA_ "GenSigSwitchedByIgnition" SG_ 1630 OBD_TG_Sens_Rohwert_4 0;
BA_ "GenSigSendType" SG_ 1630 OBD_TG_Sens_Rohwert_4 0;
BA_ "GenSigFuncType" SG_ 803 PCF_01_CRC 2;
BA_ "GenSigSendType" SG_ 803 PCF_01_CRC 0;
BA_ "GenSigFuncType" SG_ 803 PCF_01_BZ 1;
BA_ "GenSigSendType" SG_ 803 PCF_01_BZ 0;
BA_ "GenSigSendType" SG_ 803 PCF_Objektstatus 0;
BA_ "GenSigStartValue" SG_ 803 PCF_Fahrer_aktiv_erkannt 1;
BA_ "GenSigSendType" SG_ 803 PCF_Fahrer_aktiv_erkannt 0;
BA_ "GenSigStartValue" SG_ 803 PCF_Time_to_collision 255;
BA_ "GenSigSendType" SG_ 803 PCF_Time_to_collision 0;
BA_ "GenSigSendType" SG_ 803 PCF_v_rel 0;
BA_ "GenSigStartValue" SG_ 803 PCF_dy_Kollisionsueberdeckung 31;
BA_ "GenSigSendType" SG_ 803 PCF_dy_Kollisionsueberdeckung 0;
BA_ "GenSigSendType" SG_ 802 PCR_Sensorstatus 0;
BA_ "Fehlerwert" SG_ 802 PCR_Obj_vx_rel 2047;
BA_ "GenSigSendType" SG_ 802 PCR_Obj_vx_rel 0;
BA_ "Fehlerwert" SG_ 802 PCR_Obj_vy_rel 2047;
BA_ "GenSigSendType" SG_ 802 PCR_Obj_vy_rel 0;
BA_ "Fehlerwert" SG_ 802 PCR_Obj_TTC 511;
BA_ "GenSigStartValue" SG_ 802 PCR_Obj_TTC 510;
BA_ "GenSigSendType" SG_ 802 PCR_Obj_TTC 0;
BA_ "Fehlerwert" SG_ 802 PCR_Obj_Guete 127;
BA_ "GenSigSendType" SG_ 802 PCR_Obj_Guete 0;
BA_ "Fehlerwert" SG_ 802 PCR_Crashwahrscheinlichkeit 127;
BA_ "GenSigSendType" SG_ 802 PCR_Crashwahrscheinlichkeit 0;
BA_ "GenSigSwitchedByIgnition" SG_ 802 PCR_Sensorstatus_02 0;
BA_ "GenSigSendType" SG_ 802 PCR_Sensorstatus_02 0;
BA_ "GenSigSendType" SG_ 929 PSD_Pos_Segment_ID 0;
BA_ "GenSigSendType" SG_ 929 PSD_Pos_Segmentlaenge 0;
BA_ "GenSigSendType" SG_ 929 PSD_Pos_Inhibitzeit 0;
BA_ "GenSigSendType" SG_ 929 PSD_Pos_Standort 0;
BA_ "GenSigSendType" SG_ 929 PSD_Pos_Laengsfehler 0;
BA_ "GenSigSendType" SG_ 929 PSD_Segment_ID 0;
BA_ "GenSigSendType" SG_ 929 PSD_Vorgaenger_Segment_ID 0;
BA_ "GenSigSendType" SG_ 929 PSD_Strassenklasse 0;
BA_ "GenSigSendType" SG_ 929 PSD_Segmentlaenge 0;
BA_ "GenSigSendType" SG_ 929 PSD_Rampe 0;
BA_ "GenSigSendType" SG_ 929 PSD_Endkruemmung 0;
BA_ "GenSigSendType" SG_ 929 PSD_Endkruemmung_Vorz 0;
BA_ "GenSigSendType" SG_ 929 PSD_Endsteigung 0;
BA_ "GenSigSendType" SG_ 929 PSD_Endsteigung_Vorz 0;
BA_ "GenSigSendType" SG_ 929 PSD_ADAS_Qualitaet 0;
BA_ "GenSigStartValue" SG_ 929 PSD_Fahrspuren 1;
BA_ "GenSigSendType" SG_ 929 PSD_Fahrspuren 0;
BA_ "GenSigSendType" SG_ 929 PSD_wahrscheinlichster_Pfad 0;
BA_ "GenSigSendType" SG_ 930 PSD_Multiplex 0;
BA_ "GenSigStartValue" SG_ 930 PSD_Abz_Fahrspuren 1;
BA_ "GenSigSendType" SG_ 1528 SAK_Charisma_FahrPr 0;
BA_ "GenSigSendType" SG_ 1528 SAK_Charisma_Status 0;
BA_ "GenSigSendType" SG_ 1528 SAK_Charisma_Umschaltung 0;
BA_ "GenSigSendType" SG_ 1528 SAK_KD_Fehler 0;
BA_ "GenSigSwitchedByIgnition" SG_ 1011 SCR_01_BZ 0;
BA_ "GenSigFuncType" SG_ 1011 SCR_01_BZ 1;
BA_ "GenSigSendType" SG_ 1011 SCR_01_BZ 0;
BA_ "GenSigSwitchedByIgnition" SG_ 1011 SCR_QBit_Level_Aktivtank_02 0;
BA_ "GenSigStartValue" SG_ 1011 SCR_QBit_Level_Aktivtank_02 1;
BA_ "GenSigSendType" SG_ 1011 SCR_QBit_Level_Aktivtank_02 0;
BA_ "GenSigSwitchedByIgnition" SG_ 1011 SCR_Level_ReadAbove 0;
BA_ "GenSigSendType" SG_ 1011 SCR_Level_ReadAbove 0;
BA_ "Fehlerwert" SG_ 1011 SCR_Dosierpumpe_Drehzahl 2047;
BA_ "GenSigSwitchedByIgnition" SG_ 1011 SCR_Dosierpumpe_Drehzahl 0;
BA_ "GenSigStartValue" SG_ 1011 SCR_Dosierpumpe_Drehzahl 2046;
BA_ "GenSigSendType" SG_ 1011 SCR_Dosierpumpe_Drehzahl 0;
BA_ "Fehlerwert" SG_ 1011 SCR_Druck 1023;
BA_ "GenSigSwitchedByIgnition" SG_ 1011 SCR_Druck 0;
BA_ "GenSigStartValue" SG_ 1011 SCR_Druck 1022;
BA_ "GenSigSendType" SG_ 1011 SCR_Druck 0;
BA_ "Fehlerwert" SG_ 1011 SCR_Level_Aktivtank 1023;
BA_ "GenSigSwitchedByIgnition" SG_ 1011 SCR_Level_Aktivtank 0;
BA_ "GenSigStartValue" SG_ 1011 SCR_Level_Aktivtank 1022;
BA_ "GenSigSendType" SG_ 1011 SCR_Level_Aktivtank 0;
BA_ "Fehlerwert" SG_ 1011 SCR_Level_Passivtank 1023;
BA_ "GenSigSwitchedByIgnition" SG_ 1011 SCR_Level_Passivtank 0;
BA_ "GenSigStartValue" SG_ 1011 SCR_Level_Passivtank 1022;
BA_ "GenSigSendType" SG_ 1011 SCR_Level_Passivtank 0;
BA_ "Fehlerwert" SG_ 1507 SCR_Heizkreis_3_Strom 255;
BA_ "GenSigSwitchedByIgnition" SG_ 1507 SCR_Heizkreis_3_Strom 0;
BA_ "GenSigStartValue" SG_ 1507 SCR_Heizkreis_3_Strom 254;
BA_ "GenSigSendType" SG_ 1507 SCR_Heizkreis_3_Strom 0;
BA_ "GenSigSwitchedByIgnition" SG_ 1507 SCR_02_BZ 0;
BA_ "GenSigFuncType" SG_ 1507 SCR_02_BZ 1;
BA_ "GenSigSendType" SG_ 1507 SCR_02_BZ 0;
BA_ "GenSigSwitchedByIgnition" SG_ 1507 SCR_KD_Fehler 0;
BA_ "GenSigSendType" SG_ 1507 SCR_KD_Fehler 0;
BA_ "Fehlerwert" SG_ 1507 SCR_Guetesensor 1023;
BA_ "GenSigSwitchedByIgnition" SG_ 1507 SCR_Guetesensor 0;
BA_ "GenSigStartValue" SG_ 1507 SCR_Guetesensor 1022;
BA_ "GenSigSendType" SG_ 1507 SCR_Guetesensor 0;
BA_ "Fehlerwert" SG_ 1507 SCR_Temp_Aktivtank 255;
BA_ "GenSigSwitchedByIgnition" SG_ 1507 SCR_Temp_Aktivtank 0;
BA_ "GenSigStartValue" SG_ 1507 SCR_Temp_Aktivtank 254;
BA_ "GenSigSendType" SG_ 1507 SCR_Temp_Aktivtank 0;
BA_ "Fehlerwert" SG_ 1507 SCR_Temp_Passivtank 255;
BA_ "GenSigSwitchedByIgnition" SG_ 1507 SCR_Temp_Passivtank 0;
BA_ "GenSigStartValue" SG_ 1507 SCR_Temp_Passivtank 254;
BA_ "GenSigSendType" SG_ 1507 SCR_Temp_Passivtank 0;
BA_ "Fehlerwert" SG_ 1507 SCR_Leitungsheizung_Strom 255;
BA_ "GenSigSwitchedByIgnition" SG_ 1507 SCR_Leitungsheizung_Strom 0;
BA_ "GenSigStartValue" SG_ 1507 SCR_Leitungsheizung_Strom 254;
BA_ "GenSigSendType" SG_ 1507 SCR_Leitungsheizung_Strom 0;
BA_ "Fehlerwert" SG_ 1507 SCR_Transferpumpe_Strom 255;
BA_ "GenSigSwitchedByIgnition" SG_ 1507 SCR_Transferpumpe_Strom 0;
BA_ "GenSigStartValue" SG_ 1507 SCR_Transferpumpe_Strom 254;
BA_ "GenSigSendType" SG_ 1507 SCR_Transferpumpe_Strom 0;
BA_ "Fehlerwert" SG_ 1507 SCR_Tankheizung_Strom 255;
BA_ "GenSigSwitchedByIgnition" SG_ 1507 SCR_Tankheizung_Strom 0;
BA_ "GenSigStartValue" SG_ 1507 SCR_Tankheizung_Strom 254;
BA_ "GenSigSendType" SG_ 1507 SCR_Tankheizung_Strom 0;
BA_ "GenSigSwitchedByIgnition" SG_ 1508 SCR_03_BZ 0;
BA_ "GenSigFuncType" SG_ 1508 SCR_03_BZ 1;
BA_ "GenSigSendType" SG_ 1508 SCR_03_BZ 0;
BA_ "GenSigSwitchedByIgnition" SG_ 1508 SCR_Spannungsversorgung_Status 0;
BA_ "GenSigStartValue" SG_ 1508 SCR_Spannungsversorgung_Status 15;
BA_ "GenSigSendType" SG_ 1508 SCR_Spannungsversorgung_Status 3;
BA_ "GenSigSwitchedByIgnition" SG_ 1508 SCR_VersorgungSensoren_Status 0;
BA_ "GenSigStartValue" SG_ 1508 SCR_VersorgungSensoren_Status 15;
BA_ "GenSigSendType" SG_ 1508 SCR_VersorgungSensoren_Status 3;
BA_ "GenSigSwitchedByIgnition" SG_ 1508 SCR_Heizkreis_3_Status 0;
BA_ "GenSigStartValue" SG_ 1508 SCR_Heizkreis_3_Status 15;
BA_ "GenSigSendType" SG_ 1508 SCR_Heizkreis_3_Status 3;
BA_ "GenSigSwitchedByIgnition" SG_ 1508 SCR_Guetesensor_Status 0;
BA_ "GenSigStartValue" SG_ 1508 SCR_Guetesensor_Status 15;
BA_ "GenSigSendType" SG_ 1508 SCR_Guetesensor_Status 3;
BA_ "GenSigSwitchedByIgnition" SG_ 1508 SCR_Leitungsheizung_Status 0;
BA_ "GenSigStartValue" SG_ 1508 SCR_Leitungsheizung_Status 15;
BA_ "GenSigSendType" SG_ 1508 SCR_Leitungsheizung_Status 3;
BA_ "GenSigSwitchedByIgnition" SG_ 1508 SCR_Tankheizung_Status 0;
BA_ "GenSigStartValue" SG_ 1508 SCR_Tankheizung_Status 15;
BA_ "GenSigSendType" SG_ 1508 SCR_Tankheizung_Status 3;
BA_ "GenSigSwitchedByIgnition" SG_ 1508 SCR_Druck_Status 0;
BA_ "GenSigStartValue" SG_ 1508 SCR_Druck_Status 15;
BA_ "GenSigSendType" SG_ 1508 SCR_Druck_Status 3;
BA_ "GenSigSwitchedByIgnition" SG_ 1508 SCR_Dosierpumpe_Status_Spule 0;
BA_ "GenSigSendType" SG_ 1508 SCR_Dosierpumpe_Status_Spule 3;
BA_ "GenSigSwitchedByIgnition" SG_ 1508 SCR_Transferpumpe_Status 0;
BA_ "GenSigSendType" SG_ 1508 SCR_Transferpumpe_Status 3;
BA_ "GenSigSwitchedByIgnition" SG_ 1508 SCR_Level_Aktivtank_Status 0;
BA_ "GenSigStartValue" SG_ 1508 SCR_Level_Aktivtank_Status 15;
BA_ "GenSigSendType" SG_ 1508 SCR_Level_Aktivtank_Status 3;
BA_ "GenSigSwitchedByIgnition" SG_ 1508 SCR_Level_Passivtank_Status 0;
BA_ "GenSigStartValue" SG_ 1508 SCR_Level_Passivtank_Status 15;
BA_ "GenSigSendType" SG_ 1508 SCR_Level_Passivtank_Status 3;
BA_ "GenSigSwitchedByIgnition" SG_ 1508 SCR_Temp_Aktivtank_Status 0;
BA_ "GenSigStartValue" SG_ 1508 SCR_Temp_Aktivtank_Status 15;
BA_ "GenSigSendType" SG_ 1508 SCR_Temp_Aktivtank_Status 3;
BA_ "GenSigSwitchedByIgnition" SG_ 1508 SCR_Temp_Passivtank_Status 0;
BA_ "GenSigStartValue" SG_ 1508 SCR_Temp_Passivtank_Status 15;
BA_ "GenSigSendType" SG_ 1508 SCR_Temp_Passivtank_Status 3;
BA_ "GenSigSwitchedByIgnition" SG_ 1509 SCR_04_BZ 0;
BA_ "GenSigFuncType" SG_ 1509 SCR_04_BZ 1;
BA_ "GenSigSendType" SG_ 1509 SCR_04_BZ 0;
BA_ "GenSigSwitchedByIgnition" SG_ 1509 SCR_Ansteuerung_Transferpumpe 0;
BA_ "GenSigSendType" SG_ 1509 SCR_Ansteuerung_Transferpumpe 0;
BA_ "GenSigSwitchedByIgnition" SG_ 1509 SCR_Ansteuerung_Dosierpumpe 0;
BA_ "GenSigSendType" SG_ 1509 SCR_Ansteuerung_Dosierpumpe 0;
BA_ "GenSigSwitchedByIgnition" SG_ 1509 SCR_Ansteuerung_Heizkreis_3 0;
BA_ "GenSigSendType" SG_ 1509 SCR_Ansteuerung_Heizkreis_3 0;
BA_ "GenSigSwitchedByIgnition" SG_ 1509 SCR_Ansteuerung_Leitungsheizung 0;
BA_ "GenSigSendType" SG_ 1509 SCR_Ansteuerung_Leitungsheizung 0;
BA_ "GenSigSwitchedByIgnition" SG_ 1509 SCR_Ansteuerung_Tankheizung 0;
BA_ "GenSigSendType" SG_ 1509 SCR_Ansteuerung_Tankheizung 0;
BA_ "GenSigSwitchedByIgnition" SG_ 1509 SCR_CAL_CVN_CRC_32 0;
BA_ "GenSigSendType" SG_ 1509 SCR_CAL_CVN_CRC_32 0;
BA_ "GenSigSwitchedByIgnition" SG_ 1526 SCR_05_BZ 0;
BA_ "GenSigFuncType" SG_ 1526 SCR_05_BZ 1;
BA_ "GenSigSendType" SG_ 1526 SCR_05_BZ 0;
BA_ "GenSigSwitchedByIgnition" SG_ 1526 SCR_Level_Aktivtank_OOR4Quality 0;
BA_ "GenSigSendType" SG_ 1526 SCR_Level_Aktivtank_OOR4Quality 0;
BA_ "GenSigSwitchedByIgnition" SG_ 1526 SCR_Level_Aktivtank_OOR_minus 0;
BA_ "GenSigSendType" SG_ 1526 SCR_Level_Aktivtank_OOR_minus 0;
BA_ "GenSigSwitchedByIgnition" SG_ 1526 SCR_Sent_1_Signalstatus 0;
BA_ "GenSigStartValue" SG_ 1526 SCR_Sent_1_Signalstatus 3;
BA_ "GenSigSendType" SG_ 1526 SCR_Sent_1_Signalstatus 0;
BA_ "GenSigSwitchedByIgnition" SG_ 1526 SCR_Sent_1_elektrischer_Status 0;
BA_ "GenSigStartValue" SG_ 1526 SCR_Sent_1_elektrischer_Status 15;
BA_ "GenSigSendType" SG_ 1526 SCR_Sent_1_elektrischer_Status 0;
BA_ "GenSigSwitchedByIgnition" SG_ 1526 SCR_Sent_Levelsensor 0;
BA_ "GenSigStartValue" SG_ 1526 SCR_Sent_Levelsensor 7;
BA_ "GenSigSendType" SG_ 1526 SCR_Sent_Levelsensor 0;
BA_ "GenSigSwitchedByIgnition" SG_ 1526 SCR_Sent_Qualitaetssensor 0;
BA_ "GenSigStartValue" SG_ 1526 SCR_Sent_Qualitaetssensor 7;
BA_ "GenSigSendType" SG_ 1526 SCR_Sent_Qualitaetssensor 0;
BA_ "GenSigSwitchedByIgnition" SG_ 1526 SCR_Sent_Temperatursensor 0;
BA_ "GenSigStartValue" SG_ 1526 SCR_Sent_Temperatursensor 7;
BA_ "GenSigSendType" SG_ 1526 SCR_Sent_Temperatursensor 0;
BA_ "GenSigSwitchedByIgnition" SG_ 1526 SCR_DEF_Qualitaet_Medium 0;
BA_ "GenSigSendType" SG_ 1526 SCR_DEF_Qualitaet_Medium 0;
BA_ "GenSigSwitchedByIgnition" SG_ 1526 SCR_QBit_Qualitaet 0;
BA_ "GenSigStartValue" SG_ 1526 SCR_QBit_Qualitaet 1;
BA_ "GenSigSendType" SG_ 1526 SCR_QBit_Qualitaet 0;
BA_ "GenSigSwitchedByIgnition" SG_ 1526 SCR_Qualitaet 0;
BA_ "GenSigStartValue" SG_ 1526 SCR_Qualitaet 254;
BA_ "GenSigSendType" SG_ 1526 SCR_Qualitaet 0;
BA_ "GenSigSwitchedByIgnition" SG_ 1526 SCR_Steuergeraet_Heizung_Status 0;
BA_ "GenSigStartValue" SG_ 1526 SCR_Steuergeraet_Heizung_Status 3;
BA_ "GenSigSendType" SG_ 1526 SCR_Steuergeraet_Heizung_Status 3;
BA_ "GenSigSwitchedByIgnition" SG_ 1526 SCR_Steuergeraet_Pumpe_Status 0;
BA_ "GenSigStartValue" SG_ 1526 SCR_Steuergeraet_Pumpe_Status 3;
BA_ "GenSigSendType" SG_ 1526 SCR_Steuergeraet_Pumpe_Status 3;
BA_ "GenSigSwitchedByIgnition" SG_ 1526 SCR_Steuergeraet_Relais_Status 0;
BA_ "GenSigStartValue" SG_ 1526 SCR_Steuergeraet_Relais_Status 3;
BA_ "GenSigSendType" SG_ 1526 SCR_Steuergeraet_Relais_Status 3;
BA_ "GenSigSwitchedByIgnition" SG_ 1526 SCR_Steuergeraet_Bus_Status 0;
BA_ "GenSigStartValue" SG_ 1526 SCR_Steuergeraet_Bus_Status 3;
BA_ "GenSigSendType" SG_ 1526 SCR_Steuergeraet_Bus_Status 3;
BA_ "GenSigSwitchedByIgnition" SG_ 1526 SCR_Steuergeraet_Datensatz_St002 0;
BA_ "GenSigStartValue" SG_ 1526 SCR_Steuergeraet_Datensatz_St002 3;
BA_ "GenSigSendType" SG_ 1526 SCR_Steuergeraet_Datensatz_St002 3;
BA_ "GenSigSwitchedByIgnition" SG_ 1526 SCR_Steuergeraet_Defekt_Status 0;
BA_ "GenSigStartValue" SG_ 1526 SCR_Steuergeraet_Defekt_Status 3;
BA_ "GenSigSendType" SG_ 1526 SCR_Steuergeraet_Defekt_Status 3;
BA_ "GenSigSwitchedByIgnition" SG_ 1510 SCR_CAL_ID_Index_01 0;
BA_ "GenSigStartValue" SG_ 1510 SCR_CAL_ID_Index_01 83;
BA_ "GenSigSendType" SG_ 1510 SCR_CAL_ID_Index_01 0;
BA_ "GenSigSwitchedByIgnition" SG_ 1510 SCR_CAL_ID_Index_02 0;
BA_ "GenSigStartValue" SG_ 1510 SCR_CAL_ID_Index_02 67;
BA_ "GenSigSendType" SG_ 1510 SCR_CAL_ID_Index_02 0;
BA_ "GenSigSwitchedByIgnition" SG_ 1510 SCR_CAL_ID_Index_03 0;
BA_ "GenSigStartValue" SG_ 1510 SCR_CAL_ID_Index_03 82;
BA_ "GenSigSendType" SG_ 1510 SCR_CAL_ID_Index_03 0;
BA_ "GenSigSwitchedByIgnition" SG_ 1510 SCR_CAL_ID_Index_04 0;
BA_ "GenSigStartValue" SG_ 1510 SCR_CAL_ID_Index_04 48;
BA_ "GenSigSendType" SG_ 1510 SCR_CAL_ID_Index_04 0;
BA_ "GenSigSwitchedByIgnition" SG_ 1510 SCR_CAL_ID_Index_05 0;
BA_ "GenSigStartValue" SG_ 1510 SCR_CAL_ID_Index_05 48;
BA_ "GenSigSendType" SG_ 1510 SCR_CAL_ID_Index_05 0;
BA_ "GenSigSwitchedByIgnition" SG_ 1510 SCR_CAL_ID_Index_06 0;
BA_ "GenSigStartValue" SG_ 1510 SCR_CAL_ID_Index_06 48;
BA_ "GenSigSendType" SG_ 1510 SCR_CAL_ID_Index_06 0;
BA_ "GenSigSwitchedByIgnition" SG_ 1510 SCR_CAL_ID_Index_07 0;
BA_ "GenSigStartValue" SG_ 1510 SCR_CAL_ID_Index_07 48;
BA_ "GenSigSendType" SG_ 1510 SCR_CAL_ID_Index_07 0;
BA_ "GenSigSwitchedByIgnition" SG_ 1510 SCR_CAL_ID_Index_08 0;
BA_ "GenSigStartValue" SG_ 1510 SCR_CAL_ID_Index_08 48;
BA_ "GenSigSendType" SG_ 1510 SCR_CAL_ID_Index_08 0;
BA_ "GenSigSwitchedByIgnition" SG_ 1512 SCR_CAL_ID_Index_09 0;
BA_ "GenSigStartValue" SG_ 1512 SCR_CAL_ID_Index_09 48;
BA_ "GenSigSendType" SG_ 1512 SCR_CAL_ID_Index_09 0;
BA_ "GenSigSwitchedByIgnition" SG_ 1512 SCR_CAL_ID_Index_10 0;
BA_ "GenSigStartValue" SG_ 1512 SCR_CAL_ID_Index_10 48;
BA_ "GenSigSendType" SG_ 1512 SCR_CAL_ID_Index_10 0;
BA_ "GenSigSwitchedByIgnition" SG_ 1512 SCR_CAL_ID_Index_11 0;
BA_ "GenSigStartValue" SG_ 1512 SCR_CAL_ID_Index_11 48;
BA_ "GenSigSendType" SG_ 1512 SCR_CAL_ID_Index_11 0;
BA_ "GenSigSwitchedByIgnition" SG_ 1512 SCR_CAL_ID_Index_12 0;
BA_ "GenSigStartValue" SG_ 1512 SCR_CAL_ID_Index_12 48;
BA_ "GenSigSendType" SG_ 1512 SCR_CAL_ID_Index_12 0;
BA_ "GenSigSwitchedByIgnition" SG_ 1512 SCR_CAL_ID_Index_13 0;
BA_ "GenSigStartValue" SG_ 1512 SCR_CAL_ID_Index_13 48;
BA_ "GenSigSendType" SG_ 1512 SCR_CAL_ID_Index_13 0;
BA_ "GenSigSwitchedByIgnition" SG_ 1512 SCR_CAL_ID_Index_14 0;
BA_ "GenSigStartValue" SG_ 1512 SCR_CAL_ID_Index_14 48;
BA_ "GenSigSendType" SG_ 1512 SCR_CAL_ID_Index_14 0;
BA_ "GenSigSwitchedByIgnition" SG_ 1512 SCR_CAL_ID_Index_15 0;
BA_ "GenSigStartValue" SG_ 1512 SCR_CAL_ID_Index_15 48;
BA_ "GenSigSendType" SG_ 1512 SCR_CAL_ID_Index_15 0;
BA_ "GenSigSwitchedByIgnition" SG_ 1512 SCR_CAL_ID_Index_16 0;
BA_ "GenSigStartValue" SG_ 1512 SCR_CAL_ID_Index_16 48;
BA_ "GenSigSendType" SG_ 1512 SCR_CAL_ID_Index_16 0;
BA_ "GenSigFuncType" SG_ 133 SCU_01_CHK 3;
BA_ "GenSigSendType" SG_ 133 SCU_01_CHK 0;
BA_ "GenSigFuncType" SG_ 133 SCU_01_BZ 1;
BA_ "GenSigSendType" SG_ 133 SCU_01_BZ 0;
BA_ "Fehlerwert" SG_ 133 SCU_Ue_Winkel_ADS 4095;
BA_ "GenSigStartValue" SG_ 133 SCU_Ue_Winkel_ADS 4094;
BA_ "GenSigSendType" SG_ 133 SCU_Ue_Winkel_ADS 0;
BA_ "GenSigSendType" SG_ 133 SCU_VZ_Ue_Winkel_ADS 0;
BA_ "Fehlerwert" SG_ 133 SCU_Soll_Ue_Winkel 2047;
BA_ "GenSigStartValue" SG_ 133 SCU_Soll_Ue_Winkel 2046;
BA_ "GenSigSendType" SG_ 133 SCU_Soll_Ue_Winkel 0;
BA_ "Fehlerwert" SG_ 133 SCU_max_Gradient 511;
BA_ "GenSigSendType" SG_ 133 SCU_max_Gradient 0;
BA_ "GenSigSendType" SG_ 133 SCU_VZ_Soll_Ue_Winkel 0;
BA_ "GenSigStartValue" SG_ 133 SCU_Status 1;
BA_ "GenSigSendType" SG_ 133 SCU_Status 0;
BA_ "GenSigSendType" SG_ 133 SCU_KD_Fehler 0;
BA_ "GenSigSendType" SG_ 133 SCU_Sensorstatus 0;
BA_ "GenSigFuncType" SG_ 133 SCU_01_CRC 2;
BA_ "GenSigSendType" SG_ 133 SCU_01_CRC 0;
BA_ "GenSigSendType" SG_ 784 SCU_Warnlampe 0;
BA_ "GenSigSendType" SG_ 784 SCU_Warnungen 0;
BA_ "GenSigSendType" SG_ 784 SCU_Charisma_FahrPr 0;
BA_ "GenSigSendType" SG_ 784 SCU_Charisma_Status 0;
BA_ "GenSigSendType" SG_ 784 SCU_Charisma_Umschaltung 0;
BA_ "GenSigSwitchedByIgnition" SG_ 2549875324 SK2_Key_Req_Data 0;
BA_ "GenSigSendType" SG_ 2549875324 SK2_Key_Req_Data 3;
BA_ "GenSigSwitchedByIgnition" SG_ 2550006396 SK2_Key_Resp_Data 0;
BA_ "GenSigSendType" SG_ 2550006396 SK2_Key_Resp_Data 3;
BA_ "GenSigSwitchedByIgnition" SG_ 2549875319 SK2_Key_Req_Data 0;
BA_ "GenSigSendType" SG_ 2549875319 SK2_Key_Req_Data 3;
BA_ "GenSigSwitchedByIgnition" SG_ 2550006391 SK2_Key_Resp_Data 0;
BA_ "GenSigSendType" SG_ 2550006391 SK2_Key_Resp_Data 3;
BA_ "GenSigSwitchedByIgnition" SG_ 2549875323 SK2_Key_Req_Data 0;
BA_ "GenSigSendType" SG_ 2549875323 SK2_Key_Req_Data 3;
BA_ "GenSigSwitchedByIgnition" SG_ 2550006395 SK2_Key_Resp_Data 0;
BA_ "GenSigSendType" SG_ 2550006395 SK2_Key_Resp_Data 3;
BA_ "GenSigSwitchedByIgnition" SG_ 2549875318 SK2_Key_Req_Data 0;
BA_ "GenSigSendType" SG_ 2549875318 SK2_Key_Req_Data 3;
BA_ "GenSigSwitchedByIgnition" SG_ 2550006390 SK2_Key_Resp_Data 0;
BA_ "GenSigSendType" SG_ 2550006390 SK2_Key_Resp_Data 3;
BA_ "GenSigSwitchedByIgnition" SG_ 2549875320 SK2_Key_Req_Data 0;
BA_ "GenSigSendType" SG_ 2549875320 SK2_Key_Req_Data 3;
BA_ "GenSigSwitchedByIgnition" SG_ 2550006392 SK2_Key_Resp_Data 0;
BA_ "GenSigSendType" SG_ 2550006392 SK2_Key_Resp_Data 3;
BA_ "GenSigSwitchedByIgnition" SG_ 1313 STH_Funk_ein 0;
BA_ "GenSigSendType" SG_ 1313 STH_Funk_ein 0;
BA_ "GenSigSwitchedByIgnition" SG_ 1313 STH_Funk_aus 0;
BA_ "GenSigSendType" SG_ 1313 STH_Funk_aus 0;
BA_ "GenSigSwitchedByIgnition" SG_ 1313 STH_Zusatzheizung 0;
BA_ "GenSigSendType" SG_ 1313 STH_Zusatzheizung 0;
BA_ "GenSigSwitchedByIgnition" SG_ 1313 STH_LED 0;
BA_ "GenSigSendType" SG_ 1313 STH_LED 0;
BA_ "GenSigSwitchedByIgnition" SG_ 1313 STH_Pumpe_ein 0;
BA_ "GenSigSendType" SG_ 1313 STH_Pumpe_ein 0;
BA_ "GenSigSwitchedByIgnition" SG_ 1313 STH_Geblaese 0;
BA_ "GenSigSendType" SG_ 1313 STH_Geblaese 0;
BA_ "GenSigSwitchedByIgnition" SG_ 1313 STH_EKP_Anst 0;
BA_ "GenSigSendType" SG_ 1313 STH_EKP_Anst 0;
BA_ "GenSigSwitchedByIgnition" SG_ 1313 STH_Start_folgt 0;
BA_ "GenSigSendType" SG_ 1313 STH_Start_folgt 0;
BA_ "GenSigSwitchedByIgnition" SG_ 1313 STH_Ventiloeffnungszeit 0;
BA_ "GenSigSendType" SG_ 1313 STH_Ventiloeffnungszeit 0;
BA_ "GenSigSwitchedByIgnition" SG_ 1313 STH_Ventil_Status 0;
BA_ "GenSigSendType" SG_ 1313 STH_Ventil_Status 0;
BA_ "GenSigSwitchedByIgnition" SG_ 1313 STH_Fehler_ElWaPu 0;
BA_ "GenSigSendType" SG_ 1313 STH_Fehler_ElWaPu 0;
BA_ "GenSigSwitchedByIgnition" SG_ 1313 STH_Waermeeintrag 0;
BA_ "GenSigSendType" SG_ 1313 STH_Waermeeintrag 0;
BA_ "GenSigSwitchedByIgnition" SG_ 1313 STH_Pumpen_Anf_extern 0;
BA_ "GenSigSendType" SG_ 1313 STH_Pumpen_Anf_extern 0;
BA_ "GenSigSwitchedByIgnition" SG_ 1313 STH_KVS 0;
BA_ "GenSigSendType" SG_ 1313 STH_KVS 0;
BA_ "GenSigSwitchedByIgnition" SG_ 1313 STH_Fehlerstatus 0;
BA_ "GenSigSendType" SG_ 1313 STH_Fehlerstatus 0;
BA_ "GenSigSwitchedByIgnition" SG_ 1313 STH_Heizleistung 0;
BA_ "GenSigSendType" SG_ 1313 STH_Heizleistung 0;
BA_ "Fehlerwert" SG_ 1313 STH_Wassertemp 255;
BA_ "GenSigSwitchedByIgnition" SG_ 1313 STH_Wassertemp 0;
BA_ "GenSigStartValue" SG_ 1313 STH_Wassertemp 254;
BA_ "GenSigSendType" SG_ 1313 STH_Wassertemp 0;
BA_ "GenSigSwitchedByIgnition" SG_ 1313 STH_Texte 0;
BA_ "GenSigSendType" SG_ 1313 STH_Texte 0;
BA_ "GenSigSwitchedByIgnition" SG_ 1313 STH_Motorvorwaermung 0;
BA_ "GenSigSendType" SG_ 1313 STH_Motorvorwaermung 0;
BA_ "GenSigSwitchedByIgnition" SG_ 1313 STH_Servicemode 0;
BA_ "GenSigSendType" SG_ 1313 STH_Servicemode 0;
BA_ "GenSigSwitchedByIgnition" SG_ 1313 STH_war_aktiv 0;
BA_ "GenSigSendType" SG_ 1313 STH_war_aktiv 0;
BA_ "GenSigSwitchedByIgnition" SG_ 1313 STH_KVS_Ueberlauf 0;
BA_ "GenSigSendType" SG_ 1313 STH_KVS_Ueberlauf 0;
BA_ "GenSigSwitchedByIgnition" SG_ 1313 STH_KD_Fehler 0;
BA_ "GenSigSendType" SG_ 1313 STH_KD_Fehler 0;
BA_ "GenSigSwitchedByIgnition" SG_ 1172 STS_01_CHK 0;
BA_ "GenSigFuncType" SG_ 1172 STS_01_CHK 3;
BA_ "GenSigSendType" SG_ 1172 STS_01_CHK 0;
BA_ "GenSigSwitchedByIgnition" SG_ 1172 STS_01_BZ 0;
BA_ "GenSigFuncType" SG_ 1172 STS_01_BZ 1;
BA_ "GenSigSendType" SG_ 1172 STS_01_BZ 0;
BA_ "GenSigSwitchedByIgnition" SG_ 1172 STS_Car_not_under_theft 0;
BA_ "GenSigStartValue" SG_ 1172 STS_Car_not_under_theft 1;
BA_ "GenSigSendType" SG_ 1172 STS_Car_not_under_theft 0;
BA_ "GenSigSwitchedByIgnition" SG_ 1172 STS_Car_under_theft 0;
BA_ "GenSigSendType" SG_ 1172 STS_Car_under_theft 0;
BA_ "GenSigSwitchedByIgnition" SG_ 1172 STS_Anlassersperre 0;
BA_ "GenSigSendType" SG_ 1172 STS_Anlassersperre 0;
BA_ "GenSigSwitchedByIgnition" SG_ 1172 STS_Typencodierung 0;
BA_ "GenSigSendType" SG_ 1172 STS_Typencodierung 0;
BA_ "GenSigSwitchedByIgnition" SG_ 1172 STS_KD_Fehler 0;
BA_ "GenSigSendType" SG_ 1172 STS_KD_Fehler 0;
BA_ "GenSigSwitchedByIgnition" SG_ 1172 STS_LIN_aktiv 0;
BA_ "GenSigSendType" SG_ 1172 STS_LIN_aktiv 0;
BA_ "GenSigSwitchedByIgnition" SG_ 1172 STS_Standlicht 0;
BA_ "GenSigSendType" SG_ 1172 STS_Standlicht 3;
BA_ "GenSigSwitchedByIgnition" SG_ 1172 STS_Fahrlicht 0;
BA_ "GenSigSendType" SG_ 1172 STS_Fahrlicht 3;
BA_ "GenSigSwitchedByIgnition" SG_ 1172 STS_Alarm_still 0;
BA_ "GenSigSendType" SG_ 1172 STS_Alarm_still 0;
BA_ "Fehlerwert" SG_ 1172 STS_Texte 15;
BA_ "GenSigSwitchedByIgnition" SG_ 1172 STS_Texte 0;
BA_ "GenSigStartValue" SG_ 1172 STS_Texte 14;
BA_ "GenSigSendType" SG_ 1172 STS_Texte 0;
BA_ "GenSigSwitchedByIgnition" SG_ 1172 STS_Laderelais 0;
BA_ "GenSigSendType" SG_ 1172 STS_Laderelais 3;
BA_ "GenSigSwitchedByIgnition" SG_ 1172 STS_Summer 0;
BA_ "GenSigSendType" SG_ 1172 STS_Summer 3;
BA_ "GenSigSwitchedByIgnition" SG_ 1172 STS_Alarm_Blinker 0;
BA_ "GenSigSendType" SG_ 1172 STS_Alarm_Blinker 3;
BA_ "GenSigSwitchedByIgnition" SG_ 1172 STS_Notstart 0;
BA_ "GenSigSendType" SG_ 1172 STS_Notstart 3;
BA_ "GenSigSwitchedByIgnition" SG_ 1172 STS_Signalhorn 0;
BA_ "GenSigSendType" SG_ 1172 STS_Signalhorn 3;
BA_ "GenSigSwitchedByIgnition" SG_ 1172 STS_Leerlaufschaltung 0;
BA_ "GenSigSendType" SG_ 1172 STS_Leerlaufschaltung 0;
BA_ "GenSigSwitchedByIgnition" SG_ 1413 SI_Int_CAN_gespiegelt 0;
BA_ "GenSigSendType" SG_ 1413 SI_Int_CAN_gespiegelt 3;
BA_ "GenSigSwitchedByIgnition" SG_ 1413 SI_CAN_Komfort_Sleep 0;
BA_ "GenSigStartValue" SG_ 1413 SI_CAN_Komfort_Sleep 1;
BA_ "GenSigSendType" SG_ 1413 SI_CAN_Komfort_Sleep 3;
BA_ "GenSigSwitchedByIgnition" SG_ 1413 SI_CAN_Dashboard_Sleep 0;
BA_ "GenSigStartValue" SG_ 1413 SI_CAN_Dashboard_Sleep 1;
BA_ "GenSigSendType" SG_ 1413 SI_CAN_Dashboard_Sleep 3;
BA_ "GenSigSwitchedByIgnition" SG_ 1413 SI_CAN_Antrieb_Sleep 0;
BA_ "GenSigStartValue" SG_ 1413 SI_CAN_Antrieb_Sleep 1;
BA_ "GenSigSendType" SG_ 1413 SI_CAN_Antrieb_Sleep 3;
BA_ "GenSigSwitchedByIgnition" SG_ 1413 SI_Infotainment_Sleep 0;
BA_ "GenSigStartValue" SG_ 1413 SI_Infotainment_Sleep 1;
BA_ "GenSigSendType" SG_ 1413 SI_Infotainment_Sleep 3;
BA_ "GenSigSwitchedByIgnition" SG_ 1413 SI_CAN_Extended_Sleep 0;
BA_ "GenSigStartValue" SG_ 1413 SI_CAN_Extended_Sleep 1;
BA_ "GenSigSendType" SG_ 1413 SI_CAN_Extended_Sleep 3;
BA_ "GenSigSwitchedByIgnition" SG_ 1413 SI_Fahrwerk_Sleep 0;
BA_ "GenSigStartValue" SG_ 1413 SI_Fahrwerk_Sleep 1;
BA_ "GenSigSendType" SG_ 1413 SI_Fahrwerk_Sleep 3;
BA_ "GenSigSwitchedByIgnition" SG_ 1413 SI_Diagnose_Aktiv 0;
BA_ "GenSigSendType" SG_ 1413 SI_Diagnose_Aktiv 3;
BA_ "GenSigSwitchedByIgnition" SG_ 1413 SI_QRS_Mode 0;
BA_ "GenSigSendType" SG_ 1413 SI_QRS_Mode 3;
BA_ "GenSigSwitchedByIgnition" SG_ 1413 SI_T_Mode 0;
BA_ "GenSigSendType" SG_ 1413 SI_T_Mode 3;
BA_ "GenSigSwitchedByIgnition" SG_ 1413 SI_NWDF 0;
BA_ "GenSigSendType" SG_ 1413 SI_NWDF 3;
BA_ "GenSigSwitchedByIgnition" SG_ 1413 SI_NWDF_gueltig 0;
BA_ "GenSigFuncType" SG_ 1413 SI_NWDF_gueltig 8;
BA_ "GenSigSendType" SG_ 1413 SI_NWDF_gueltig 3;
BA_ "GenSigSwitchedByIgnition" SG_ 1413 SI_Sammelfehler 0;
BA_ "GenSigSendType" SG_ 1413 SI_Sammelfehler 3;
BA_ "GenSigSendType" SG_ 1413 GW_KD_Fehler 3;
BA_ "GenSigSwitchedByIgnition" SG_ 1413 SI_T_Schutz 0;
BA_ "GenSigSendType" SG_ 1413 SI_T_Schutz 3;
BA_ "GenSigSwitchedByIgnition" SG_ 1413 SI_MOST_Status 0;
BA_ "GenSigSendType" SG_ 1413 SI_MOST_Status 3;
BA_ "GenSigSwitchedByIgnition" SG_ 1413 SI_Sammel_SG_Fehler 0;
BA_ "GenSigStartValue" SG_ 1413 SI_Sammel_SG_Fehler 63;
BA_ "GenSigSendType" SG_ 1413 SI_Sammel_SG_Fehler 0;
BA_ "GenSigSwitchedByIgnition" SG_ 1413 SI_CAN_Hybrid_Sleep 0;
BA_ "GenSigStartValue" SG_ 1413 SI_CAN_Hybrid_Sleep 1;
BA_ "GenSigSendType" SG_ 1413 SI_CAN_Hybrid_Sleep 3;
BA_ "GenSigSwitchedByIgnition" SG_ 1413 SI_MO_WU 0;
BA_ "GenSigSendType" SG_ 1413 SI_MO_WU 3;
BA_ "GenSigSwitchedByIgnition" SG_ 1196 TPD_Daempfer_Data_1 0;
BA_ "GenSigSendType" SG_ 1196 TPD_Daempfer_Data_1 3;
BA_ "GenSigSwitchedByIgnition" SG_ 1214 TPD_SCU_Data_1 0;
BA_ "GenSigSendType" SG_ 1214 TPD_SCU_Data_1 3;
BA_ "GenSigSwitchedByIgnition" SG_ 768 TPD_Tester_Data_1 0;
BA_ "GenSigSendType" SG_ 768 TPD_Tester_Data_1 3;
BA_ "GenSigSwitchedByIgnition" SG_ 769 TPD_Tester_Data_2 0;
BA_ "GenSigSendType" SG_ 769 TPD_Tester_Data_2 3;
BA_ "GenSigSwitchedByIgnition" SG_ 770 TPD_Tester_Data_3 0;
BA_ "GenSigSendType" SG_ 770 TPD_Tester_Data_3 3;
BA_ "GenSigSwitchedByIgnition" SG_ 771 TPD_Tester_Data_4 0;
BA_ "GenSigSendType" SG_ 771 TPD_Tester_Data_4 3;
BA_ "GenSigSwitchedByIgnition" SG_ 772 TPD_Tester_Data_5 0;
BA_ "GenSigSendType" SG_ 772 TPD_Tester_Data_5 3;
BA_ "GenSigSwitchedByIgnition" SG_ 773 TPD_Tester_Data_6 0;
BA_ "GenSigSendType" SG_ 773 TPD_Tester_Data_6 3;
BA_ "GenSigSwitchedByIgnition" SG_ 774 TPD_Tester_Data_7 0;
BA_ "GenSigSendType" SG_ 774 TPD_Tester_Data_7 3;
BA_ "GenSigSwitchedByIgnition" SG_ 775 TPD_Tester_Data_8 0;
BA_ "GenSigSendType" SG_ 775 TPD_Tester_Data_8 3;
BA_ "GenSigSwitchedByIgnition" SG_ 524 TPS_Daempfer_Data 0;
BA_ "GenSigSendType" SG_ 524 TPS_Daempfer_Data 3;
BA_ "GenSigSwitchedByIgnition" SG_ 542 TPS_SCU_Data 0;
BA_ "GenSigSendType" SG_ 542 TPS_SCU_Data 3;
BA_ "GenSigSwitchedByIgnition" SG_ 512 TPS_Tester_Data 0;
BA_ "GenSigSendType" SG_ 512 TPS_Tester_Data 3;
BA_ "GenSigSwitchedByIgnition" SG_ 786 TSK_03_CHK 0;
BA_ "GenSigFuncType" SG_ 786 TSK_03_CHK 3;
BA_ "GenSigSendType" SG_ 786 TSK_03_CHK 0;
BA_ "GenSigSwitchedByIgnition" SG_ 786 TSK_03_BZ 0;
BA_ "GenSigFuncType" SG_ 786 TSK_03_BZ 1;
BA_ "GenSigSendType" SG_ 786 TSK_03_BZ 0;
BA_ "GenSigSwitchedByIgnition" SG_ 786 FAS_Wunschgeschw 0;
BA_ "GenSigSendType" SG_ 786 FAS_Wunschgeschw 3;
BA_ "GenSigSwitchedByIgnition" SG_ 786 FAS_Status_Prim_Anz 0;
BA_ "GenSigSendType" SG_ 786 FAS_Status_Prim_Anz 3;
BA_ "GenSigSwitchedByIgnition" SG_ 786 FAS_Texte_Primaeranz 0;
BA_ "GenSigSendType" SG_ 786 FAS_Texte_Primaeranz 3;
BA_ "GenSigSwitchedByIgnition" SG_ 786 FAS_Status_Anzeige 0;
BA_ "GenSigSendType" SG_ 786 FAS_Status_Anzeige 3;
BA_ "GenSigSwitchedByIgnition" SG_ 270 TSK_04_CHK 0;
BA_ "GenSigFuncType" SG_ 270 TSK_04_CHK 3;
BA_ "GenSigSendType" SG_ 270 TSK_04_CHK 0;
BA_ "GenSigSwitchedByIgnition" SG_ 270 TSK_04_BZ 0;
BA_ "GenSigFuncType" SG_ 270 TSK_04_BZ 1;
BA_ "GenSigSendType" SG_ 270 TSK_04_BZ 0;
BA_ "GenSigSwitchedByIgnition" SG_ 270 TSK_zul_Regelabw 0;
BA_ "GenSigSendType" SG_ 270 TSK_zul_Regelabw 0;
BA_ "GenSigSwitchedByIgnition" SG_ 270 TSK_ax_Getriebe 0;
BA_ "GenSigStartValue" SG_ 270 TSK_ax_Getriebe 84;
BA_ "GenSigSendType" SG_ 270 TSK_ax_Getriebe 0;
BA_ "GenSigSwitchedByIgnition" SG_ 270 TSK_Wunsch_Uebersetz 0;
BA_ "GenSigSendType" SG_ 270 TSK_Wunsch_Uebersetz 0;
BA_ "GenSigSwitchedByIgnition" SG_ 270 TSK_Freig_WU 0;
BA_ "GenSigSendType" SG_ 270 TSK_Freig_WU 0;
BA_ "GenSigSwitchedByIgnition" SG_ 270 TSK_Limiter_aktiv 0;
BA_ "GenSigSendType" SG_ 270 TSK_Limiter_aktiv 0;
BA_ "GenSigSwitchedByIgnition" SG_ 270 TSK_Status_GRA_ACC_02 0;
BA_ "GenSigSendType" SG_ 270 TSK_Status_GRA_ACC_02 0;
BA_ "GenSigSwitchedByIgnition" SG_ 273 TSK_05_CHK 0;
BA_ "GenSigFuncType" SG_ 273 TSK_05_CHK 3;
BA_ "GenSigSendType" SG_ 273 TSK_05_CHK 0;
BA_ "GenSigSwitchedByIgnition" SG_ 273 TSK_05_BZ 0;
BA_ "GenSigFuncType" SG_ 273 TSK_05_BZ 1;
BA_ "GenSigSendType" SG_ 273 TSK_05_BZ 0;
BA_ "GenSigSwitchedByIgnition" SG_ 273 TSK_QBit_Steigung 0;
BA_ "GenSigStartValue" SG_ 273 TSK_QBit_Steigung 1;
BA_ "GenSigSendType" SG_ 273 TSK_QBit_Steigung 0;
BA_ "GenSigSwitchedByIgnition" SG_ 273 TSK_Status_GRA_ACC_01 0;
BA_ "GenSigSendType" SG_ 273 TSK_Status_GRA_ACC_01 0;
BA_ "Fehlerwert" SG_ 273 TSK_Fahrzeugmasse 31;
BA_ "GenSigSwitchedByIgnition" SG_ 273 TSK_Fahrzeugmasse 0;
BA_ "GenSigSendType" SG_ 273 TSK_Fahrzeugmasse 0;
BA_ "GenSigSwitchedByIgnition" SG_ 273 TSK_QBit_Fahrzeugmasse 0;
BA_ "GenSigStartValue" SG_ 273 TSK_QBit_Fahrzeugmasse 1;
BA_ "GenSigSendType" SG_ 273 TSK_QBit_Fahrzeugmasse 0;
BA_ "Fehlerwert" SG_ 273 TSK_Fahrzeugmasse_02 255;
BA_ "GenSigSwitchedByIgnition" SG_ 273 TSK_Fahrzeugmasse_02 0;
BA_ "GenSigSendType" SG_ 273 TSK_Fahrzeugmasse_02 0;
BA_ "Fehlerwert" SG_ 273 TSK_Steigung 255;
BA_ "GenSigSwitchedByIgnition" SG_ 273 TSK_Steigung 0;
BA_ "GenSigSendType" SG_ 273 TSK_Steigung 0;
BA_ "GenSigSwitchedByIgnition" SG_ 273 TSK_Getriebeinfo 0;
BA_ "GenSigSendType" SG_ 273 TSK_Getriebeinfo 0;
BA_ "GenSigSwitchedByIgnition" SG_ 273 TSK_Codierung_ACC 0;
BA_ "GenSigSendType" SG_ 273 TSK_Codierung_ACC 0;
BA_ "GenSigSwitchedByIgnition" SG_ 273 TSK_Zwangszusch_ESP 0;
BA_ "GenSigSendType" SG_ 273 TSK_Zwangszusch_ESP 0;
BA_ "GenSigSwitchedByIgnition" SG_ 273 TSK_Freig_Verzoeg_Anf 0;
BA_ "GenSigSendType" SG_ 273 TSK_Freig_Verzoeg_Anf 0;
BA_ "GenSigSwitchedByIgnition" SG_ 273 TSK_Verzoeg_Anf_02 0;
BA_ "GenSigStartValue" SG_ 273 TSK_Verzoeg_Anf_02 166;
BA_ "GenSigSendType" SG_ 273 TSK_Verzoeg_Anf_02 0;
BA_ "GenSigSwitchedByIgnition" SG_ 1716 VIN_01_MUX 0;
BA_ "GenSigSendType" SG_ 1716 VIN_01_MUX 0;
BA_ "GenSigSwitchedByIgnition" SG_ 1716 KS_Geheimnis_1 0;
BA_ "GenSigSwitchedByIgnition" SG_ 1716 VIN_4 0;
BA_ "GenSigStartValue" SG_ 1716 VIN_4 45;
BA_ "GenSigSwitchedByIgnition" SG_ 1716 VIN_11 0;
BA_ "GenSigStartValue" SG_ 1716 VIN_11 45;
BA_ "GenSigSwitchedByIgnition" SG_ 1716 KS_Geheimnis_2 0;
BA_ "GenSigSwitchedByIgnition" SG_ 1716 VIN_5 0;
BA_ "GenSigStartValue" SG_ 1716 VIN_5 45;
BA_ "GenSigSwitchedByIgnition" SG_ 1716 VIN_12 0;
BA_ "GenSigStartValue" SG_ 1716 VIN_12 45;
BA_ "GenSigSwitchedByIgnition" SG_ 1716 KS_Geheimnis_3 0;
BA_ "GenSigSwitchedByIgnition" SG_ 1716 VIN_6 0;
BA_ "GenSigStartValue" SG_ 1716 VIN_6 45;
BA_ "GenSigSwitchedByIgnition" SG_ 1716 VIN_13 0;
BA_ "GenSigStartValue" SG_ 1716 VIN_13 45;
BA_ "GenSigSwitchedByIgnition" SG_ 1716 KS_Geheimnis_4 0;
BA_ "GenSigSwitchedByIgnition" SG_ 1716 VIN_7 0;
BA_ "GenSigStartValue" SG_ 1716 VIN_7 45;
BA_ "GenSigSwitchedByIgnition" SG_ 1716 VIN_14 0;
BA_ "GenSigStartValue" SG_ 1716 VIN_14 45;
BA_ "GenSigSwitchedByIgnition" SG_ 1716 VIN_1 0;
BA_ "GenSigStartValue" SG_ 1716 VIN_1 45;
BA_ "GenSigSwitchedByIgnition" SG_ 1716 VIN_8 0;
BA_ "GenSigStartValue" SG_ 1716 VIN_8 45;
BA_ "GenSigSwitchedByIgnition" SG_ 1716 VIN_15 0;
BA_ "GenSigStartValue" SG_ 1716 VIN_15 45;
BA_ "GenSigSwitchedByIgnition" SG_ 1716 VIN_2 0;
BA_ "GenSigStartValue" SG_ 1716 VIN_2 45;
BA_ "GenSigSwitchedByIgnition" SG_ 1716 VIN_9 0;
BA_ "GenSigStartValue" SG_ 1716 VIN_9 45;
BA_ "GenSigSwitchedByIgnition" SG_ 1716 VIN_16 0;
BA_ "GenSigStartValue" SG_ 1716 VIN_16 45;
BA_ "GenSigSwitchedByIgnition" SG_ 1716 VIN_3 0;
BA_ "GenSigStartValue" SG_ 1716 VIN_3 45;
BA_ "GenSigSwitchedByIgnition" SG_ 1716 VIN_10 0;
BA_ "GenSigStartValue" SG_ 1716 VIN_10 45;
BA_ "GenSigSwitchedByIgnition" SG_ 1716 VIN_17 0;
BA_ "GenSigStartValue" SG_ 1716 VIN_17 45;
BA_ "GenSigSwitchedByIgnition" SG_ 1414 WH_KD_Fehler 0;
BA_ "GenSigSendType" SG_ 1414 WH_KD_Fehler 3;
BA_ "GenSigSwitchedByIgnition" SG_ 915 WBA_02_CHK 0;
BA_ "GenSigFuncType" SG_ 915 WBA_02_CHK 4;
BA_ "GenSigSendType" SG_ 915 WBA_02_CHK 0;
BA_ "GenSigSwitchedByIgnition" SG_ 915 WBA_02_BZ 0;
BA_ "GenSigFuncType" SG_ 915 WBA_02_BZ 1;
BA_ "GenSigSendType" SG_ 915 WBA_02_BZ 0;
BA_ "GenSigSwitchedByIgnition" SG_ 915 WBA_Senderkennung 0;
BA_ "GenSigSendType" SG_ 915 WBA_Senderkennung 3;
BA_ "GenSigSwitchedByIgnition" SG_ 915 WBA_Lampe_Shift_Lock 0;
BA_ "GenSigSwitchedByIgnition" SG_ 915 WBA_Schaltempf_verfbar 0;
BA_ "GenSigSwitchedByIgnition" SG_ 915 WBA_Effizienzmodus 0;
BA_ "GenSigSendType" SG_ 915 WBA_Effizienzmodus 3;
BA_ "GenSigSwitchedByIgnition" SG_ 915 WBA_Kurzzeittipp 0;
BA_ "GenSigSwitchedByIgnition" SG_ 915 WBA_Blinken 0;
BA_ "GenSigSwitchedByIgnition" SG_ 915 WBA_Getriebevariante 0;
BA_ "GenSigSwitchedByIgnition" SG_ 915 WBA_GE_Warnung 0;
BA_ "GenSigSendType" SG_ 915 WBA_GE_Warnung 3;
BA_ "GenSigSwitchedByIgnition" SG_ 915 WBA_Fahrstufe 0;
BA_ "GenSigSwitchedByIgnition" SG_ 915 WBA_Istgang 0;
BA_ "GenSigSwitchedByIgnition" SG_ 915 WBA_eing_Gang 0;
BA_ "GenSigStartValue" SG_ 915 WBA_eing_Gang 1;
BA_ "GenSigSwitchedByIgnition" SG_ 915 WBA_Sollgang 0;
BA_ "GenSigSwitchedByIgnition" SG_ 915 WBA_GE_Texte 0;
BA_ "GenSigSwitchedByIgnition" SG_ 915 WBA_Schaltschema_Aktiv 0;
BA_ "GenSigSwitchedByIgnition" SG_ 915 WH_Warnung 0;
BA_ "GenSigSwitchedByIgnition" SG_ 915 WBA_GE_Zusatzwarnungen 0;
BA_ "GenSigSwitchedByIgnition" SG_ 915 WBA_Segeln_aktiv 0;
BA_ "GenSigSwitchedByIgnition" SG_ 915 GE_Tipschaltempf_verfuegbar 0;
BA_ "GenSigFuncType" SG_ 915 GE_Tipschaltempf_verfuegbar 8;
BA_ "GenSigSwitchedByIgnition" SG_ 915 GE_Sollgang 0;
BA_ "Fehlerwert" SG_ 1602 WIV_Verschleissindex 65535;
BA_ "GenSigSwitchedByIgnition" SG_ 1602 WIV_Verschleissindex 0;
BA_ "GenSigSendType" SG_ 1602 WIV_Verschleissindex 0;
BA_ "Fehlerwert" SG_ 1602 WIV_Russindex 65535;
BA_ "GenSigSwitchedByIgnition" SG_ 1602 WIV_Russindex 0;
BA_ "GenSigSendType" SG_ 1602 WIV_Russindex 0;
BA_ "GenSigSwitchedByIgnition" SG_ 1602 WIV_t_min 0;
BA_ "GenSigStartValue" SG_ 1602 WIV_t_min 12;
BA_ "GenSigSendType" SG_ 1602 WIV_t_min 0;
BA_ "GenSigSwitchedByIgnition" SG_ 1602 WIV_t_max 0;
BA_ "GenSigStartValue" SG_ 1602 WIV_t_max 24;
BA_ "GenSigSendType" SG_ 1602 WIV_t_max 0;
BA_ "GenSigSwitchedByIgnition" SG_ 1602 WIV_W_min 0;
BA_ "GenSigStartValue" SG_ 1602 WIV_W_min 17;
BA_ "GenSigSendType" SG_ 1602 WIV_W_min 0;
BA_ "GenSigSwitchedByIgnition" SG_ 1602 WIV_W_max 0;
BA_ "GenSigStartValue" SG_ 1602 WIV_W_max 31;
BA_ "GenSigSendType" SG_ 1602 WIV_W_max 0;
BA_ "GenSigSwitchedByIgnition" SG_ 2616990720 XCP_ESP_CRO_01_Data 0;
BA_ "GenSigSwitchedByIgnition" SG_ 2616990724 XCP_ESP_DTO_01_Data 0;
BA_REL_ "GenSigTimeoutTime" BU_SG_REL_ Getriebe_DL382_MLB SG_ 913 OBD_Calc_Load_Val 1000;
BA_REL_ "GenSigTimeoutTime" BU_SG_REL_ Getriebe_DL382_MLB SG_ 913 OBD_Eng_Cool_Temp 1000;
BA_REL_ "GenSigTimeoutTime" BU_SG_REL_ Getriebe_DL382_MLB SG_ 913 OBD_Abs_Throttle_Pos 1000;
BA_REL_ "GenSigTimeoutTime" BU_SG_REL_ Getriebe_DL382_MLB SG_ 913 OBD_Abs_Load_Val 1000;
BA_REL_ "GenSigTimeoutTime" BU_SG_REL_ Getriebe_DL382_MLB SG_ 913 OBD_Abs_Pedal_Pos 1000;
BA_REL_ "GenSigTimeoutTime" BU_SG_REL_ Getriebe_DL382_MLB SG_ 913 OBD_Sperrung_IUMPR 1000;
BA_REL_ "GenSigTimeoutTime" BU_SG_REL_ Getriebe_DL382_MLB SG_ 913 OBD_Minimum_Trip 1000;
BA_REL_ "GenSigTimeoutTime" BU_SG_REL_ Getriebe_DL382_MLB SG_ 913 OBD_Driving_Cycle 1000;
BA_REL_ "GenSigTimeoutTime" BU_SG_REL_ Getriebe_DL382_MLB SG_ 913 OBD_Warm_Up_Cycle 1000;
BA_REL_ "GenSigTimeoutTime" BU_SG_REL_ Getriebe_DL382_MLB SG_ 913 OBD_Normed_Trip 1000;
BA_REL_ "GenSigTimeoutTime" BU_SG_REL_ Getriebe_DL382_MLB SG_ 929 PSD_Pos_Segment_ID 1500;
BA_REL_ "GenSigTimeoutTime" BU_SG_REL_ Getriebe_DL382_MLB SG_ 929 PSD_Pos_Segmentlaenge 1500;
BA_REL_ "GenSigTimeoutTime" BU_SG_REL_ Getriebe_DL382_MLB SG_ 929 PSD_Pos_Inhibitzeit 1500;
BA_REL_ "GenSigTimeoutTime" BU_SG_REL_ Getriebe_DL382_MLB SG_ 929 PSD_Pos_Standort 1500;
BA_REL_ "GenSigTimeoutTime" BU_SG_REL_ Getriebe_DL382_MLB SG_ 929 PSD_Pos_Laengsfehler 1500;
BA_REL_ "GenSigTimeoutTime" BU_SG_REL_ Getriebe_DL382_MLB SG_ 929 PSD_Segment_ID 1500;
BA_REL_ "GenSigTimeoutTime" BU_SG_REL_ Getriebe_DL382_MLB SG_ 929 PSD_Vorgaenger_Segment_ID 1500;
BA_REL_ "GenSigTimeoutTime" BU_SG_REL_ Getriebe_DL382_MLB SG_ 929 PSD_Strassenklasse 1500;
BA_REL_ "GenSigTimeoutTime" BU_SG_REL_ Getriebe_DL382_MLB SG_ 929 PSD_Segmentlaenge 1500;
BA_REL_ "GenSigTimeoutTime" BU_SG_REL_ Getriebe_DL382_MLB SG_ 929 PSD_Rampe 1500;
BA_REL_ "GenSigTimeoutTime" BU_SG_REL_ Getriebe_DL382_MLB SG_ 929 PSD_Endkruemmung 1500;
BA_REL_ "GenSigTimeoutTime" BU_SG_REL_ Getriebe_DL382_MLB SG_ 929 PSD_Endkruemmung_Vorz 1500;
BA_REL_ "GenSigTimeoutTime" BU_SG_REL_ Getriebe_DL382_MLB SG_ 929 PSD_Endsteigung 1500;
BA_REL_ "GenSigTimeoutTime" BU_SG_REL_ Getriebe_DL382_MLB SG_ 929 PSD_Endsteigung_Vorz 1500;
BA_REL_ "GenSigTimeoutTime" BU_SG_REL_ Getriebe_DL382_MLB SG_ 929 PSD_ADAS_Qualitaet 1500;
BA_REL_ "GenSigTimeoutTime" BU_SG_REL_ Getriebe_DL382_MLB SG_ 929 PSD_Fahrspuren 1500;
BA_REL_ "GenSigTimeoutTime" BU_SG_REL_ Getriebe_DL382_MLB SG_ 929 PSD_wahrscheinlichster_Pfad 1500;
BA_REL_ "GenSigTimeoutTime" BU_SG_REL_ Getriebe_DL382_MLB SG_ 930 PSD_Multiplex 1500;
BA_REL_ "GenSigTimeoutTime" BU_SG_REL_ Getriebe_DL382_MLB SG_ 930 PSD_Sys_Segment_ID 1500;
BA_REL_ "GenSigTimeoutTime" BU_SG_REL_ Getriebe_DL382_MLB SG_ 930 PSD_Abz_Segment_ID 1500;
BA_REL_ "GenSigTimeoutTime" BU_SG_REL_ Getriebe_DL382_MLB SG_ 930 PSD_Ges_Segment_ID 1500;
BA_REL_ "GenSigTimeoutTime" BU_SG_REL_ Getriebe_DL382_MLB SG_ 930 PSD_Ort_Laenge_VZ 1500;
BA_REL_ "GenSigTimeoutTime" BU_SG_REL_ Getriebe_DL382_MLB SG_ 930 PSD_Ort_Laenge 1500;
BA_REL_ "GenSigTimeoutTime" BU_SG_REL_ Getriebe_DL382_MLB SG_ 930 PSD_Sys_Laendercode 1500;
BA_REL_ "GenSigTimeoutTime" BU_SG_REL_ Getriebe_DL382_MLB SG_ 930 PSD_Abz_Segmentlaenge 1500;
BA_REL_ "GenSigTimeoutTime" BU_SG_REL_ Getriebe_DL382_MLB SG_ 930 PSD_Ges_Geschwindigkeit 1500;
BA_REL_ "GenSigTimeoutTime" BU_SG_REL_ Getriebe_DL382_MLB SG_ 930 PSD_Ges_Geschwindigkeit_Typ 1500;
BA_REL_ "GenSigTimeoutTime" BU_SG_REL_ Getriebe_DL382_MLB SG_ 930 PSD_Ges_Geschwindigkeit_Gespann 1500;
BA_REL_ "GenSigTimeoutTime" BU_SG_REL_ Getriebe_DL382_MLB SG_ 930 PSD_Abz_Vorgaenger_Segment_ID 1500;
BA_REL_ "GenSigTimeoutTime" BU_SG_REL_ Getriebe_DL382_MLB SG_ 930 PSD_Sys_Geschwindigkeit_Einheit 1500;
BA_REL_ "GenSigTimeoutTime" BU_SG_REL_ Getriebe_DL382_MLB SG_ 930 PSD_Ges_Geschwindigkeit_Witter 1500;
BA_REL_ "GenSigTimeoutTime" BU_SG_REL_ Getriebe_DL382_MLB SG_ 930 PSD_Sys_Verkehrsrichtung 1500;
BA_REL_ "GenSigTimeoutTime" BU_SG_REL_ Getriebe_DL382_MLB SG_ 930 PSD_Sys_Release_Monat 1500;
BA_REL_ "GenSigTimeoutTime" BU_SG_REL_ Getriebe_DL382_MLB SG_ 930 PSD_Ges_Geschwindigkeit_Tag_Anf 1500;
BA_REL_ "GenSigTimeoutTime" BU_SG_REL_ Getriebe_DL382_MLB SG_ 930 PSD_Abz_Geschwindigkeit 1500;
BA_REL_ "GenSigTimeoutTime" BU_SG_REL_ Getriebe_DL382_MLB SG_ 930 PSD_Ges_Geschwindigkeit_Tag_Ende 1500;
BA_REL_ "GenSigTimeoutTime" BU_SG_REL_ Getriebe_DL382_MLB SG_ 930 PSD_Sys_Release_Jahr 1500;
BA_REL_ "GenSigTimeoutTime" BU_SG_REL_ Getriebe_DL382_MLB SG_ 930 PSD_Ges_Geschwindigkeit_Std_Anf 1500;
BA_REL_ "GenSigTimeoutTime" BU_SG_REL_ Getriebe_DL382_MLB SG_ 930 PSD_Abz_Geschwindigkeit_Typ 1500;
BA_REL_ "GenSigTimeoutTime" BU_SG_REL_ Getriebe_DL382_MLB SG_ 930 PSD_Sys_Tunnel 1500;
BA_REL_ "GenSigTimeoutTime" BU_SG_REL_ Getriebe_DL382_MLB SG_ 930 PSD_Abz_Strassenklasse 1500;
BA_REL_ "GenSigTimeoutTime" BU_SG_REL_ Getriebe_DL382_MLB SG_ 930 PSD_Sys_Bruecke 1500;
BA_REL_ "GenSigTimeoutTime" BU_SG_REL_ Getriebe_DL382_MLB SG_ 930 PSD_Ort_Breite_VZ 1500;
BA_REL_ "GenSigTimeoutTime" BU_SG_REL_ Getriebe_DL382_MLB SG_ 930 PSD_Sys_Fahrsp_Gegenr 1500;
BA_REL_ "GenSigTimeoutTime" BU_SG_REL_ Getriebe_DL382_MLB SG_ 930 PSD_Abz_ADAS_Qualitaet 1500;
BA_REL_ "GenSigTimeoutTime" BU_SG_REL_ Getriebe_DL382_MLB SG_ 930 PSD_Ges_Geschwindigkeit_Std_Ende 1500;
BA_REL_ "GenSigTimeoutTime" BU_SG_REL_ Getriebe_DL382_MLB SG_ 930 PSD_Ort_Breite 1500;
BA_REL_ "GenSigTimeoutTime" BU_SG_REL_ Getriebe_DL382_MLB SG_ 930 PSD_Abz_Abzweigerichtung 1500;
BA_REL_ "GenSigTimeoutTime" BU_SG_REL_ Getriebe_DL382_MLB SG_ 930 PSD_Sys_TMC_Baustelle 1500;
BA_REL_ "GenSigTimeoutTime" BU_SG_REL_ Getriebe_DL382_MLB SG_ 930 PSD_Abz_Abzweigewinkel 1500;
BA_REL_ "GenSigTimeoutTime" BU_SG_REL_ Getriebe_DL382_MLB SG_ 930 PSD_Sys_TMC_Stau 1500;
BA_REL_ "GenSigTimeoutTime" BU_SG_REL_ Getriebe_DL382_MLB SG_ 930 PSD_Ges_alter_Geschw 1500;
BA_REL_ "GenSigTimeoutTime" BU_SG_REL_ Getriebe_DL382_MLB SG_ 930 PSD_Sys_Geometrieguete 1500;
BA_REL_ "GenSigTimeoutTime" BU_SG_REL_ Getriebe_DL382_MLB SG_ 930 PSD_Abz_Rampe 1500;
BA_REL_ "GenSigTimeoutTime" BU_SG_REL_ Getriebe_DL382_MLB SG_ 930 PSD_Abz_Anfangskruemmung 1500;
BA_REL_ "GenSigTimeoutTime" BU_SG_REL_ Getriebe_DL382_MLB SG_ 930 PSD_Ges_alter_Geschw_Gespann 1500;
BA_REL_ "GenSigTimeoutTime" BU_SG_REL_ Getriebe_DL382_MLB SG_ 930 PSD_Ges_alter_Geschw_Witter 1500;
BA_REL_ "GenSigTimeoutTime" BU_SG_REL_ Getriebe_DL382_MLB SG_ 930 PSD_Sys_Ortsschild 1500;
BA_REL_ "GenSigTimeoutTime" BU_SG_REL_ Getriebe_DL382_MLB SG_ 930 PSD_Ges_alter_Geschw_Tag_Anf 1500;
BA_REL_ "GenSigTimeoutTime" BU_SG_REL_ Getriebe_DL382_MLB SG_ 930 PSD_Abz_Anfangskruemmung_Vorz 1500;
BA_REL_ "GenSigTimeoutTime" BU_SG_REL_ Getriebe_DL382_MLB SG_ 930 PSD_Sys_Anfangskruemmung 1500;
BA_REL_ "GenSigTimeoutTime" BU_SG_REL_ Getriebe_DL382_MLB SG_ 930 PSD_Abz_Endkruemmung 1500;
BA_REL_ "GenSigTimeoutTime" BU_SG_REL_ Getriebe_DL382_MLB SG_ 930 PSD_Ges_alter_Geschw_Tag_Ende 1500;
BA_REL_ "GenSigTimeoutTime" BU_SG_REL_ Getriebe_DL382_MLB SG_ 930 PSD_Ges_alter_Geschw_Std_Anf 1500;
BA_REL_ "GenSigTimeoutTime" BU_SG_REL_ Getriebe_DL382_MLB SG_ 930 PSD_Ort_Hoehe 1500;
BA_REL_ "GenSigTimeoutTime" BU_SG_REL_ Getriebe_DL382_MLB SG_ 930 PSD_Sys_Anfangskruemmung_Vorz 1500;
BA_REL_ "GenSigTimeoutTime" BU_SG_REL_ Getriebe_DL382_MLB SG_ 930 PSD_Abz_Endkruemmung_Vorz 1500;
BA_REL_ "GenSigTimeoutTime" BU_SG_REL_ Getriebe_DL382_MLB SG_ 930 PSD_Ges_alter_Geschw_Std_Ende 1500;
BA_REL_ "GenSigTimeoutTime" BU_SG_REL_ Getriebe_DL382_MLB SG_ 930 PSD_Sys_Anfangssteigung 1500;
BA_REL_ "GenSigTimeoutTime" BU_SG_REL_ Getriebe_DL382_MLB SG_ 930 PSD_Abz_Endsteigung 1500;
BA_REL_ "GenSigTimeoutTime" BU_SG_REL_ Getriebe_DL382_MLB SG_ 930 PSD_Ges_Ueberholverbot 1500;
BA_REL_ "GenSigTimeoutTime" BU_SG_REL_ Getriebe_DL382_MLB SG_ 930 PSD_Sys_Anfangssteigung_Vorz 1500;
BA_REL_ "GenSigTimeoutTime" BU_SG_REL_ Getriebe_DL382_MLB SG_ 930 PSD_Abz_Endsteigung_Vorz 1500;
BA_REL_ "GenSigTimeoutTime" BU_SG_REL_ Getriebe_DL382_MLB SG_ 930 PSD_Sys_Ortschaft 1500;
BA_REL_ "GenSigTimeoutTime" BU_SG_REL_ Getriebe_DL382_MLB SG_ 930 PSD_Abz_Fahrspuren 1500;
BA_REL_ "GenSigTimeoutTime" BU_SG_REL_ Getriebe_DL382_MLB SG_ 930 PSD_Ges_Wechselverkehrszeichen 1500;
BA_REL_ "GenSigTimeoutTime" BU_SG_REL_ Getriebe_DL382_MLB SG_ 930 PSD_Sys_Digitalisierung 1500;
BA_REL_ "GenSigTimeoutTime" BU_SG_REL_ Getriebe_DL382_MLB SG_ 930 PSD_Sys_Zielfuehrung 1500;
BA_REL_ "GenSigTimeoutTime" BU_SG_REL_ Getriebe_DL382_MLB SG_ 930 PSD_Abz_wahrscheinlichster_Pfad 1500;
BA_REL_ "GenSigTimeoutTime" BU_SG_REL_ Gateway SG_ 1528 SAK_KD_Fehler 5000;
BA_REL_ "GenSigTimeoutTime" BU_SG_REL_ Gateway SG_ 1507 SCR_KD_Fehler 5000;
BA_REL_ "GenSigTimeoutTime" BU_SG_REL_ Gateway SG_ 133 SCU_KD_Fehler 500;
BA_REL_ "GenSigTimeoutTime" BU_SG_REL_ SAK SG_ 1413 SI_NWDF 5000;
BA_REL_ "GenSigTimeoutTime" BU_SG_REL_ SAK SG_ 1413 SI_NWDF_gueltig 5000;
BA_REL_ "GenSigTimeoutTime" BU_SG_REL_ Getriebe_DL382_MLB SG_ 270 TSK_zul_Regelabw 500;
BA_REL_ "GenSigTimeoutTime" BU_SG_REL_ Getriebe_DL382_MLB SG_ 270 TSK_ax_Getriebe 500;
BA_REL_ "GenSigTimeoutTime" BU_SG_REL_ Getriebe_DL382_MLB SG_ 270 TSK_Wunsch_Uebersetz 500;
BA_REL_ "GenSigTimeoutTime" BU_SG_REL_ Getriebe_DL382_MLB SG_ 270 TSK_Freig_WU 500;
BA_REL_ "GenSigTimeoutTime" BU_SG_REL_ Getriebe_DL382_MLB SG_ 270 TSK_Limiter_aktiv 500;
BA_REL_ "GenSigTimeoutTime" BU_SG_REL_ Getriebe_DL382_MLB SG_ 270 TSK_Status_GRA_ACC_02 500;
BA_REL_ "GenSigTimeoutTime" BU_SG_REL_ Getriebe_DL382_MLB SG_ 273 TSK_QBit_Steigung 500;
BA_REL_ "GenSigTimeoutTime" BU_SG_REL_ Getriebe_DL382_MLB SG_ 273 TSK_QBit_Fahrzeugmasse 500;
BA_REL_ "GenSigTimeoutTime" BU_SG_REL_ Getriebe_DL382_MLB SG_ 273 TSK_Fahrzeugmasse_02 500;
BA_REL_ "GenSigTimeoutTime" BU_SG_REL_ Getriebe_DL382_MLB SG_ 273 TSK_Steigung 500;
BA_REL_ "GenSigTimeoutTime" BU_SG_REL_ Getriebe_DL382_MLB SG_ 273 TSK_Codierung_ACC 500;
BA_REL_ "GenSigTimeoutTime" BU_SG_REL_ Getriebe_DL382_MLB SG_ 273 TSK_Freig_Verzoeg_Anf 500;
BA_REL_ "GenSigTimeoutTime" BU_SG_REL_ SAK SG_ 1716 VIN_01_MUX 2000;
BA_REL_ "GenSigTimeoutTime" BU_SG_REL_ SAK SG_ 1716 VIN_7 2000;
BA_REL_ "GenSigTimeoutTime" BU_SG_REL_ SAK SG_ 1716 VIN_8 2000;
BA_REL_ "GenSigTimeoutTime" BU_SG_REL_ Gateway SG_ 1414 WH_KD_Fehler 5000;
VAL_ 913 OBD_Sperrung_IUMPR 0 "IUMPR_Berechnung_freigegeben" 1 "IUMPR_Berechnung_gesperrt" ;
VAL_ 913 OBD_Kaltstart_Denominator 0 "Denominator_nicht_hochzaehlen" 1 "Bedingungen_zum_Inkr_des_Kaltstart_Denom_erf" ;
VAL_ 913 OBD_Minimum_Trip 0 "kein_Min_Normed_Trip" 1 "Min_Normed_Trip" ;
VAL_ 913 OBD_Driving_Cycle 0 "kein Driving Cycle erkannt" 1 "DC erkannt" ;
VAL_ 913 OBD_Warm_Up_Cycle 0 "kein Warm Up Cycle erkannt" 1 "Warm Up Cycle erkannt" ;
VAL_ 913 OBD_Normed_Trip 0 "kein Normed Trip" 1 "Normed Trip erfüllt" ;
VAL_ 1630 OBD_TG_F_Status_1 0 "kein Fehler / Init / nicht verbaut" 1 "KS- (Kurzschluss nach minus)" 2 "KS+ (Kurzschluss nach plus)" 3 "OC (Leitungsunterbrechung)" 4 "OOR+ (Signal zu gross)" 5 "OOR- (Signal zu klein)" 6 "RC+ (Signal unplausibel zu gross)" 7 "RC- (Signal unplausibel zu klein)" 8 "KS+/OC (Kurzschluss nach plus/Unterbrechung)" 9 "KS-/OC  (Kurzschluss nach minus/Unterbrechung)" 10 "KS-/KS+  (Kurzschluss nach minus/plus)" 11 "KS-/KS+/OC (Kurzschluss nach minus/plus/Unterbrechung)" 12 "frei" 13 "frei" 14 "frei" 15 "frei" ;
VAL_ 1630 OBD_TG_F_Status_2 0 "kein Fehler / Init / nicht verbaut" 1 "KS- (Kurzschluss nach minus)" 2 "KS+ (Kurzschluss nach plus)" 3 "OC (Leitungsunterbrechung)" 4 "OOR+ (Signal zu gross)" 5 "OOR- (Signal zu klein)" 6 "RC+ (Signal unplausibel zu gross)" 7 "RC- (Signal unplausibel zu klein)" 8 "KS+/OC (Kurzschluss nach plus/Unterbrechung)" 9 "KS-/OC  (Kurzschluss nach minus/Unterbrechung)" 10 "KS-/KS+  (Kurzschluss nach minus/plus)" 11 "KS-/KS+/OC (Kurzschluss nach minus/plus/Unterbrechung)" 12 "frei" 13 "frei" 14 "frei" 15 "frei" ;
VAL_ 1630 OBD_TG_F_Status_3 0 "kein Fehler / Init / nicht verbaut" 1 "KS- (Kurzschluss nach minus)" 2 "KS+ (Kurzschluss nach plus)" 3 "OC (Leitungsunterbrechung)" 4 "OOR+ (Signal zu gross)" 5 "OOR- (Signal zu klein)" 6 "RC+ (Signal unplausibel zu gross)" 7 "RC- (Signal unplausibel zu klein)" 8 "KS+/OC (Kurzschluss nach plus/Unterbrechung)" 9 "KS-/OC  (Kurzschluss nach minus/Unterbrechung)" 10 "KS-/KS+  (Kurzschluss nach minus/plus)" 11 "KS-/KS+/OC (Kurzschluss nach minus/plus/Unterbrechung)" 12 "frei" 13 "frei" 14 "frei" 15 "frei" ;
VAL_ 1630 OBD_TG_F_Status_4 0 "kein Fehler / Init / nicht verbaut" 1 "KS- (Kurzschluss nach minus)" 2 "KS+ (Kurzschluss nach plus)" 3 "OC (Leitungsunterbrechung)" 4 "OOR+ (Signal zu gross)" 5 "OOR- (Signal zu klein)" 6 "RC+ (Signal unplausibel zu gross)" 7 "RC- (Signal unplausibel zu klein)" 8 "KS+/OC (Kurzschluss nach plus/Unterbrechung)" 9 "KS-/OC  (Kurzschluss nach minus/Unterbrechung)" 10 "KS-/KS+  (Kurzschluss nach minus/plus)" 11 "KS-/KS+/OC (Kurzschluss nach minus/plus/Unterbrechung)" 12 "frei" 13 "frei" 14 "frei" 15 "frei" ;
VAL_ 803 PCF_Objektstatus 0 "Kein_relevantes_Objekt_erkannt" 1 "Relevantes_Objekt_vorausfahrend" 2 "Relevantes_Objekt_stehend" 3 "Relevantes_Objekt_angehalten" 4 "Relevantes_Objekt_entgegenkommend" 5 "Ungueltig" 6 "Ungueltig" 7 "Ungueltig" ;
VAL_ 803 PCF_Fahrer_aktiv_erkannt 0 "Fahrer_nicht_aktiv" 1 "Fahrer_aktiv" ;
VAL_ 803 PCF_Time_to_collision 255 "Objektstatus=0x0__oder_berechneter_TTC_Wert_groesser_als_Maximalwert" ;
VAL_ 803 PCF_v_rel 0 " Objektstatus_0x0_oder _berechnete_v_rel_>= 0_(Objekt_entfernt_sich_oder_faehrt_vorraus_mit v_Obj_=_v_ego)" ;
VAL_ 803 PCF_dy_Kollisionsueberdeckung 0 "Keine_Ueberdeckung_oder_bei_Objektstatus_0x0" 30 "Ueberdeckung_groesser_Maximalwert" 31 "Objekueberdeckung_nicht_ermittelbar" ;
VAL_ 802 PCR_Sensorstatus 0 "Sensor_ok" 1 "Sensor_nok" ;
VAL_ 802 PCR_Obj_vx_rel 2047 "Fehler" ;
VAL_ 802 PCR_Obj_vy_rel 2047 "Fehler" ;
VAL_ 802 PCR_Obj_TTC 511 "Fehler" ;
VAL_ 802 PCR_Obj_Guete 127 "Fehler" ;
VAL_ 802 PCR_Crashwahrscheinlichkeit 127 "Fehler" ;
VAL_ 802 PCR_Sensorstatus_02 0 "Sensor_ok" 1 "zur_Zeit_eingeschraenkt" 2 "zur_Zeit_eingeschraenkt_keine_Sensorsicht" 3 "zur_Zeit_eingeschraenkt_Anhaengerbetrieb" 4 "Systemstoerung_SWA" ;
VAL_ 929 PSD_Pos_Segment_ID 0 "keine Position gegeben" 1 "Fehlerwert" ;
VAL_ 929 PSD_Pos_Standort 0 "mehrdeutiger_Standort" 1 "eindeutiger_Standort" ;
VAL_ 929 PSD_Pos_Laengsfehler 0 "keine Prädiktion (off-road)" 1 "< 2m" 2 "< 5m" 3 "< 10m " 4 "< 20m" 5 "< 50m" 6 "> 50m " 7 "nicht erlaubt" ;
VAL_ 929 PSD_Segment_ID 0 "keine Segmentinformationen vorhanden" 1 "Fehlerwert" ;
VAL_ 929 PSD_Vorgaenger_Segment_ID 0 "keine Segmentinformation vorhanden" 1 "Fehlerwert" ;
VAL_ 929 PSD_Strassenklasse 0 "Rest_Feldweg_Schotterweg_Privatweg" 1 "Ortsstrasse" 2 "Bundes_Landstrasse" 3 "Autobahn" ;
VAL_ 929 PSD_Rampe 0 "Strasse_mit_Gegenverkehr" 1 "Auffahrt_Einbahnstr" 2 "Abfahrt_Einbahnstr" 3 "Einbahnstrasse" ;
VAL_ 929 PSD_Endkruemmung 255 "Gerade" ;
VAL_ 929 PSD_Endkruemmung_Vorz 0 "Kruemmung_positiv" 1 "Kruemmung_negativ" ;
VAL_ 929 PSD_Endsteigung 30 "gleich_oder_mehr_15_Prozent_Steigung" 31 "nicht_definiert" ;
VAL_ 929 PSD_Endsteigung_Vorz 0 "Gefaelle" 1 "Steigung" ;
VAL_ 929 PSD_ADAS_Qualitaet 0 "keine_ADAS_Qualitaet" 1 "ADAS_Qualitaet" ;
VAL_ 929 PSD_Fahrspuren 0 "Einbahnstrasse_in_falscher_Richtung" 1 "eine_Fahrspur" 2 "zwei_Fahrspuren" 3 "drei_Fahrspuren" ;
VAL_ 929 PSD_wahrscheinlichster_Pfad 0 "Pfad_mit_geringer_Wahrscheinlichkeit" 1 "wahrscheinlichster_Pfad" ;
VAL_ 930 PSD_Multiplex 0 "für System Informationen, die sich nur langsam ändern" 1 "Informationen über ein Streckensegment" 2 "für Informationen über Geschwindigkeitsbegrenzungen und mögliche Einschränkungen der Geschwindigkeitsbegrenzungen" 3 "Fahrzeugposition aus der Koppelortung" ;
VAL_ 930 PSD_Sys_Segment_ID 0 "keine Segmentinformationen vorhanden" 1 "nicht zulaessig" ;
VAL_ 930 PSD_Abz_Segment_ID 0 "keine Segmentinformationen vorhanden" 1 "nicht zulaessig" ;
VAL_ 930 PSD_Ges_Segment_ID 0 "keine Segmentinformationen vorhanden" 1 "nicht zulaessig" ;
VAL_ 930 PSD_Ort_Laenge_VZ 0 "Ost" 1 "West" ;
VAL_ 930 PSD_Ort_Laenge 33554431 "Keine GPS Position verfuegbar" ;
VAL_ 930 PSD_Ges_Geschwindigkeit 0 "Kein Geschwindigkeitsgebot" 1 "0 km/h < v_max <  5 km/h" 2 "5 km/h < v_max < 10km/h" 3 "10 km/h < v_max < 15 km/h" 4 "15 km/h < v_max < 20 km/h" 5 "20 km/h < v_max < 25 km/h" 6 "25 km/h < v_max < 30 km/h" 7 "30 km/h < v_max < 35 km/h" 8 "35 km/h < v_max < 40 km/h" 9 "40 km/h < v_max < 45 km/h" 10 "45 km/h < v_max < 50 km/h" 11 "50 km/h < v_max < 60 km/h" 12 "60 km/h < v_max < 70 km/h" 13 "70 km/h < v_max < 80 km/h" 14 "80 km/h < v_max < 90 km/h" 15 "90 km/h < v_max < 100 km/h" 16 "100 km/h < v_max < 110 km/h" 17 "110 km/h < v_max < 120 km/h" 18 " 120 km/h < v_max < 130 km/h" 19 "130 km/h < v_max < 140 km/h" 20 "140 km/h < v_max < 150 km/h" 21 "150 km/h < v_max < 160 km/h" 22 "160 km/h < v_max" 23 "Geschwindigkeitsgebot aufgehoben" 24 "..0x1F ungültig" ;
VAL_ 930 PSD_Ges_Geschwindigkeit_Typ 0 "Der Wert im Attribut Geschwindigkeitsbegrenzung entspricht der Geschwindigkeitsklasse von Navteq." 1 "Der Wert im Attribut Geschwindigkeitsbegrenzung entspricht einer explizit angegebenen Begrenzung der Geschwindigkeit." ;
VAL_ 930 PSD_Ges_Geschwindigkeit_Gespann 0 "alle Fahrzeuge" 1 "PKW mit Gespann" 2 "LKW, Busse, etc." ;
VAL_ 930 PSD_Abz_Vorgaenger_Segment_ID 0 "keine Segmentinformationen vorhanden" 1 "nicht zulaessig" ;
VAL_ 930 PSD_Sys_Geschwindigkeit_Einheit 0 "km/h" 1 "mph" ;
VAL_ 930 PSD_Ges_Geschwindigkeit_Witter 0 "Witterungsunabhängig" 1 "Nässe, Regen, Niederschlag" 2 "Glätte" 3 "Nebel" ;
VAL_ 930 PSD_Sys_Verkehrsrichtung 0 "Rechtsverkehr" 1 "Linksverkehr" ;
VAL_ 930 PSD_Ges_Geschwindigkeit_Tag_Anf 0 "kein Beginn definiert" 1 "Montag" 2 "Dienstag" 3 "Mittwoch" 4 "Donnerstag" 5 "Freitag" 6 "Samstag" 7 "Sonntag" ;
VAL_ 930 PSD_Abz_Geschwindigkeit 0 "kein Geschwindigkeitsgebot" 1 "0 km/h < v_max <  5 km/h" 2 "5 km/h ¿ v_max < 10km/h" 3 "10 km/h ¿ v_max < 15 km/h" 4 "15 km/h ¿ v_max < 20 km/h" 5 "20 km/h ¿ v_max < 25 km/h" 6 "25 km/h ¿ v_max < 30 km/h" 7 "30 km/h ¿ v_max < 35 km/h" 8 "35 km/h ¿ v_max < 40 km/h" 9 "40 km/h ¿ v_max < 45 km/h" 10 "45 km/h ¿ v_max < 50 km/h" 11 "50 km/h ¿ v_max < 60 km/h" 12 "60 km/h ¿ v_max < 70 km/h" 13 "70 km/h ¿ v_max < 80 km/h" 14 "80 km/h ¿ v_max < 90 km/h" 15 "90 km/h ¿ v_max < 100 km/h" 16 "100 km/h ¿ v_max < 110 km/h" 17 "110 km/h ¿ v_max < 120 km/h" 18 "120 km/h ¿ v_max < 130 km/h" 19 "130 km/h ¿ v_max < 140 km/h" 20 "140 km/h ¿ v_max < 150 km/h" 21 "150 km/h ¿ v_max < 160 km/h" 22 "160 km/h ¿ v_max" 23 " Geschwindigkeitsgebot aufgehoben" 24 "..0x1F ungültig" ;
VAL_ 930 PSD_Ges_Geschwindigkeit_Tag_Ende 0 "kein Ende definiert" 1 "Montag" 2 "Dienstag" 3 "Mittwoch" 4 "Donnerstag" 5 "Freitag" 6 "Samstag" 7 "Sonntag" ;
VAL_ 930 PSD_Ges_Geschwindigkeit_Std_Anf 25 "kein Beginn für stundenweise Einschränkungen" ;
VAL_ 930 PSD_Abz_Geschwindigkeit_Typ 0 "Der Wert im Attribut Geschwindigkeitsbegrenzung entspricht der Geschwindigkeitsklasse von Navteq." 1 "Der Wert im Attribut Geschwindigkeitsbegrenzung entspricht einer explizit angegebenen Begrenzung der Geschwindigkeit" ;
VAL_ 930 PSD_Sys_Tunnel 0 "kein Tunnel oder keine Information verfuegbar" 1 "Tunnel" ;
VAL_ 930 PSD_Abz_Strassenklasse 0 " Rest (Feldweg, Schotter, Privatweg)" 1 "Ortsstraße" 2 "Bundes-,Landstrasse" 3 "Autobahn" ;
VAL_ 930 PSD_Sys_Bruecke 0 "keine Bruecke oder keine Information verfuegbar" 1 "Bruecke" ;
VAL_ 930 PSD_Ort_Breite_VZ 0 "Nord" 1 "Sued" ;
VAL_ 930 PSD_Sys_Fahrsp_Gegenr 0 "keine Fahrspur" 1 "eine Fahrspur" 2 "mehr als eine Fahrspur" 3 "keine Information verfuegbar" ;
VAL_ 930 PSD_Abz_ADAS_Qualitaet 0 "keine ADAS Qualität" 1 "ADAS Qualität" ;
VAL_ 930 PSD_Ges_Geschwindigkeit_Std_Ende 25 "kein Ende für stundenweise Einschränkungen" ;
VAL_ 930 PSD_Abz_Abzweigerichtung 0 "rechts abzweigende Straße" 1 "links abzweigende Straße" ;
VAL_ 930 PSD_Sys_TMC_Baustelle 0 "keine Baustelle oder keine Information verfuegbar" 1 "Baustelle" ;
VAL_ 930 PSD_Abz_Abzweigewinkel 0 "0¿: Straße verläuft gerade aus" 1 "0¿ < Winkel ¿ 12¿" 2 "12¿ < Winkel ¿ 24¿" 3 "24¿ < Winkel ¿ 36¿" 4 "36¿ < Winkel ¿ 48¿" 5 "48¿ < Winkel ¿ 60¿" 6 "60¿ < Winkel ¿ 72¿" 7 "72¿ < Winkel ¿ 84¿" 8 "84¿ < Winkel ¿ 96¿" 9 "96¿ < Winkel ¿ 108¿" 10 "108¿ < Winkel ¿ 120¿" 11 "120¿ < Winkel ¿ 132¿" 12 "132¿ < Winkel ¿ 144¿" 13 "144¿ < Winkel ¿ 156¿" 14 "156¿ < Winkel ¿ 168¿" 15 "168¿ < Winkel ¿ 180¿" ;
VAL_ 930 PSD_Sys_TMC_Stau 0 "kein Stau oder keine Information verfuegbar" 1 "Stau" ;
VAL_ 930 PSD_Sys_Bauliche_Trennung 0 "Keine_Trennung" 1 "Bauliche_Trennung" 2 "Nicht_bauliche_Trennung" 3 "Unbekannt" ;
VAL_ 930 PSD_Ges_alter_Geschw 0 "Kein Geschwindigkeitsgebot" 1 "0 km/h < v_max <  5 km/h" 2 "5 km/h ¿ v_max < 10km/h" 3 "10 km/h ¿ v_max < 15 km/h" 4 "15 km/h ¿ v_max < 20 km/h" 5 "20 km/h ¿ v_max < 25 km/h" 6 "25 km/h ¿ v_max < 30 km/h" 7 "30 km/h ¿ v_max < 35 km/h" 8 "35 km/h ¿ v_max < 40 km/h" 9 "40 km/h ¿ v_max < 45 km/h" 10 "45 km/h ¿ v_max < 50 km/h" 11 "50 km/h ¿ v_max < 60 km/h" 12 "60 km/h ¿ v_max < 70 km/h" 13 "70 km/h ¿ v_max < 80 km/h" 14 "80 km/h ¿ v_max < 90 km/h" 15 "90 km/h ¿ v_max < 100 km/h" 16 "100 km/h ¿ v_max < 110 km/h" 17 "110 km/h ¿ v_max < 120 km/h" 18 "120 km/h ¿ v_max < 130 km/h" 19 "130 km/h ¿ v_max < 140 km/h" 20 "140 km/h ¿ v_max < 150 km/h" 21 "150 km/h ¿ v_max < 160 km/h" 22 "160 km/h ¿ v_max" 23 "Geschwindigkeitsgebot aufgehoben" 24 "..0x1F ungültig" ;
VAL_ 930 PSD_Sys_Geometrieguete 0 "Geringe_Guete" 1 "tbd" 2 "tbd" 3 "Hohe_Guete" ;
VAL_ 930 PSD_Abz_Rampe 0 "Straße mit Gegenverkehr" 1 "Auffahrt (Einbahnstr.) " 2 "Abfahrt (Einbahnstr.)" 3 "Einbahnstraße" ;
VAL_ 930 PSD_Sys_Maut 0 "Keine_Mautstelle" 1 "Mautstelle" ;
VAL_ 930 PSD_Abz_Anfangskruemmung 255 "Gerade" ;
VAL_ 930 PSD_Sys_Strassensituation 0 "Unbekannt" 1 "Kreisverkehr" 2 "Zufahrt_zu_Services" 3 "tbd" ;
VAL_ 930 PSD_Ges_alter_Geschw_Gespann 0 "alle Fahrzeuge" 1 "PKW mit Gespann" 2 "LKW, Busse, etc." ;
VAL_ 930 PSD_Sys_StrKlassen_erweitert 0 "Rest_Feldweg_Schotterweg_Privatweg" 1 "Ortsstrasse" 2 "Kreisstrasse" 3 "Landstrasse" 4 "Bundesstrasse" 5 "Autobahn" 6 "Unbekannt" 7 "tbd" ;
VAL_ 930 PSD_Ges_alter_Geschw_Witter 0 "Witterungsunabhängig" 1 "Nässe, Regen, Niederschlag" 2 "Glätte" 3 "Nebel" ;
VAL_ 930 PSD_Sys_Ortsschild 0 "Ortausgangsschild_außerorts" 1 "Ortseingangsschild_ innerorts" ;
VAL_ 930 PSD_Ges_alter_Geschw_Tag_Anf 0 "kein Beginn definiert" 1 "Montag" 2 "Dienstag" 3 "Mittwoch" 4 "Donnerstag" 5 "Freitag" 6 "Samstag" 7 "Sonntag" ;
VAL_ 930 PSD_Abz_Anfangskruemmung_Vorz 0 "Krümmung positiv" 1 "Krümmung negativ" ;
VAL_ 930 PSD_Sys_Anfangskruemmung 255 "Gerade" ;
VAL_ 930 PSD_Abz_Endkruemmung 255 "Gerade" ;
VAL_ 930 PSD_Ges_alter_Geschw_Tag_Ende 0 "kein Ende definiert" 1 "Montag" 2 "Dienstag" 3 "Mittwoch" 4 "Donnerstag" 5 "Freitag" 6 "Samstag" 7 "Sonntag" ;
VAL_ 930 PSD_Ges_alter_Geschw_Std_Anf 25 "kein Beginn für stundenweise Einschränkungen" ;
VAL_ 930 PSD_Sys_Anfangskruemmung_Vorz 0 "Krümmung positiv" 1 "Krümmung negativ" ;
VAL_ 930 PSD_Abz_Endkruemmung_Vorz 0 "Krümmung positiv" 1 "Krümmung negativ" ;
VAL_ 930 PSD_Ges_alter_Geschw_Std_Ende 25 "kein Ende für stundenweise Einschränkungen" ;
VAL_ 930 PSD_Sys_Anfangssteigung 30 "gleich oder mehr als 15 % Steigung" 31 "ungültig" ;
VAL_ 930 PSD_Abz_Endsteigung 30 "gleich oder mehr als 15 % Steigung" 31 "ungültig" ;
VAL_ 930 PSD_Ges_Ueberholverbot 0 "kein Überholverbot" 1 "alle Fahrzeuge" 2 "Überholverbot für PKW mit Gespann" 3 "Überholverbot für LKW, Busse, etc." ;
VAL_ 930 PSD_Sys_Anfangssteigung_Vorz 0 "Gefälle " 1 "Steigung" ;
VAL_ 930 PSD_Abz_Endsteigung_Vorz 0 "Gefälle" 1 "Steigung" ;
VAL_ 930 PSD_Sys_Ortschaft 0 "außerhalb der Ortschaft" 1 "innerhalb der Ortschaft" ;
VAL_ 930 PSD_Abz_Fahrspuren 0 "Einbahnstraße in falscher Richtung" 1 "eine Fahrspur" 2 "zwei Fahrspuren" 3 "mehr als 2 Fahrspuren" ;
VAL_ 930 PSD_Ges_Wechselverkehrszeichen 0 "Kein Wechselverkehrszeichen" 1 "Wechselverkehrszeichen links" 2 "Wechselverkehrszeichen rechts" 3 "Wechselverkehrszeichen links und rechts" 4 "Wechselverkerhszeichen über der Fahrbahn" ;
VAL_ 930 PSD_Sys_Digitalisierung 0 "teildigitalisiert" 1 "volldigitalisiert" ;
VAL_ 930 PSD_Sys_Zielfuehrung 0 "Zielfuehrung nicht aktiv" 1 "Zielfuehrung aktiv" ;
VAL_ 930 PSD_Abz_wahrscheinlichster_Pfad 0 "Pfad mit geringer Wahrscheinlichkeit" 1 "wahrscheinlichster Pfad" ;
VAL_ 1528 SAK_Charisma_FahrPr 0 "nicht_belegt" 1 "Programm_1" 2 "Programm_2" 3 "Programm_3" 4 "Programm_4" 5 "Programm_5" 6 "Programm_6" 7 "Programm_7" ;
VAL_ 1528 SAK_Charisma_Status 0 "Init" 1 "verfuegbar" 2 "nicht_verfuegbar" 3 "asynchron_durch_Fahrerwunsch" ;
VAL_ 1528 SAK_Charisma_Umschaltung 0 "Idle" 1 "Erkennung_Umschaltaufforderung" 2 "Steuerbotschaft_nicht_definiert" 3 "Umschaltung_verzoegert" ;
VAL_ 1528 SAK_KD_Fehler 0 "kein_KD_Fehler" 1 "KD_Fehler" ;
VAL_ 1011 SCR_QBit_Level_Aktivtank_02 0 "gueltiger_Wert" 1 "Ersatz_Init_oder_Fehlerwert" ;
VAL_ 1011 SCR_Level_ReadAbove 0 "Readabove aus" 1 "Readabove aktiv" ;
VAL_ 1011 SCR_Dosierpumpe_Drehzahl 2047 "Fehler" ;
VAL_ 1011 SCR_Druck 1021 "nicht_verbaut" 1023 "Fehler" ;
VAL_ 1011 SCR_Level_Aktivtank 1021 "nicht_verbaut" 1023 "Fehler" ;
VAL_ 1011 SCR_Level_Passivtank 1021 "nicht_verbaut" 1023 "Fehler" ;
VAL_ 1507 SCR_Heizkreis_3_Strom 253 "nicht_verbaut" 255 "Fehler" ;
VAL_ 1507 SCR_KD_Fehler 0 "kein_KD_Fehler" 1 "KD_Fehler" ;
VAL_ 1507 SCR_Guetesensor 1021 "nicht_verbaut" 1023 "Fehler" ;
VAL_ 1507 SCR_Temp_Aktivtank 255 "Fehler" ;
VAL_ 1507 SCR_Temp_Passivtank 253 "nicht_verbaut" 255 "Fehler" ;
VAL_ 1507 SCR_Leitungsheizung_Strom 255 "Fehler" ;
VAL_ 1507 SCR_Transferpumpe_Strom 253 "nicht_verbaut" 255 "Fehler" ;
VAL_ 1507 SCR_Tankheizung_Strom 255 "Fehler" ;
VAL_ 1508 SCR_Spannungsversorgung_Status 0 "kein_Fehler" 1 "KS-" 2 "KS+" 3 "OC" 4 "OOR+(Ueberspannung)" 5 "OOR-(Unterspannung)" 6 "RC+" 7 "RC-" 8 "KS+/OC" 9 "KS-/OC" 10 "KS-/KS+" 11 "KS-/KS+/OC" 12 "OOR+(FktEinschr_Ueberspg)" 13 "OOR-(FktEinschr_Unterspg)" 14 "frei" 15 "Diagnose_noch_nicht_beendet" ;
VAL_ 1508 SCR_VersorgungSensoren_Status 0 "kein_Fehler" 1 "KS-" 2 "KS+" 3 "OC" 4 "OOR+" 5 "OOR-" 6 "RC+" 7 "RC-" 8 "KS+/OC" 9 "KS-/OC" 10 "KS-/KS+" 11 "KS-/KS+/OC" 12 "frei" 13 "frei" 14 "frei" 15 "Diagnose_noch_nicht_beendet" ;
VAL_ 1508 SCR_Heizkreis_3_Status 0 "kein Fehler / Init / nicht verbaut" 1 "KS- (Kurzschluss nach minus)" 2 "KS+ (Kurzschluss nach plus)" 3 "OC (Leitungsunterbrechung)" 4 "OOR+ (Signal zu gross)" 5 "OOR- (Signal zu klein)" 6 "RC+ (Signal unplausibel zu gross)" 7 "RC- (Signal unplausibel zu klein)" 8 "KS+/OC (Kurzschluss nach plus/Unterbrechung)" 9 "KS-/OC  (Kurzschluss nach minus/Unterbrechung)" 10 "KS-/KS+  (Kurzschluss nach minus/plus)" 11 "KS-/KS+/OC (Kurzschluss nach minus/plus/Unterbrechung)" 12 "KS_Heizer" 13 "KS_Pumpe" 14 "frei" 15 "Diagnose_noch_nicht_beendet" ;
VAL_ 1508 SCR_Guetesensor_Status 0 "kein Fehler / Init / nicht verbaut" 1 "KS- (Kurzschluss nach minus)" 2 "KS+ (Kurzschluss nach plus)" 3 "OC (Leitungsunterbrechung)" 4 "OOR+ (Signal zu gross)" 5 "OOR- (Signal zu klein)" 6 "RC+ (Signal unplausibel zu gross)" 7 "RC- (Signal unplausibel zu klein)" 8 "KS+/OC (Kurzschluss nach plus/Unterbrechung)" 9 "KS-/OC  (Kurzschluss nach minus/Unterbrechung)" 10 "KS-/KS+  (Kurzschluss nach minus/plus)" 11 "KS-/KS+/OC (Kurzschluss nach minus/plus/Unterbrechung)" 12 "KS_Heizer" 13 "KS_Pumpe" 14 "frei" 15 "Diagnose_noch_nicht_beendet" ;
VAL_ 1508 SCR_Leitungsheizung_Status 0 "kein Fehler / Init / nicht verbaut" 1 "KS- (Kurzschluss nach minus)" 2 "KS+ (Kurzschluss nach plus)" 3 "OC (Leitungsunterbrechung)" 4 "OOR+ (Signal zu gross)" 5 "OOR- (Signal zu klein)" 6 "RC+ (Signal unplausibel zu gross)" 7 "RC- (Signal unplausibel zu klein)" 8 "KS+/OC (Kurzschluss nach plus/Unterbrechung)" 9 "KS-/OC  (Kurzschluss nach minus/Unterbrechung)" 10 "KS-/KS+  (Kurzschluss nach minus/plus)" 11 "KS-/KS+/OC (Kurzschluss nach minus/plus/Unterbrechung)" 12 "KS_Heizer" 13 "KS_Pumpe" 14 "KS_Heizer_3" 15 "Diagnose_noch_nicht_beendet" ;
VAL_ 1508 SCR_Tankheizung_Status 0 "kein Fehler / Init / nicht verbaut" 1 "KS- (Kurzschluss nach minus)" 2 "KS+ (Kurzschluss nach plus)" 3 "OC (Leitungsunterbrechung)" 4 "OOR+ (Signal zu gross)" 5 "OOR- (Signal zu klein)" 6 "RC+ (Signal unplausibel zu gross)" 7 "RC- (Signal unplausibel zu klein)" 8 "KS+/OC (Kurzschluss nach plus/Unterbrechung)" 9 "KS-/OC  (Kurzschluss nach minus/Unterbrechung)" 10 "KS-/KS+  (Kurzschluss nach minus/plus)" 11 "KS-/KS+/OC (Kurzschluss nach minus/plus/Unterbrechung)" 12 "KS_Heizer" 13 "KS_Pumpe" 14 "frei" 15 "Diagnose_noch_nicht_beendet" ;
VAL_ 1508 SCR_Druck_Status 0 "kein Fehler / Init / nicht verbaut" 1 "KS- (Kurzschluss nach minus)" 2 "KS+ (Kurzschluss nach plus)" 3 "OC (Leitungsunterbrechung)" 4 "OOR+ (Signal zu gross)" 5 "OOR- (Signal zu klein)" 6 "RC+ (Signal unplausibel zu gross)" 7 "RC- (Signal unplausibel zu klein)" 8 "KS+/OC (Kurzschluss nach plus/Unterbrechung)" 9 "KS-/OC  (Kurzschluss nach minus/Unterbrechung)" 10 "KS-/KS+  (Kurzschluss nach minus/plus)" 11 "KS-/KS+/OC (Kurzschluss nach minus/plus/Unterbrechung)" 12 "KS_Heizer" 13 "KS_Pumpe" 14 "frei" 15 "Diagnose_noch_nicht_beendet" ;
VAL_ 1508 SCR_Dosierpumpe_Status_Spule 0 "kein_Fehler" 1 "KS-" 2 "KS+" 3 "OC" 4 "OOR+" 5 "OOR-" 6 "RC+(Drehzahl_zu_hoch)" 7 "RC-(Drehzahl_zu_niedrig)" 8 "KS+/OC" 9 "KS-/OC" 10 "KS-/KS+" 11 "KS-/KS+/OC" 12 "KS_zwischen_Phasen" 13 "KS_Heizer" 14 "KS_Heizer_3" 15 "Diagnose_noch_nicht_beendet" ;
VAL_ 1508 SCR_Transferpumpe_Status 0 "kein Fehler / Init / nicht verbaut" 1 "KS- (Kurzschluss nach minus)" 2 "KS+ (Kurzschluss nach plus)" 3 "OC (Leitungsunterbrechung)" 4 "OOR+ (Signal zu gross)" 5 "OOR- (Signal zu klein)" 6 "RC+ (Signal unplausibel zu gross)" 7 "RC- (Signal unplausibel zu klein)" 8 "KS+/OC (Kurzschluss nach plus/Unterbrechung)" 9 "KS-/OC  (Kurzschluss nach minus/Unterbrechung)" 10 "KS-/KS+  (Kurzschluss nach minus/plus)" 11 "KS-/KS+/OC (Kurzschluss nach minus/plus/Unterbrechung)" 12 "KS_Heizer" 13 "KS_Pumpe" 14 "KS_Heizer_3" 15 "Diagnose_noch_nicht_beendet" ;
VAL_ 1508 SCR_Level_Aktivtank_Status 0 "kein Fehler / Init / nicht verbaut" 1 "KS- (Kurzschluss nach minus)" 2 "KS+ (Kurzschluss nach plus)" 3 "OC (Leitungsunterbrechung)" 4 "OOR+ (Signal zu gross)" 5 "OOR- (Signal zu klein)" 6 "RC+ (Signal unplausibel zu gross)" 7 "RC- (Signal unplausibel zu klein)" 8 "KS+/OC (Kurzschluss nach plus/Unterbrechung)" 9 "KS-/OC  (Kurzschluss nach minus/Unterbrechung)" 10 "KS-/KS+  (Kurzschluss nach minus/plus)" 11 "KS-/KS+/OC (Kurzschluss nach minus/plus/Unterbrechung)" 12 "KS_Heizer" 13 "KS_Pumpe" 14 "frei" 15 "Diagnose_noch_nicht_beendet" ;
VAL_ 1508 SCR_Level_Passivtank_Status 0 "kein Fehler / Init / nicht verbaut" 1 "KS- (Kurzschluss nach minus)" 2 "KS+ (Kurzschluss nach plus)" 3 "OC (Leitungsunterbrechung)" 4 "OOR+ (Signal zu gross)" 5 "OOR- (Signal zu klein)" 6 "RC+ (Signal unplausibel zu gross)" 7 "RC- (Signal unplausibel zu klein)" 8 "KS+/OC (Kurzschluss nach plus/Unterbrechung)" 9 "KS-/OC  (Kurzschluss nach minus/Unterbrechung)" 10 "KS-/KS+  (Kurzschluss nach minus/plus)" 11 "KS-/KS+/OC (Kurzschluss nach minus/plus/Unterbrechung)" 12 "KS_Heizer" 13 "KS_Pumpe" 14 "frei" 15 "Diagnose_noch_nicht_beendet" ;
VAL_ 1508 SCR_Temp_Aktivtank_Status 0 "kein Fehler / Init / nicht verbaut" 1 "KS- (Kurzschluss nach minus)" 2 "KS+ (Kurzschluss nach plus)" 3 "OC (Leitungsunterbrechung)" 4 "OOR+ (Signal zu gross)" 5 "OOR- (Signal zu klein)" 6 "RC+ (Signal unplausibel zu gross)" 7 "RC- (Signal unplausibel zu klein)" 8 "KS+/OC (Kurzschluss nach plus/Unterbrechung)" 9 "KS-/OC  (Kurzschluss nach minus/Unterbrechung)" 10 "KS-/KS+  (Kurzschluss nach minus/plus)" 11 "KS-/KS+/OC (Kurzschluss nach minus/plus/Unterbrechung)" 12 "KS_Heizer" 13 "KS_Pumpe" 14 "frei" 15 "Diagnose_noch_nicht_beendet" ;
VAL_ 1508 SCR_Temp_Passivtank_Status 0 "kein Fehler / Init / nicht verbaut" 1 "KS- (Kurzschluss nach minus)" 2 "KS+ (Kurzschluss nach plus)" 3 "OC (Leitungsunterbrechung)" 4 "OOR+ (Signal zu gross)" 5 "OOR- (Signal zu klein)" 6 "RC+ (Signal unplausibel zu gross)" 7 "RC- (Signal unplausibel zu klein)" 8 "KS+/OC (Kurzschluss nach plus/Unterbrechung)" 9 "KS-/OC  (Kurzschluss nach minus/Unterbrechung)" 10 "KS-/KS+  (Kurzschluss nach minus/plus)" 11 "KS-/KS+/OC (Kurzschluss nach minus/plus/Unterbrechung)" 12 "KS_Heizer" 13 "KS_Pumpe" 14 "frei" 15 "Diagnose_noch_nicht_beendet" ;
VAL_ 1509 SCR_Ansteuerung_Transferpumpe 0 "nicht_aktiv" 1 "aktiv" ;
VAL_ 1509 SCR_Ansteuerung_Dosierpumpe 0 "nicht_aktiv" 1 "aktiv" ;
VAL_ 1509 SCR_Ansteuerung_Heizkreis_3 0 "nicht_aktiv" 1 "aktiv" ;
VAL_ 1509 SCR_Ansteuerung_Leitungsheizung 0 "nicht_aktiv" 1 "aktiv" ;
VAL_ 1509 SCR_Ansteuerung_Tankheizung 0 "nicht_aktiv" 1 "aktiv" ;
VAL_ 1526 SCR_Level_Aktivtank_OOR4Quality 0 "Füllstand i.O. für Qualitätsberechnung" 1 "Füllstand zu niedrig für Qualitätsberechnung" ;
VAL_ 1526 SCR_Level_Aktivtank_OOR_minus 0 "Level erfassbar" 1 "Level zu niedrig" ;
VAL_ 1526 SCR_Sent_1_Signalstatus 0 "kein Fehler" 1 "Sent Signal unplausibel" 2 "Sent Signal TimeOut" 3 "Diagnose noch nicht beendet" ;
VAL_ 1526 SCR_Sent_1_elektrischer_Status 0 "kein Fehler" 1 "KS- " 2 "KS+" 11 "KS_Heizkreis_1" 12 "KS_Heizkreis_2" 13 "KS_Heizkreis_3" 14 "KS_Pumpe" 15 "Diagnose noch nicht beendet" ;
VAL_ 1526 SCR_Sent_Levelsensor 0 "kein Fehler" 1 "Levelsensor defekt" 2 "Sensortemperatur zu hoch" 3 "Sensorversorgung OOR" 7 "Diagnose noch nicht beendet" ;
VAL_ 1526 SCR_Sent_Qualitaetssensor 0 "kein Fehler" 1 "Qualitätssensor defekt" 7 "Diagnose noch nicht beendet" ;
VAL_ 1526 SCR_Sent_Temperatursensor 0 "kein Fehler" 1 "Temperatursensor defekt" 7 "Diagnose noch nicht beendet" ;
VAL_ 1526 SCR_DEF_Qualitaet_Medium 0 "Mediumkonzentration ermittelbar" 1 "Mediumkonzentration nicht ermittelbar" ;
VAL_ 1526 SCR_QBit_Qualitaet 0 "gueltiger_Wert" 1 "Ersatz_Init_oder_Fehlerwert" ;
VAL_ 1526 SCR_Qualitaet 253 "Sensor nicht verbaut" 254 "Init" ;
VAL_ 1526 SCR_Steuergeraet_Heizung_Status 0 "kein_Fehler" 1 "Endstufe_Tankheizung_ueberhitzt" 2 "Endstufe_Leitungsheizung_ueberhitzt" 3 "Diagnose_noch_nicht_beendet" ;
VAL_ 1526 SCR_Steuergeraet_Pumpe_Status 0 "kein_Fehler" 1 "Endstufe_Pumpe_ueberhitzt" 2 "Pumpe_blockiert" 3 "Diagnose_noch_nicht_beendet" ;
VAL_ 1526 SCR_Steuergeraet_Relais_Status 0 "kein_Fehler" 1 "KS+ (Ausgang Leistungsrelais) " 2 "KS-/OC (Ausgang Leistungsrelais)" 3 "Diagnose_noch_nicht_beendet" ;
VAL_ 1526 SCR_Steuergeraet_Bus_Status 0 "kein_Fehler" 1 "Bus_Kommunikation_Fehler" 2 "Bus_Kommunikation_Stoerung_(temporaer)" 3 "Diagnose_noch_nicht_beendet" ;
VAL_ 1526 SCR_Steuergeraet_Datensatz_St002 0 "kein_Fehler" 1 "ungueltiger_Datensatz" 2 "unplausibeler_Datensatz" 3 "Diagnose_noch_nicht_beendet" ;
VAL_ 1526 SCR_Steuergeraet_Defekt_Status 0 "kein_Fehler" 1 "Steuergeraet_defekt" 2 "Steuergeraet_Stoerung_(temporaer)" 3 "Diagnose_noch_nicht_beendet" ;
VAL_ 133 SCU_Ue_Winkel_ADS 4094 "Init" 4095 "Fehler" ;
VAL_ 133 SCU_VZ_Ue_Winkel_ADS 0 "positiv" 1 "negativ" ;
VAL_ 133 SCU_Soll_Ue_Winkel 2046 "Init" 2047 "Fehler" ;
VAL_ 133 SCU_max_Gradient 511 "Fehler" ;
VAL_ 133 SCU_VZ_Soll_Ue_Winkel 0 "positiv" 1 "negativ" ;
VAL_ 133 SCU_Status 0 "betriebsbereit" 1 "Init" 2 "sichere Übersetzung" 3 "Motorsperre verriegelt" 4 "Synchronisierung läuft" ;
VAL_ 133 SCU_KD_Fehler 0 "kein_KD_Fehler" 1 "KD_Fehler" ;
VAL_ 133 SCU_Sensorstatus 0 "iO" 1 "Kalibrierung_aktiv" ;
VAL_ 784 SCU_Warnlampe 0 "keine_Anzeige" 1 "Warnlampe_gelb" 2 "Warnlampe_rot" 3 "Warnlampe_Initialisierung" ;
VAL_ 784 SCU_Warnungen 0 "keine_Anzeige" 1 "DL_Stoerung" 2 "DL_Initialisierung" 3 "DL_Ausfall" ;
VAL_ 784 SCU_Charisma_FahrPr 0 "nicht_belegt" 1 "Programm_1" 2 "Programm_2" 3 "Programm_3" 4 "Programm_4" 5 "Programm_5" 6 "Programm_6" 7 "Programm_7" ;
VAL_ 784 SCU_Charisma_Status 0 "Init" 1 "verfuegbar" 2 "nicht_verfuegbar" 3 "asynchron_durch_Fahrerwunsch" ;
VAL_ 784 SCU_Charisma_Umschaltung 0 "Idle" 1 "Erkennung_Umschaltaufforderung" 2 "Steuerbotschaft_nicht_definiert" 3 "Umschaltung_verzoegert" ;
VAL_ 1313 STH_Funk_ein 0 "kein Funkbefehl zum Einschalten" 1 "Funkbefehl zum Einschalten erhalten" ;
VAL_ 1313 STH_Funk_aus 0 "kein Funkbefehl" 1 "Funkbefehl zum Ausschalten erhalten" ;
VAL_ 1313 STH_Zusatzheizung 0 "Zuheizer aus" 1 "Zuheizer ein" ;
VAL_ 1313 STH_LED 0 "keine Rückmeldung" 1 "Rueckmeldung Standheizung in Betrieb" ;
VAL_ 1313 STH_Geblaese 0 "kein Einschaltbefehl an die Klimaanlage, Gebläse" 1 "Einschaltbefehl an die Klimaanlage, Gebläse" ;
VAL_ 1313 STH_EKP_Anst 0 "EKP nicht ansteuern" 1 "EKP ansteuern" ;
VAL_ 1313 STH_Start_folgt 0 "kein_Start_folgt" 1 "Start_folgt" ;
VAL_ 1313 STH_Ventil_Status 0 "Ventil_offen__grosser_Kreislauf" 1 "Ventil_geschlossen__kleiner_Kreislauf" ;
VAL_ 1313 STH_Fehler_ElWaPu 0 "kein_Fehler" 1 "Fehler" ;
VAL_ 1313 STH_Pumpen_Anf_extern 0 "nicht_angefordert" 1 "angefordert" ;
VAL_ 1313 STH_Fehlerstatus 0 "kein_Fehler" 1 "Unterspannung" 2 "Tankfuellstand_zu_gering" 3 "Fehler_Betrieb_verhindert" 4 "Heizgeraet_verriegelt" 5 "Fehler_Betrieb_nicht_verhindert" 6 "Emissionsüberschreitung" ;
VAL_ 1313 STH_Wassertemp 254 "Init" 255 "Fehler" ;
VAL_ 1313 STH_Texte 0 "keine_Anzeige" 1 "Batteriemanagementeinschraenkung" 2 "Kraftstoffmangel" 3 "interner_Systemfehler" ;
VAL_ 1313 STH_Motorvorwaermung 0 "keine Motorvorwärmung erfolgt" 1 "Aufheizung mit Motorvorwärmung erfolgt" ;
VAL_ 1313 STH_war_aktiv 0 "war inaktiv" 1 "Standheizung war letzte halbe Stunde aktiv" ;
VAL_ 1313 STH_KVS_Ueberlauf 0 "kein Überlauf" 1 "Kraftstoffverbrauchssignal, mindestens ein Überlauf hat stattgefunden" ;
VAL_ 1313 STH_KD_Fehler 0 "kein_KD_Fehler" 1 "KD_Fehler" ;
VAL_ 1172 STS_Car_not_under_theft 0 "false" 1 "true" ;
VAL_ 1172 STS_Car_under_theft 0 "false" 1 "true" ;
VAL_ 1172 STS_Anlassersperre 0 "inaktiv" 1 "aktiv" ;
VAL_ 1172 STS_Typencodierung 0 "Basis" 1 "E-Gas" 4 "Sonderschutz" ;
VAL_ 1172 STS_KD_Fehler 0 "kein_KD_Fehler" 1 "KD_Fehler" ;
VAL_ 1172 STS_Standlicht 0 "inaktiv" 1 "aktiv" ;
VAL_ 1172 STS_Fahrlicht 0 "inaktiv" 1 "aktiv" ;
VAL_ 1172 STS_Alarm_still 0 "inaktiv" 1 "aktiv" ;
VAL_ 1172 STS_Texte 0 "kein_Text" 1 "Text_01" 2 "Text_02" 3 "Text_03" 4 "Text_04" 5 "Text_05" 6 "Text_06" 7 "Text_07" 8 "Text_08" 9 "Text_09" 10 "Text_10" 11 "Text_11" 12 "Text_12" 13 "Text_13" 14 "Init" 15 "Fehler" ;
VAL_ 1172 STS_Laderelais 0 "Relais_offen" 1 "Relais_geschlossen" ;
VAL_ 1172 STS_Summer 0 "inaktiv" 1 "aktiv" ;
VAL_ 1172 STS_Notstart 0 "kein_Notstart" 1 "Notstart" ;
VAL_ 1172 STS_Signalhorn 0 "inaktiv" 1 "aktiv" ;
VAL_ 1172 STS_Leerlaufschaltung 0 "inaktiv" 1 "aktiv" ;
VAL_ 1413 SI_Int_CAN_gespiegelt 0 "interner CAN getrennt" 1 "interner CAN gespiegelt" ;
VAL_ 1413 SI_CAN_Komfort_Sleep 0 "keine_Busruhe" 1 "Busruhe" ;
VAL_ 1413 SI_CAN_Dashboard_Sleep 0 "keine_Busruhe" 1 "Busruhe" ;
VAL_ 1413 SI_CAN_Antrieb_Sleep 0 "keine_Busruhe" 1 "Busruhe" ;
VAL_ 1413 SI_Infotainment_Sleep 0 "keine_Busruhe" 1 "Busruhe" ;
VAL_ 1413 SI_CAN_Extended_Sleep 0 "keine_Busruhe" 1 "Busruhe" ;
VAL_ 1413 SI_Fahrwerk_Sleep 0 "keine_Busruhe" 1 "Busruhe" ;
VAL_ 1413 SI_Diagnose_Aktiv 0 "inaktiv" 1 "aktiv" ;
VAL_ 1413 SI_QRS_Mode 0 "QRS_Messmodus_nicht_aktiv" 1 "QRS_Messmodus_aktiv" ;
VAL_ 1413 SI_T_Mode 0 "Transportmodus_nicht_aktiv" 1 "Transportmodus_aktiv" ;
VAL_ 1413 SI_NWDF 0 "Ueberwachung_nicht_freigegeben" 1 "Ueberwachung_freigegeben" ;
VAL_ 1413 SI_NWDF_gueltig 0 "NWDF_wird_nicht_unterstuetzt" 1 "NWDF_wird_unterstuetzt" ;
VAL_ 1413 SI_Sammelfehler 0 "kein_Sammelfehler" 1 "Sammelfehler" ;
VAL_ 1413 GW_KD_Fehler 0 "kein_KD_Fehler" 1 "KD_Fehler" ;
VAL_ 1413 SI_T_Schutz 0 "Transportschutz_nicht_aktiv" 1 "Transportschutz_aktiv" ;
VAL_ 1413 SI_MOST_Status 0 "MOST_sleep_(Licht_AUS)" 1 "MOST_aktiv_(Kommunikation_moeglich)" ;
VAL_ 1413 SI_Sammel_SG_Fehler 61 "Reserviert" 62 "Overflow" 63 "ungueltig" ;
VAL_ 1413 SI_CAN_Hybrid_Sleep 0 "keine_Busruhe" 1 "Busruhe" ;
VAL_ 1413 SI_MO_WU 0 "kein Wakeup angefordert" 1 "Wakeup MED9 angefordert" ;
VAL_ 786 FAS_Wunschgeschw 1022 "keine Anzeige" 1023 "nicht definiert" ;
VAL_ 786 FAS_Status_Prim_Anz 0 "Symbol nicht beleuchtet" 1 "Farbe 1 (typisch 'grün')" 2 "Farbe 2 (typisch 'rot')" 3 "Farbe 3 (typisch 'gelb')" ;
VAL_ 786 FAS_Texte_Primaeranz 0 "keine Anzeige " 1 "ACC nicht verfuegbar !" 2 "Auto_Auto_ _ _" 3 "Auto_ _Auto_ _" 4 "Auto_ _ _Auto_" 5 "Auto_ _ _ _Auto" 6 "Auto_Auto_ _ _ Gong (durchgestrichen)" 7 "Auto_ _Auto_ _ Gong (durchgestrichen)" 8 "Auto_ _ _Auto_ Gong (durchgestrichen)" 9 "Auto_ _ _ _Auto Gong (durchgestrichen)" 10 "ACC bereit" 11 "keine Abstandsregelung" 12 "ACC Sensor Sicht !" 13 "ACC nicht verfuegbar" 14 "o  o  o" 15 "Hochschalten" 16 "ESP Eingriff" 17 "Herunterschalten" 18 "Parkbremse !" 19 "Geschwindigkeitsgrenze" 20 "Waehlhebelposition !" 21 "VDA ACC-Symbol YYY km/h / mph" 22 "Tempolimit XXX km/h / mph" 23 "Kurve XXX km/h / mph" 24 "ACC Abschaltung" 25 "Symbol 'Eieruhr'" 26 "!" 27 "--- km/h / mph" 28 "XXX km/h / mph (Schriftart 2)" 29 "Lenkradwinkel" 30 "Anfahren bestaetigen" 31 "Fahrzeug verloren" 32 "Im Stand nicht moeglich" 33 "Ungueltiger Anfahrbefehl" 34 "Tuer offen !" 35 "Fahrer Gurtschloss offen !" 36 "Schalthebelposition !" 37 "Drehzahl !" 38 "Kurvenassistent aus" 39 "Tempolimit aus" 40 "Abbiegeassistent" 41 "Ortsanfang XXX km/h / mph" 42 "Ortsende XXX km/h / mph" 43 "Tempolimit Ende XXX km/h / mph" 44 "HDC aktiv" 45 "braking guard Bremsruck" 46 "braking guard aus " 47 "braking guard aus" 48 "Uebernehmen !" 49 "Steigung zu gross" 50 "Stehendes Objekt voraus" 51 "SET / 'GRA Symbol'___xxx km/h / mph" 52 "SET / 'GRA Symbol' xxx km/h / mph" 53 "ACC aus" 54 "ACC startet" 55 "ACC reinigen" 56 "ACC Fehler" 57 "ACC haelt an !" 58 "Bremse betaetigen !" 59 "Kupplung betaetigt" 60 "LIM AUS" 61 "LIM AKTIV " 62 "LIM PASSIV" 63 "LIM FEHLER" 64 "Bremse ueberhitzt !" 65 "Bremse haelt !" 66 "ESP PASSIV !" ;
VAL_ 786 FAS_Status_Anzeige 0 "ACC/GRA Hauptschalter aus" 1 "ACC in Init (nicht bei GRA)" 2 "ACC/GRA passiv" 3 "ACCGRA aktiv" 4 "ACC/GRA im Hintergrund (übertreten)" 5 "frei" 6 "ACC reversibel aus (nicht bei GRA)" 7 "ACC/GRA irreversibel aus" ;
VAL_ 270 TSK_ax_Getriebe 511 "nicht definiert" ;
VAL_ 270 TSK_Wunsch_Uebersetz 0 "Init" ;
VAL_ 270 TSK_Freig_WU 0 "TSK_Uebersetzungswunsch_nicht_freigegeben" 1 "TSK_Uebersetzungswunsch_freigegeben" ;
VAL_ 270 TSK_Limiter_aktiv 0 "Speed Limiter ist nicht aktiv" 1 "Speed Limiter aktiv und regelt" ;
VAL_ 270 TSK_Status_GRA_ACC_02 0 "nicht verbaut / kein ACC zulässig" 1 "GRA / ACC aktiv " 2 "GRA / ACC vom Fahrer übersteuert" 3 "Fehler, GRA/ACC nicht möglich " ;
VAL_ 273 TSK_QBit_Steigung 0 "gueltiger_Wert" 1 "Ersatz_Init_oder_Fehlerwert" ;
VAL_ 273 TSK_Status_GRA_ACC_01 0 "nicht_verbaut_kein_ACC_zulaessig" 1 "GRA_ACC_aktiv" 2 "GRA_ACC_vom_Fahrer_uebersteuert" 3 "Fehler_GRA_ACC_nicht_moeglich" ;
VAL_ 273 TSK_Fahrzeugmasse 31 "Fehler" ;
VAL_ 273 TSK_QBit_Fahrzeugmasse 0 "gueltiger_Wert" 1 "Ersatz_Init_oder_Fehlerwert" ;
VAL_ 273 TSK_Fahrzeugmasse_02 255 "Fehler" ;
VAL_ 273 TSK_Steigung 255 "Fehler" ;
VAL_ 273 TSK_Getriebeinfo 0 "Handschalter" 1 "AL_AQ_Getriebe" 2 "DL_DQ_Getriebe" 3 "CVT_Getriebe" ;
VAL_ 273 TSK_Codierung_ACC 0 "TSK_korrekt_auf_kein_ACC_codiert_oder_TSK_falsch_codiert" 1 "TSK_korrekt_auf_ACC_codiert" ;
VAL_ 273 TSK_Zwangszusch_ESP 0 "keine_ESP_ASR_Beeinflussung" 1 "ESP_ASR_Beeinflussung" ;
VAL_ 273 TSK_Freig_Verzoeg_Anf 0 "Verzoegerungsanforderung_nicht_freigegeben" 1 "Verzoegerungsanforderung_freigegeben" ;
VAL_ 1414 WH_KD_Fehler 0 "kein_KD_Fehler" 1 "KD_Fehler" ;
VAL_ 915 WBA_Senderkennung 0 "Getriebe" 1 "Motor" ;
VAL_ 915 WBA_Lampe_Shift_Lock 0 "SL_Lampe_aus" 1 "SL_Lampe_ein" ;
VAL_ 915 WBA_Schaltempf_verfbar 0 "nicht verfügbar" 1 "verfügbar" ;
VAL_ 915 WBA_Effizienzmodus 0 "nicht_im_Effizienz_Modus" 1 "Effizienz_Modus" ;
VAL_ 915 WBA_Kurzzeittipp 0 "Kein_Kurzzeittipp" 1 "Kurzzeittipp" ;
VAL_ 915 WBA_Blinken 0 "kein_WBA_Blinken" 1 "WBA_Blinken" ;
VAL_ 915 WBA_Getriebevariante 1 "Automat PRND" 2 "tbd." 3 "tbd." 4 "Vorhalt für ASG (Selespeed)" 5 "tbd." 6 "Automat PRNDS" 7 "tbd." 8 "2x3 shift_by_wire" 9 "tbd." 10 "tbd." 11 "5 Gang Automat Tiptronic" 12 "6 Gang Automat Tiptronic" 13 "7 Gang Automat Tiptronic" 14 "8 Gang Automat Tiptronic" 15 "9 Gang Automat Tiptronic" ;
VAL_ 915 WBA_GE_Warnung 0 "keine Anzeige" 1 "Weiterfahrt möglich (+ gelbes Getriebefehlersymbol)" 2 "Weiterfahrt nur eingeschränkt möglich (+ gelbes Getriebefehlersymbol)" 3 "nur DL-Getriebe: Weiterfahrt nur eingeschränkt möglich. Kein R-Gang" 4 "Getriebefehler, Weiterfahrt nur in D moeglich, P bei Motor aus" 5 "Wegrollgefahr! P nicht möglich" 6 "Kupplung ueberhitzt, Fahrzeug Stopp (+ gelbes Getriebefehlersymbol)" 7 "Kupplung ueberhitzt, Fahrzeug Stopp (+ rotes Getriebefehlersymbol)" ;
VAL_ 915 WBA_Istgang 0 "kein Gang eingelegt" 1 "1.Gang" 2 "2.Gang" 3 "3.Gang" 4 "4.Gang" 5 "5.Gang" 6 "6.Gang" ;
VAL_ 915 WBA_eing_Gang 0 "kein Gang eingelegt / kein Gang empfohlen" 1 "Init" 2 "1.Gang" 3 "2.Gang" 4 "3.Gang" 5 "4.Gang" 6 "5.Gang" 7 "6.Gang" 8 "7.Gang" 9 "8.Gang" 10 "9.Gang" ;
VAL_ 915 WBA_Sollgang 0 "keine Empfehlung" 1 "1.Gang" 2 "2.Gang" 3 "3.Gang" 4 "4.Gang" 5 "5.Gang" 6 "6.Gang" ;
VAL_ 915 WBA_GE_Texte 0 "keine_Anzeige" 1 "zum_Einlegen_einer_Fahrstufe_Fussbremse_betaetigen__ShiftLock_Information" 2 "zum_Einlegen_von_R_N_D_Fussbremse_betaetigen_und_Motor_starten" 3 "Wegrollgefahr_bitte_P_einlegen" 4 "Achtung_Zeitueberschreitung_P_wird_eingelegt" 5 "Wiederanmeldeprozedur_Bremse_betaetigen" 6 "P_nur_im_Stillstand_moeglich" 7 "Rennstart_aktiv" ;
VAL_ 915 WBA_Schaltschema_Aktiv 0 "keine_Anzeige" 1 "Schaltschema_anzeigen" ;
VAL_ 915 WH_Warnung 0 "keine_Anzeige" 1 "Waehlhebelfehler_Fahrstufenwechsel_moeglich_(gelbes_Getriebesymbol)" ;
VAL_ 915 WBA_GE_Zusatzwarnungen 0 "keine_Anzeige" 1 "Getriebeueberhitzung_Warnstufe_I" 2 "Getriebeueberhitzung_Warnstufe_II" 3 "Getriebefehler_Bitte_anhalten_und_P_einlegen" ;
VAL_ 915 WBA_Segeln_aktiv 0 "inaktiv" 1 "aktiv" ;
VAL_ 915 GE_Tipschaltempf_verfuegbar 0 "nicht_verfuegbar" 1 "verfuegbar" ;
VAL_ 915 GE_Sollgang 0 "keine_Empfehlung" 1 "Gang_1" 2 "Gang_2" 3 "Gang_3" 4 "Gang_4" 5 "Gang_5" 6 "Gang_6" 7 "Gang_7" 8 "Gang_8" 9 "Gang_9" ;
VAL_ 1602 WIV_Verschleissindex 65535 "Fehler" ;
VAL_ 1602 WIV_Russindex 65535 "Fehler" ;
